VERSION ""

NS_ :

BS_:

BU_: EHR_Spare FEHR_3 PTO_SpeedSelector Dummy_Node_Ch2 FEHR_2 TrailerBrake OffBoardDiagnosticTool1_Ch2 PowerTakeOff_Ch2 Transmission1_Ch2 FEHR_1 REHR_5 REHR_4 REHR_3 REHR_2 REHR_1 InstrumentCluster_Ch2 ManagementComputer_Ch2 GWAY_OnBoardDiagnosticUnit_Ch2 GWAY_OffBoardDiagTool1_VB1_Ch2 GWAY_Engine1_Ch2 GWAY_CabDisplay1_Ch2 AuxiliaryValveControl_Ch2

BO_ 2566866052 PB_EHR_ParameterStatus_84: 8 REHR_5
 SG_ EHR_ChksumStor m80 : 32|8@1+ (1,0) [0|255] ""  AuxiliaryValveControl_Ch2
 SG_ EHR_ChksumSW m80 : 40|8@1+ (1,0) [0|255] ""  AuxiliaryValveControl_Ch2
 SG_ EHR_EvNumParamMux_12 : 24|8@1+ (1,0) [0|255] ""  AuxiliaryValveControl_Ch2
 SG_ EHR_ParamByte_1 : 0|8@1+ (1,0) [0|255] ""  AuxiliaryValveControl_Ch2
 SG_ EHR_ParamStsByte_2 : 8|8@1+ (1,0) [0|255] ""  AuxiliaryValveControl_Ch2
 SG_ EHR_ParamStsByte_3 M : 16|8@1+ (1,0) [0|255] ""  AuxiliaryValveControl_Ch2
 SG_ EHR_RmpRndng m103 : 32|8@1+ (1,0) [0|255] ""  AuxiliaryValveControl_Ch2

BO_ 2566866057 PB_EHR_ParameterStatus_89: 8 FEHR_1
 SG_ EHR_ChksumStor m80 : 32|8@1+ (1,0) [0|255] ""  AuxiliaryValveControl_Ch2
 SG_ EHR_ChksumSW m80 : 40|8@1+ (1,0) [0|255] ""  AuxiliaryValveControl_Ch2
 SG_ EHR_EvNumParamMux_12 : 24|8@1+ (1,0) [0|255] ""  AuxiliaryValveControl_Ch2
 SG_ EHR_ParamByte_1 : 0|8@1+ (1,0) [0|255] ""  AuxiliaryValveControl_Ch2
 SG_ EHR_ParamStsByte_2 : 8|8@1+ (1,0) [0|255] ""  AuxiliaryValveControl_Ch2
 SG_ EHR_ParamStsByte_3 M : 16|8@1+ (1,0) [0|255] ""  AuxiliaryValveControl_Ch2
 SG_ EHR_RmpRndng m103 : 32|8@1+ (1,0) [0|255] ""  AuxiliaryValveControl_Ch2

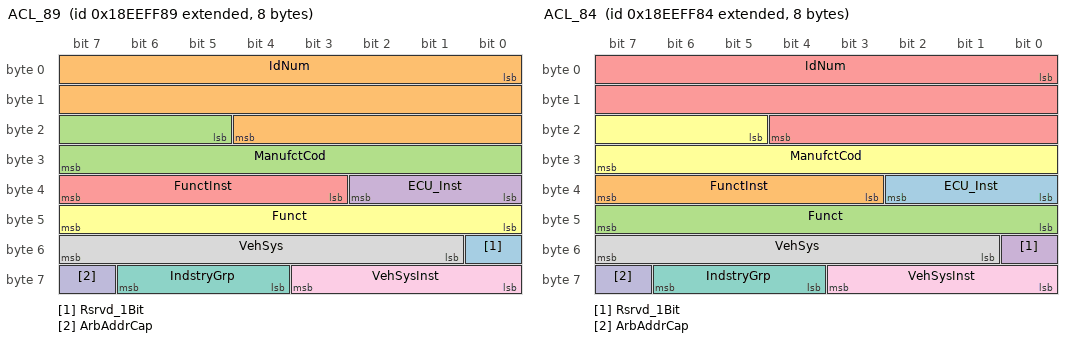
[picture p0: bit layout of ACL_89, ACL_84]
BO_ 2565799817 ACL_89: 8 FEHR_1
 SG_ Rsrvd_1Bit : 48|1@1+ (1,0) [0|1] ""  OffBoardDiagnosticTool1_Ch2,AuxiliaryValveControl_Ch2
 SG_ IdNum : 0|21@1+ (1,0) [0|2097151] ""  OffBoardDiagnosticTool1_Ch2,AuxiliaryValveControl_Ch2
 SG_ ManufctCod : 21|11@1+ (1,0) [0|2047] ""  OffBoardDiagnosticTool1_Ch2,AuxiliaryValveControl_Ch2
 SG_ ECU_Inst : 32|3@1+ (1,0) [0|7] ""  OffBoardDiagnosticTool1_Ch2,AuxiliaryValveControl_Ch2
 SG_ FunctInst : 35|5@1+ (1,0) [0|31] ""  OffBoardDiagnosticTool1_Ch2,AuxiliaryValveControl_Ch2
 SG_ Funct : 40|8@1+ (1,0) [0|255] ""  OffBoardDiagnosticTool1_Ch2,AuxiliaryValveControl_Ch2
 SG_ IndstryGrp : 60|3@1+ (1,0) [0|7] ""  OffBoardDiagnosticTool1_Ch2,AuxiliaryValveControl_Ch2
 SG_ VehSys : 49|7@1+ (1,0) [0|127] ""  OffBoardDiagnosticTool1_Ch2,AuxiliaryValveControl_Ch2
 SG_ VehSysInst : 56|4@1+ (1,0) [0|15] ""  OffBoardDiagnosticTool1_Ch2,AuxiliaryValveControl_Ch2
 SG_ ArbAddrCap : 63|1@1+ (1,0) [0|1] ""  OffBoardDiagnosticTool1_Ch2,AuxiliaryValveControl_Ch2

BO_ 2565799812 ACL_84: 8 REHR_5
 SG_ ECU_Inst : 32|3@1+ (1,0) [0|7] ""  OffBoardDiagnosticTool1_Ch2,AuxiliaryValveControl_Ch2
 SG_ FunctInst : 35|5@1+ (1,0) [0|31] ""  OffBoardDiagnosticTool1_Ch2,AuxiliaryValveControl_Ch2
 SG_ Funct : 40|8@1+ (1,0) [0|255] ""  OffBoardDiagnosticTool1_Ch2,AuxiliaryValveControl_Ch2
 SG_ Rsrvd_1Bit : 48|1@1+ (1,0) [0|1] ""  OffBoardDiagnosticTool1_Ch2,AuxiliaryValveControl_Ch2
 SG_ IdNum : 0|21@1+ (1,0) [0|2097151] ""  OffBoardDiagnosticTool1_Ch2,AuxiliaryValveControl_Ch2
 SG_ ManufctCod : 21|11@1+ (1,0) [0|2047] ""  OffBoardDiagnosticTool1_Ch2,AuxiliaryValveControl_Ch2
 SG_ IndstryGrp : 60|3@1+ (1,0) [0|7] ""  OffBoardDiagnosticTool1_Ch2,AuxiliaryValveControl_Ch2
 SG_ VehSys : 49|7@1+ (1,0) [0|127] ""  OffBoardDiagnosticTool1_Ch2,AuxiliaryValveControl_Ch2
 SG_ VehSysInst : 56|4@1+ (1,0) [0|15] ""  OffBoardDiagnosticTool1_Ch2,AuxiliaryValveControl_Ch2
 SG_ ArbAddrCap : 63|1@1+ (1,0) [0|1] ""  OffBoardDiagnosticTool1_Ch2,AuxiliaryValveControl_Ch2

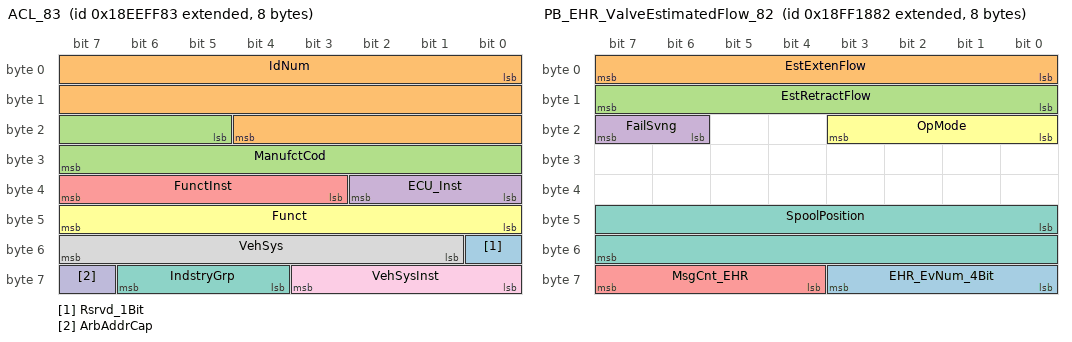
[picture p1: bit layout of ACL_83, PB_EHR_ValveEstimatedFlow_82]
BO_ 2565799811 ACL_83: 8 REHR_4
 SG_ Rsrvd_1Bit : 48|1@1+ (1,0) [0|1] ""  OffBoardDiagnosticTool1_Ch2,AuxiliaryValveControl_Ch2
 SG_ IdNum : 0|21@1+ (1,0) [0|2097151] ""  OffBoardDiagnosticTool1_Ch2,AuxiliaryValveControl_Ch2
 SG_ ManufctCod : 21|11@1+ (1,0) [0|2047] ""  OffBoardDiagnosticTool1_Ch2,AuxiliaryValveControl_Ch2
 SG_ ECU_Inst : 32|3@1+ (1,0) [0|7] ""  OffBoardDiagnosticTool1_Ch2,AuxiliaryValveControl_Ch2
 SG_ FunctInst : 35|5@1+ (1,0) [0|31] ""  OffBoardDiagnosticTool1_Ch2,AuxiliaryValveControl_Ch2
 SG_ Funct : 40|8@1+ (1,0) [0|255] ""  OffBoardDiagnosticTool1_Ch2,AuxiliaryValveControl_Ch2
 SG_ IndstryGrp : 60|3@1+ (1,0) [0|7] ""  OffBoardDiagnosticTool1_Ch2,AuxiliaryValveControl_Ch2
 SG_ VehSys : 49|7@1+ (1,0) [0|127] ""  OffBoardDiagnosticTool1_Ch2,AuxiliaryValveControl_Ch2
 SG_ VehSysInst : 56|4@1+ (1,0) [0|15] ""  OffBoardDiagnosticTool1_Ch2,AuxiliaryValveControl_Ch2
 SG_ ArbAddrCap : 63|1@1+ (1,0) [0|1] ""  OffBoardDiagnosticTool1_Ch2,AuxiliaryValveControl_Ch2

BO_ 2566854786 PB_EHR_ValveEstimatedFlow_82: 8 REHR_3
 SG_ EHR_EvNum_4Bit : 56|4@1+ (1,0) [0|15] ""  AuxiliaryValveControl_Ch2
 SG_ EstExtenFlow : 0|8@1+ (0.8,-102.4) [0|100] "%"  AuxiliaryValveControl_Ch2
 SG_ EstRetractFlow : 8|8@1+ (0.8,-102.4) [0|100] "%"  AuxiliaryValveControl_Ch2
 SG_ FailSvng : 22|2@1+ (1,0) [0|3] ""  AuxiliaryValveControl_Ch2
 SG_ MsgCnt_EHR : 60|4@1+ (1,0) [0|12] "count"  AuxiliaryValveControl_Ch2
 SG_ OpMode : 16|4@1+ (1,0) [0|15] ""  AuxiliaryValveControl_Ch2
 SG_ SpoolPosition : 40|16@1+ (1,0) [0|1023] ""  AuxiliaryValveControl_Ch2

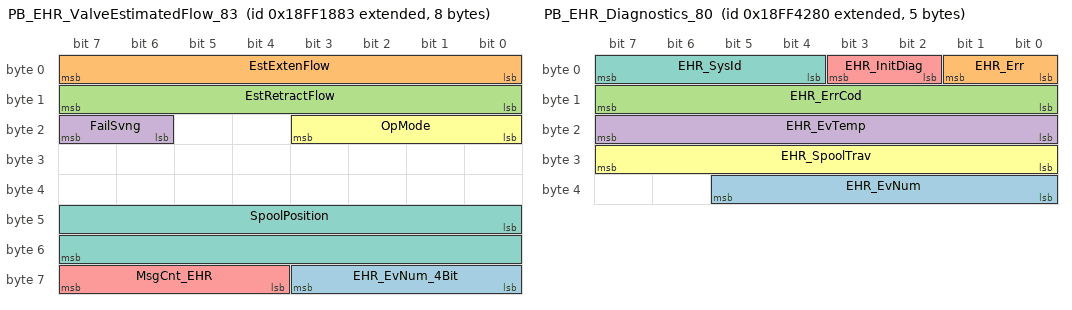
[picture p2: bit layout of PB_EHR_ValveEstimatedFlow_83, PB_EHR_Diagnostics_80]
BO_ 2566854787 PB_EHR_ValveEstimatedFlow_83: 8 REHR_4
 SG_ EHR_EvNum_4Bit : 56|4@1+ (1,0) [0|15] ""  AuxiliaryValveControl_Ch2
 SG_ EstExtenFlow : 0|8@1+ (0.8,-102.4) [0|100] "%"  AuxiliaryValveControl_Ch2
 SG_ EstRetractFlow : 8|8@1+ (0.8,-102.4) [0|100] "%"  AuxiliaryValveControl_Ch2
 SG_ FailSvng : 22|2@1+ (1,0) [0|3] ""  AuxiliaryValveControl_Ch2
 SG_ MsgCnt_EHR : 60|4@1+ (1,0) [0|12] "count"  AuxiliaryValveControl_Ch2
 SG_ OpMode : 16|4@1+ (1,0) [0|15] ""  AuxiliaryValveControl_Ch2
 SG_ SpoolPosition : 40|16@1+ (1,0) [0|1023] ""  AuxiliaryValveControl_Ch2

BO_ 2566865536 PB_EHR_Diagnostics_80: 5 REHR_1
 SG_ EHR_EvNum : 32|6@1+ (1,0) [0|63] ""  AuxiliaryValveControl_Ch2
 SG_ EHR_Err : 0|2@1+ (1,0) [0|3] ""  AuxiliaryValveControl_Ch2
 SG_ EHR_ErrCod : 8|8@1+ (1,0) [0|254] ""  AuxiliaryValveControl_Ch2
 SG_ EHR_EvTemp : 16|8@1+ (1,-80) [-40|120] "Deg C"  AuxiliaryValveControl_Ch2
 SG_ EHR_InitDiag : 2|2@1+ (1,0) [0|3] ""  AuxiliaryValveControl_Ch2
 SG_ EHR_SpoolTrav : 24|8@1+ (1,0) [0|254] ""  AuxiliaryValveControl_Ch2
 SG_ EHR_SysId : 4|4@1+ (1,0) [0|15] ""  AuxiliaryValveControl_Ch2

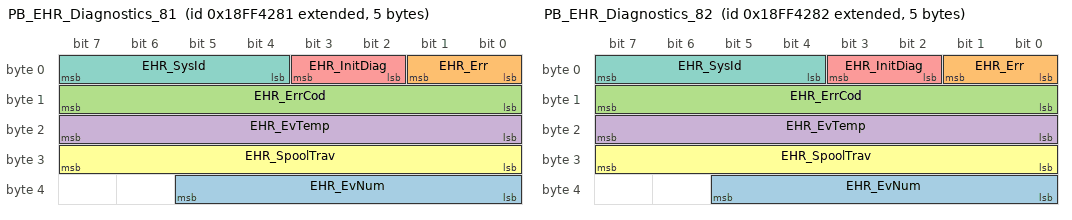
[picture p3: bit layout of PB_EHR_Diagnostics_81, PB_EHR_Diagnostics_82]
BO_ 2566865537 PB_EHR_Diagnostics_81: 5 REHR_2
 SG_ EHR_EvNum : 32|6@1+ (1,0) [0|63] ""  AuxiliaryValveControl_Ch2
 SG_ EHR_Err : 0|2@1+ (1,0) [0|3] ""  AuxiliaryValveControl_Ch2
 SG_ EHR_ErrCod : 8|8@1+ (1,0) [0|254] ""  AuxiliaryValveControl_Ch2
 SG_ EHR_EvTemp : 16|8@1+ (1,-80) [-40|120] "Deg C"  AuxiliaryValveControl_Ch2
 SG_ EHR_InitDiag : 2|2@1+ (1,0) [0|3] ""  AuxiliaryValveControl_Ch2
 SG_ EHR_SpoolTrav : 24|8@1+ (1,0) [0|254] ""  AuxiliaryValveControl_Ch2
 SG_ EHR_SysId : 4|4@1+ (1,0) [0|15] ""  AuxiliaryValveControl_Ch2

BO_ 2566865538 PB_EHR_Diagnostics_82: 5 REHR_3
 SG_ EHR_EvNum : 32|6@1+ (1,0) [0|63] ""  AuxiliaryValveControl_Ch2
 SG_ EHR_Err : 0|2@1+ (1,0) [0|3] ""  AuxiliaryValveControl_Ch2
 SG_ EHR_ErrCod : 8|8@1+ (1,0) [0|254] ""  AuxiliaryValveControl_Ch2
 SG_ EHR_EvTemp : 16|8@1+ (1,-80) [-40|120] "Deg C"  AuxiliaryValveControl_Ch2
 SG_ EHR_InitDiag : 2|2@1+ (1,0) [0|3] ""  AuxiliaryValveControl_Ch2
 SG_ EHR_SpoolTrav : 24|8@1+ (1,0) [0|254] ""  AuxiliaryValveControl_Ch2
 SG_ EHR_SysId : 4|4@1+ (1,0) [0|15] ""  AuxiliaryValveControl_Ch2

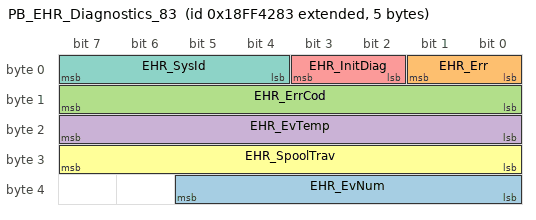
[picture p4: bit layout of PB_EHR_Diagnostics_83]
BO_ 2566865539 PB_EHR_Diagnostics_83: 5 REHR_4
 SG_ EHR_EvNum : 32|6@1+ (1,0) [0|63] ""  AuxiliaryValveControl_Ch2
 SG_ EHR_Err : 0|2@1+ (1,0) [0|3] ""  AuxiliaryValveControl_Ch2
 SG_ EHR_ErrCod : 8|8@1+ (1,0) [0|254] ""  AuxiliaryValveControl_Ch2
 SG_ EHR_EvTemp : 16|8@1+ (1,-80) [-40|120] "Deg C"  AuxiliaryValveControl_Ch2
 SG_ EHR_InitDiag : 2|2@1+ (1,0) [0|3] ""  AuxiliaryValveControl_Ch2
 SG_ EHR_SpoolTrav : 24|8@1+ (1,0) [0|254] ""  AuxiliaryValveControl_Ch2
 SG_ EHR_SysId : 4|4@1+ (1,0) [0|15] ""  AuxiliaryValveControl_Ch2

BO_ 2566834816 DM1_80: 18 REHR_1
 SG_ DTC_02 : 48|32@1+ (1,0) [0|4294970000] ""  InstrumentCluster_Ch2
 SG_ DTC_03 : 80|32@1+ (1,0) [0|4294970000] ""  InstrumentCluster_Ch2
 SG_ DTC_04 : 112|32@1+ (1,0) [0|4294970000] ""  InstrumentCluster_Ch2
 SG_ AmbrWarnLmp : 2|2@1+ (1,0) [0|3] ""  InstrumentCluster_Ch2,AuxiliaryValveControl_Ch2
 SG_ DTC_01 : 16|32@1+ (1,0) [0|4294970000] ""  InstrumentCluster_Ch2,AuxiliaryValveControl_Ch2
 SG_ FlashAmbrWarnLmpAWL : 10|2@1+ (1,0) [0|3] ""  InstrumentCluster_Ch2,AuxiliaryValveControl_Ch2
 SG_ FlashMIL : 14|2@1+ (1,0) [0|3] ""  InstrumentCluster_Ch2,AuxiliaryValveControl_Ch2
 SG_ FlashProtLmp : 8|2@1+ (1,0) [0|3] ""  InstrumentCluster_Ch2,AuxiliaryValveControl_Ch2
 SG_ FlashRedStopLmpRSL : 12|2@1+ (1,0) [0|3] ""  InstrumentCluster_Ch2,AuxiliaryValveControl_Ch2
 SG_ MIL : 6|2@1+ (1,0) [0|3] ""  InstrumentCluster_Ch2,AuxiliaryValveControl_Ch2
 SG_ ProtLmp : 0|2@1+ (1,0) [0|3] ""  InstrumentCluster_Ch2,AuxiliaryValveControl_Ch2
 SG_ RedStopLmp : 4|2@1+ (1,0) [0|3] ""  InstrumentCluster_Ch2,AuxiliaryValveControl_Ch2

BO_ 2566834817 DM1_81: 18 REHR_2
 SG_ DTC_02 : 48|32@1+ (1,0) [0|4294970000] ""  InstrumentCluster_Ch2
 SG_ DTC_03 : 80|32@1+ (1,0) [0|4294970000] ""  InstrumentCluster_Ch2
 SG_ DTC_04 : 112|32@1+ (1,0) [0|4294970000] ""  InstrumentCluster_Ch2
 SG_ AmbrWarnLmp : 2|2@1+ (1,0) [0|3] ""  InstrumentCluster_Ch2,AuxiliaryValveControl_Ch2
 SG_ DTC_01 : 16|32@1+ (1,0) [0|4294970000] ""  InstrumentCluster_Ch2,AuxiliaryValveControl_Ch2
 SG_ FlashAmbrWarnLmpAWL : 10|2@1+ (1,0) [0|3] ""  InstrumentCluster_Ch2,AuxiliaryValveControl_Ch2
 SG_ FlashMIL : 14|2@1+ (1,0) [0|3] ""  InstrumentCluster_Ch2,AuxiliaryValveControl_Ch2
 SG_ FlashProtLmp : 8|2@1+ (1,0) [0|3] ""  InstrumentCluster_Ch2,AuxiliaryValveControl_Ch2
 SG_ FlashRedStopLmpRSL : 12|2@1+ (1,0) [0|3] ""  InstrumentCluster_Ch2,AuxiliaryValveControl_Ch2
 SG_ MIL : 6|2@1+ (1,0) [0|3] ""  InstrumentCluster_Ch2,AuxiliaryValveControl_Ch2
 SG_ ProtLmp : 0|2@1+ (1,0) [0|3] ""  InstrumentCluster_Ch2,AuxiliaryValveControl_Ch2
 SG_ RedStopLmp : 4|2@1+ (1,0) [0|3] ""  InstrumentCluster_Ch2,AuxiliaryValveControl_Ch2

BO_ 2566834818 DM1_82: 18 REHR_3
 SG_ DTC_02 : 48|32@1+ (1,0) [0|4294970000] ""  InstrumentCluster_Ch2
 SG_ DTC_03 : 80|32@1+ (1,0) [0|4294970000] ""  InstrumentCluster_Ch2
 SG_ DTC_04 : 112|32@1+ (1,0) [0|4294970000] ""  InstrumentCluster_Ch2
 SG_ RedStopLmp : 4|2@1+ (1,0) [0|3] ""  InstrumentCluster_Ch2,AuxiliaryValveControl_Ch2
 SG_ AmbrWarnLmp : 2|2@1+ (1,0) [0|3] ""  InstrumentCluster_Ch2,AuxiliaryValveControl_Ch2
 SG_ DTC_01 : 16|32@1+ (1,0) [0|4294970000] ""  InstrumentCluster_Ch2,AuxiliaryValveControl_Ch2
 SG_ FlashAmbrWarnLmpAWL : 10|2@1+ (1,0) [0|3] ""  InstrumentCluster_Ch2,AuxiliaryValveControl_Ch2
 SG_ FlashMIL : 14|2@1+ (1,0) [0|3] ""  InstrumentCluster_Ch2,AuxiliaryValveControl_Ch2
 SG_ FlashProtLmp : 8|2@1+ (1,0) [0|3] ""  InstrumentCluster_Ch2,AuxiliaryValveControl_Ch2
 SG_ FlashRedStopLmpRSL : 12|2@1+ (1,0) [0|3] ""  InstrumentCluster_Ch2,AuxiliaryValveControl_Ch2
 SG_ MIL : 6|2@1+ (1,0) [0|3] ""  InstrumentCluster_Ch2,AuxiliaryValveControl_Ch2
 SG_ ProtLmp : 0|2@1+ (1,0) [0|3] ""  InstrumentCluster_Ch2,AuxiliaryValveControl_Ch2

BO_ 2566834819 DM1_83: 18 REHR_4
 SG_ DTC_02 : 48|32@1+ (1,0) [0|4294970000] ""  InstrumentCluster_Ch2
 SG_ DTC_03 : 80|32@1+ (1,0) [0|4294970000] ""  InstrumentCluster_Ch2
 SG_ DTC_04 : 112|32@1+ (1,0) [0|4294970000] ""  InstrumentCluster_Ch2
 SG_ AmbrWarnLmp : 2|2@1+ (1,0) [0|3] ""  InstrumentCluster_Ch2,AuxiliaryValveControl_Ch2
 SG_ DTC_01 : 16|32@1+ (1,0) [0|4294970000] ""  InstrumentCluster_Ch2,AuxiliaryValveControl_Ch2
 SG_ FlashAmbrWarnLmpAWL : 10|2@1+ (1,0) [0|3] ""  InstrumentCluster_Ch2,AuxiliaryValveControl_Ch2
 SG_ FlashMIL : 14|2@1+ (1,0) [0|3] ""  InstrumentCluster_Ch2,AuxiliaryValveControl_Ch2
 SG_ FlashProtLmp : 8|2@1+ (1,0) [0|3] ""  InstrumentCluster_Ch2,AuxiliaryValveControl_Ch2
 SG_ FlashRedStopLmpRSL : 12|2@1+ (1,0) [0|3] ""  InstrumentCluster_Ch2,AuxiliaryValveControl_Ch2
 SG_ MIL : 6|2@1+ (1,0) [0|3] ""  InstrumentCluster_Ch2,AuxiliaryValveControl_Ch2
 SG_ ProtLmp : 0|2@1+ (1,0) [0|3] ""  InstrumentCluster_Ch2,AuxiliaryValveControl_Ch2
 SG_ RedStopLmp : 4|2@1+ (1,0) [0|3] ""  InstrumentCluster_Ch2,AuxiliaryValveControl_Ch2

BO_ 2632712064 TPDT_80: 8 REHR_1
 SG_ PktDataTPDT : 8|56@1+ (1,0) [0|7.20575940379279E+16] ""  InstrumentCluster_Ch2,AuxiliaryValveControl_Ch2
 SG_ SN_TPDT : 0|8@1+ (1,0) [0|255] ""  InstrumentCluster_Ch2,AuxiliaryValveControl_Ch2

BO_ 2632712065 TPDT_81: 8 REHR_2
 SG_ PktDataTPDT : 8|56@1+ (1,0) [0|7.20575940379279E+16] ""  InstrumentCluster_Ch2,AuxiliaryValveControl_Ch2
 SG_ SN_TPDT : 0|8@1+ (1,0) [0|255] ""  InstrumentCluster_Ch2,AuxiliaryValveControl_Ch2

BO_ 2632712067 TPDT_83: 8 REHR_4
 SG_ PktDataTPDT : 8|56@1+ (1,0) [0|7.20575940379279E+16] ""  InstrumentCluster_Ch2,AuxiliaryValveControl_Ch2
 SG_ SN_TPDT : 0|8@1+ (1,0) [0|255] ""  InstrumentCluster_Ch2,AuxiliaryValveControl_Ch2

BO_ 2632712066 TPDT_82: 8 REHR_3
 SG_ PktDataTPDT : 8|56@1+ (1,0) [0|7.20575940379279E+16] ""  InstrumentCluster_Ch2,AuxiliaryValveControl_Ch2
 SG_ SN_TPDT : 0|8@1+ (1,0) [0|255] ""  InstrumentCluster_Ch2,AuxiliaryValveControl_Ch2

BO_ 2632777600 TPCM_80: 8 REHR_1
 SG_ ConnAbrtReason m255 : 8|8@1+ (1,0) [0|255] ""  InstrumentCluster_Ch2,AuxiliaryValveControl_Ch2
 SG_ MaxNumPktTPCM_RTS m16 : 32|8@1+ (1,0) [0|255] ""  InstrumentCluster_Ch2,AuxiliaryValveControl_Ch2
 SG_ NumPktSentTPCM_CTS m17 : 8|8@1+ (1,0) [0|255] ""  InstrumentCluster_Ch2,AuxiliaryValveControl_Ch2
 SG_ NxtPktNumSentTPCM_CTS m17 : 16|8@1+ (1,0) [0|255] ""  InstrumentCluster_Ch2,AuxiliaryValveControl_Ch2
 SG_ PGN_PktMsgTPCM_BAM m32 : 40|24@1+ (1,0) [0|16777200] ""  InstrumentCluster_Ch2,AuxiliaryValveControl_Ch2
 SG_ PGN_PktMsgTPCM_ConnAbort m255 : 40|24@1+ (1,0) [0|16777200] ""  InstrumentCluster_Ch2,AuxiliaryValveControl_Ch2
 SG_ PGN_PktMsgTPCM_CTS m17 : 40|24@1+ (1,0) [0|16777200] ""  InstrumentCluster_Ch2,AuxiliaryValveControl_Ch2
 SG_ PGN_PktMsgTPCM_RTS m16 : 40|24@1+ (1,0) [0|16777200] ""  InstrumentCluster_Ch2,AuxiliaryValveControl_Ch2
 SG_ PGN_PktMsgTPCM_RTS2 m19 : 40|24@1+ (1,0) [0|16777200] ""  InstrumentCluster_Ch2,AuxiliaryValveControl_Ch2
 SG_ TotMsgSizeBAM m32 : 8|16@1+ (1,0) [0|64255] "counts"  InstrumentCluster_Ch2,AuxiliaryValveControl_Ch2
 SG_ TotMsgSizeEoMA m19 : 8|16@1+ (1,0) [0|64255] "counts"  InstrumentCluster_Ch2,AuxiliaryValveControl_Ch2
 SG_ TotMsgSizeTPCM_RTS m16 : 8|16@1+ (1,0) [0|64255] "counts"  InstrumentCluster_Ch2,AuxiliaryValveControl_Ch2
 SG_ TotNumPktBAM m32 : 24|8@1+ (1,0) [0|255] ""  InstrumentCluster_Ch2,AuxiliaryValveControl_Ch2
 SG_ TotNumPktEoMA m19 : 24|8@1+ (1,0) [0|255] ""  InstrumentCluster_Ch2,AuxiliaryValveControl_Ch2
 SG_ TotNumPktTPCM_RTS m16 : 24|8@1+ (1,0) [0|255] ""  InstrumentCluster_Ch2,AuxiliaryValveControl_Ch2
 SG_ CByteTPCM M : 0|8@1+ (1,0) [0|255] ""  InstrumentCluster_Ch2,AuxiliaryValveControl_Ch2

BO_ 2632777601 TPCM_81: 8 REHR_2
 SG_ ConnAbrtReason m255 : 8|8@1+ (1,0) [0|255] ""  InstrumentCluster_Ch2,AuxiliaryValveControl_Ch2
 SG_ MaxNumPktTPCM_RTS m16 : 32|8@1+ (1,0) [0|255] ""  InstrumentCluster_Ch2,AuxiliaryValveControl_Ch2
 SG_ NumPktSentTPCM_CTS m17 : 8|8@1+ (1,0) [0|255] ""  InstrumentCluster_Ch2,AuxiliaryValveControl_Ch2
 SG_ NxtPktNumSentTPCM_CTS m17 : 16|8@1+ (1,0) [0|255] ""  InstrumentCluster_Ch2,AuxiliaryValveControl_Ch2
 SG_ PGN_PktMsgTPCM_BAM m32 : 40|24@1+ (1,0) [0|16777200] ""  InstrumentCluster_Ch2,AuxiliaryValveControl_Ch2
 SG_ PGN_PktMsgTPCM_ConnAbort m255 : 40|24@1+ (1,0) [0|16777200] ""  InstrumentCluster_Ch2,AuxiliaryValveControl_Ch2
 SG_ PGN_PktMsgTPCM_CTS m17 : 40|24@1+ (1,0) [0|16777200] ""  InstrumentCluster_Ch2,AuxiliaryValveControl_Ch2
 SG_ PGN_PktMsgTPCM_RTS m16 : 40|24@1+ (1,0) [0|16777200] ""  InstrumentCluster_Ch2,AuxiliaryValveControl_Ch2
 SG_ PGN_PktMsgTPCM_RTS2 m19 : 40|24@1+ (1,0) [0|16777200] ""  InstrumentCluster_Ch2,AuxiliaryValveControl_Ch2
 SG_ TotMsgSizeBAM m32 : 8|16@1+ (1,0) [0|64255] "counts"  InstrumentCluster_Ch2,AuxiliaryValveControl_Ch2
 SG_ TotMsgSizeEoMA m19 : 8|16@1+ (1,0) [0|64255] "counts"  InstrumentCluster_Ch2,AuxiliaryValveControl_Ch2
 SG_ TotMsgSizeTPCM_RTS m16 : 8|16@1+ (1,0) [0|64255] "counts"  InstrumentCluster_Ch2,AuxiliaryValveControl_Ch2
 SG_ TotNumPktBAM m32 : 24|8@1+ (1,0) [0|255] ""  InstrumentCluster_Ch2,AuxiliaryValveControl_Ch2
 SG_ TotNumPktEoMA m19 : 24|8@1+ (1,0) [0|255] ""  InstrumentCluster_Ch2,AuxiliaryValveControl_Ch2
 SG_ TotNumPktTPCM_RTS m16 : 24|8@1+ (1,0) [0|255] ""  InstrumentCluster_Ch2,AuxiliaryValveControl_Ch2
 SG_ CByteTPCM M : 0|8@1+ (1,0) [0|255] ""  InstrumentCluster_Ch2,AuxiliaryValveControl_Ch2

BO_ 2632777602 TPCM_82: 8 REHR_3
 SG_ ConnAbrtReason m255 : 8|8@1+ (1,0) [0|255] ""  InstrumentCluster_Ch2,AuxiliaryValveControl_Ch2
 SG_ MaxNumPktTPCM_RTS m16 : 32|8@1+ (1,0) [0|255] ""  InstrumentCluster_Ch2,AuxiliaryValveControl_Ch2
 SG_ NumPktSentTPCM_CTS m17 : 8|8@1+ (1,0) [0|255] ""  InstrumentCluster_Ch2,AuxiliaryValveControl_Ch2
 SG_ NxtPktNumSentTPCM_CTS m17 : 16|8@1+ (1,0) [0|255] ""  InstrumentCluster_Ch2,AuxiliaryValveControl_Ch2
 SG_ PGN_PktMsgTPCM_BAM m32 : 40|24@1+ (1,0) [0|16777200] ""  InstrumentCluster_Ch2,AuxiliaryValveControl_Ch2
 SG_ PGN_PktMsgTPCM_ConnAbort m255 : 40|24@1+ (1,0) [0|16777200] ""  InstrumentCluster_Ch2,AuxiliaryValveControl_Ch2
 SG_ PGN_PktMsgTPCM_CTS m17 : 40|24@1+ (1,0) [0|16777200] ""  InstrumentCluster_Ch2,AuxiliaryValveControl_Ch2
 SG_ PGN_PktMsgTPCM_RTS m16 : 40|24@1+ (1,0) [0|16777200] ""  InstrumentCluster_Ch2,AuxiliaryValveControl_Ch2
 SG_ PGN_PktMsgTPCM_RTS2 m19 : 40|24@1+ (1,0) [0|16777200] ""  InstrumentCluster_Ch2,AuxiliaryValveControl_Ch2
 SG_ TotMsgSizeBAM m32 : 8|16@1+ (1,0) [0|64255] "counts"  InstrumentCluster_Ch2,AuxiliaryValveControl_Ch2
 SG_ TotMsgSizeEoMA m19 : 8|16@1+ (1,0) [0|64255] "counts"  InstrumentCluster_Ch2,AuxiliaryValveControl_Ch2
 SG_ TotMsgSizeTPCM_RTS m16 : 8|16@1+ (1,0) [0|64255] "counts"  InstrumentCluster_Ch2,AuxiliaryValveControl_Ch2
 SG_ TotNumPktBAM m32 : 24|8@1+ (1,0) [0|255] ""  InstrumentCluster_Ch2,AuxiliaryValveControl_Ch2
 SG_ TotNumPktEoMA m19 : 24|8@1+ (1,0) [0|255] ""  InstrumentCluster_Ch2,AuxiliaryValveControl_Ch2
 SG_ TotNumPktTPCM_RTS m16 : 24|8@1+ (1,0) [0|255] ""  InstrumentCluster_Ch2,AuxiliaryValveControl_Ch2
 SG_ CByteTPCM M : 0|8@1+ (1,0) [0|255] ""  InstrumentCluster_Ch2,AuxiliaryValveControl_Ch2

BO_ 2632777603 TPCM_83: 8 REHR_4
 SG_ ConnAbrtReason m255 : 8|8@1+ (1,0) [0|255] ""  InstrumentCluster_Ch2,AuxiliaryValveControl_Ch2
 SG_ MaxNumPktTPCM_RTS m16 : 32|8@1+ (1,0) [0|255] ""  InstrumentCluster_Ch2,AuxiliaryValveControl_Ch2
 SG_ NumPktSentTPCM_CTS m17 : 8|8@1+ (1,0) [0|255] ""  InstrumentCluster_Ch2,AuxiliaryValveControl_Ch2
 SG_ NxtPktNumSentTPCM_CTS m17 : 16|8@1+ (1,0) [0|255] ""  InstrumentCluster_Ch2,AuxiliaryValveControl_Ch2
 SG_ PGN_PktMsgTPCM_BAM m32 : 40|24@1+ (1,0) [0|16777200] ""  InstrumentCluster_Ch2,AuxiliaryValveControl_Ch2
 SG_ PGN_PktMsgTPCM_ConnAbort m255 : 40|24@1+ (1,0) [0|16777200] ""  InstrumentCluster_Ch2,AuxiliaryValveControl_Ch2
 SG_ PGN_PktMsgTPCM_CTS m17 : 40|24@1+ (1,0) [0|16777200] ""  InstrumentCluster_Ch2,AuxiliaryValveControl_Ch2
 SG_ PGN_PktMsgTPCM_RTS m16 : 40|24@1+ (1,0) [0|16777200] ""  InstrumentCluster_Ch2,AuxiliaryValveControl_Ch2
 SG_ PGN_PktMsgTPCM_RTS2 m19 : 40|24@1+ (1,0) [0|16777200] ""  InstrumentCluster_Ch2,AuxiliaryValveControl_Ch2
 SG_ TotMsgSizeBAM m32 : 8|16@1+ (1,0) [0|64255] "counts"  InstrumentCluster_Ch2,AuxiliaryValveControl_Ch2
 SG_ TotMsgSizeEoMA m19 : 8|16@1+ (1,0) [0|64255] "counts"  InstrumentCluster_Ch2,AuxiliaryValveControl_Ch2
 SG_ TotMsgSizeTPCM_RTS m16 : 8|16@1+ (1,0) [0|64255] "counts"  InstrumentCluster_Ch2,AuxiliaryValveControl_Ch2
 SG_ TotNumPktBAM m32 : 24|8@1+ (1,0) [0|255] ""  InstrumentCluster_Ch2,AuxiliaryValveControl_Ch2
 SG_ TotNumPktEoMA m19 : 24|8@1+ (1,0) [0|255] ""  InstrumentCluster_Ch2,AuxiliaryValveControl_Ch2
 SG_ TotNumPktTPCM_RTS m16 : 24|8@1+ (1,0) [0|255] ""  InstrumentCluster_Ch2,AuxiliaryValveControl_Ch2
 SG_ CByteTPCM M : 0|8@1+ (1,0) [0|255] ""  InstrumentCluster_Ch2,AuxiliaryValveControl_Ch2

BO_ 2565350016 ACKM_80_22: 8 REHR_1
 SG_ AddrAccssDeny m2 : 32|8@1+ (1,0) [0|255] ""  AuxiliaryValveControl_Ch2
 SG_ AddrAck m0 : 32|8@1+ (1,0) [0|255] ""  AuxiliaryValveControl_Ch2
 SG_ AddrBusy m3 : 32|8@1+ (1,0) [0|255] ""  AuxiliaryValveControl_Ch2
 SG_ AddrNegAck m1 : 32|8@1+ (1,0) [0|255] ""  AuxiliaryValveControl_Ch2
 SG_ GrpFunctValAck m0 : 8|8@1+ (1,0) [0|255] ""  AuxiliaryValveControl_Ch2
 SG_ GrpFunctValNAck m1 : 8|8@1+ (1,0) [0|255] ""  AuxiliaryValveControl_Ch2
 SG_ GrpFunctValNAckAd m2 : 8|8@1+ (1,0) [0|255] ""  AuxiliaryValveControl_Ch2
 SG_ GrpFunctValNAckBusy m3 : 8|8@1+ (1,0) [0|255] ""  AuxiliaryValveControl_Ch2
 SG_ PGN_Ack m0 : 40|24@1+ (1,0) [0|16777200] ""  AuxiliaryValveControl_Ch2
 SG_ PGN_NAck m1 : 40|24@1+ (1,0) [0|16777200] ""  AuxiliaryValveControl_Ch2
 SG_ PGN_NAckAd m2 : 40|24@1+ (1,0) [0|16777200] ""  AuxiliaryValveControl_Ch2
 SG_ PGN_NAckBusy m3 : 40|24@1+ (1,0) [0|16777200] ""  AuxiliaryValveControl_Ch2
 SG_ CByteAckm M : 0|8@1+ (1,0) [0|255] ""  AuxiliaryValveControl_Ch2

BO_ 2565350017 ACKM_81_22: 8 REHR_2
 SG_ AddrAccssDeny m2 : 32|8@1+ (1,0) [0|255] ""  AuxiliaryValveControl_Ch2
 SG_ AddrAck m0 : 32|8@1+ (1,0) [0|255] ""  AuxiliaryValveControl_Ch2
 SG_ AddrBusy m3 : 32|8@1+ (1,0) [0|255] ""  AuxiliaryValveControl_Ch2
 SG_ AddrNegAck m1 : 32|8@1+ (1,0) [0|255] ""  AuxiliaryValveControl_Ch2
 SG_ GrpFunctValAck m0 : 8|8@1+ (1,0) [0|255] ""  AuxiliaryValveControl_Ch2
 SG_ GrpFunctValNAck m1 : 8|8@1+ (1,0) [0|255] ""  AuxiliaryValveControl_Ch2
 SG_ GrpFunctValNAckAd m2 : 8|8@1+ (1,0) [0|255] ""  AuxiliaryValveControl_Ch2
 SG_ GrpFunctValNAckBusy m3 : 8|8@1+ (1,0) [0|255] ""  AuxiliaryValveControl_Ch2
 SG_ PGN_Ack m0 : 40|24@1+ (1,0) [0|16777200] ""  AuxiliaryValveControl_Ch2
 SG_ PGN_NAck m1 : 40|24@1+ (1,0) [0|16777200] ""  AuxiliaryValveControl_Ch2
 SG_ PGN_NAckAd m2 : 40|24@1+ (1,0) [0|16777200] ""  AuxiliaryValveControl_Ch2
 SG_ PGN_NAckBusy m3 : 40|24@1+ (1,0) [0|16777200] ""  AuxiliaryValveControl_Ch2
 SG_ CByteAckm M : 0|8@1+ (1,0) [0|255] ""  AuxiliaryValveControl_Ch2

BO_ 2565350018 ACKM_82_22: 8 REHR_3
 SG_ AddrAccssDeny m2 : 32|8@1+ (1,0) [0|255] ""  AuxiliaryValveControl_Ch2
 SG_ AddrAck m0 : 32|8@1+ (1,0) [0|255] ""  AuxiliaryValveControl_Ch2
 SG_ AddrBusy m3 : 32|8@1+ (1,0) [0|255] ""  AuxiliaryValveControl_Ch2
 SG_ AddrNegAck m1 : 32|8@1+ (1,0) [0|255] ""  AuxiliaryValveControl_Ch2
 SG_ GrpFunctValAck m0 : 8|8@1+ (1,0) [0|255] ""  AuxiliaryValveControl_Ch2
 SG_ GrpFunctValNAck m1 : 8|8@1+ (1,0) [0|255] ""  AuxiliaryValveControl_Ch2
 SG_ GrpFunctValNAckAd m2 : 8|8@1+ (1,0) [0|255] ""  AuxiliaryValveControl_Ch2
 SG_ GrpFunctValNAckBusy m3 : 8|8@1+ (1,0) [0|255] ""  AuxiliaryValveControl_Ch2
 SG_ PGN_Ack m0 : 40|24@1+ (1,0) [0|16777200] ""  AuxiliaryValveControl_Ch2
 SG_ PGN_NAck m1 : 40|24@1+ (1,0) [0|16777200] ""  AuxiliaryValveControl_Ch2
 SG_ PGN_NAckAd m2 : 40|24@1+ (1,0) [0|16777200] ""  AuxiliaryValveControl_Ch2
 SG_ PGN_NAckBusy m3 : 40|24@1+ (1,0) [0|16777200] ""  AuxiliaryValveControl_Ch2
 SG_ CByteAckm M : 0|8@1+ (1,0) [0|255] ""  AuxiliaryValveControl_Ch2

BO_ 2565350019 ACKM_83_22: 8 REHR_4
 SG_ AddrAccssDeny m2 : 32|8@1+ (1,0) [0|255] ""  AuxiliaryValveControl_Ch2
 SG_ AddrAck m0 : 32|8@1+ (1,0) [0|255] ""  AuxiliaryValveControl_Ch2
 SG_ AddrBusy m3 : 32|8@1+ (1,0) [0|255] ""  AuxiliaryValveControl_Ch2
 SG_ AddrNegAck m1 : 32|8@1+ (1,0) [0|255] ""  AuxiliaryValveControl_Ch2
 SG_ GrpFunctValAck m0 : 8|8@1+ (1,0) [0|255] ""  AuxiliaryValveControl_Ch2
 SG_ GrpFunctValNAck m1 : 8|8@1+ (1,0) [0|255] ""  AuxiliaryValveControl_Ch2
 SG_ GrpFunctValNAckAd m2 : 8|8@1+ (1,0) [0|255] ""  AuxiliaryValveControl_Ch2
 SG_ GrpFunctValNAckBusy m3 : 8|8@1+ (1,0) [0|255] ""  AuxiliaryValveControl_Ch2
 SG_ PGN_Ack m0 : 40|24@1+ (1,0) [0|16777200] ""  AuxiliaryValveControl_Ch2
 SG_ PGN_NAck m1 : 40|24@1+ (1,0) [0|16777200] ""  AuxiliaryValveControl_Ch2
 SG_ PGN_NAckAd m2 : 40|24@1+ (1,0) [0|16777200] ""  AuxiliaryValveControl_Ch2
 SG_ PGN_NAckBusy m3 : 40|24@1+ (1,0) [0|16777200] ""  AuxiliaryValveControl_Ch2
 SG_ CByteAckm M : 0|8@1+ (1,0) [0|255] ""  AuxiliaryValveControl_Ch2

CM_ BO_ 2566866052 "The message is used 'On event' to configure the valves. Every byte not used, to be set 0xFF.";
CM_ SG_ 2566866052 EHR_ChksumSW "Calculated checksum of the application software.";
CM_ SG_ 2566866052 EHR_EvNumParamMux_12 "A status signal indicating the EHR valve number. Used for front & rear EHR's.";
CM_ SG_ 2566866052 EHR_ParamStsByte_2 "The signal has a fix value 0x3B";
CM_ SG_ 2566866052 EHR_RmpRndng "A status signal indicating the EHR valve number. Used for front & rear EHR's.";
CM_ BO_ 2566866057 "The message is used 'On event' to configure the valves. Every byte not used, to be set 0xFF.";
CM_ SG_ 2566866057 EHR_ChksumSW "Calculated checksum of the application software.";
CM_ SG_ 2566866057 EHR_EvNumParamMux_12 "A status signal indicating the EHR valve number. Used for front & rear EHR's.";
CM_ SG_ 2566866057 EHR_ParamStsByte_2 "The signal has a fix value 0x3B";
CM_ SG_ 2566866057 EHR_RmpRndng "A status signal indicating the EHR valve number. Used for front & rear EHR's.";
CM_ BO_ 2565799817 "Address Claimed";
CM_ SG_ 2565799817 Rsrvd_1Bit "Set to 0 for J1939-81";
CM_ BO_ 2565799812 "Address Claimed";
CM_ SG_ 2565799812 Rsrvd_1Bit "Set to 0 for J1939-81";
CM_ BO_ 2565799811 "Address Claimed";
CM_ SG_ 2565799811 Rsrvd_1Bit "Set to 0 for J1939-81";
CM_ SG_ 2566854786 MsgCnt_EHR "Initial Value 12. Counts from 0 to 11 and then back to 0. 12, 13 are reserved, 14 error, 15 NA. Tecnord EHR Only";
CM_ SG_ 2566854786 SpoolPosition "Spool position of the valve (only for Technord EHR).";
CM_ SG_ 2566854787 MsgCnt_EHR "Initial Value 12. Counts from 0 to 11 and then back to 0. 12, 13 are reserved, 14 error, 15 NA. Tecnord EHR Only";
CM_ SG_ 2566854787 SpoolPosition "Spool position of the valve (only for Technord EHR).";
CM_ BO_ 2566865536 "During engine cranking, all diagnostics checks shall be disabled to avoid reporting of spurious error. Engine cranking is indicated by ‘init’ parameter in Ehr Control message.";
CM_ SG_ 2566865536 EHR_Err "A status signal indicating the EHR fault condition. Sent by both front & rear EHR's.";
CM_ SG_ 2566865536 EHR_ErrCod "A status value to indicate the EHR fault code. Used for front & rear EHR's.";
CM_ SG_ 2566865536 EHR_EvTemp "A measured value to indicate the EHR valve temperature. Used for front & rear EHR's.";
CM_ SG_ 2566865536 EHR_InitDiag "A status signal indicating the EHR fault condition. Sent by both front & rear EHR's.";
CM_ SG_ 2566865536 EHR_SysId "NOT USED";
CM_ BO_ 2566865537 "During engine cranking, all diagnostics checks shall be disabled to avoid reporting of spurious error. Engine cranking is indicated by ‘init’ parameter in Ehr Control message.";
CM_ SG_ 2566865537 EHR_Err "A status signal indicating the EHR fault condition. Sent by both front & rear EHR's.";
CM_ SG_ 2566865537 EHR_ErrCod "A status value to indicate the EHR fault code. Used for front & rear EHR's.";
CM_ SG_ 2566865537 EHR_EvTemp "A measured value to indicate the EHR valve temperature. Used for front & rear EHR's.";
CM_ SG_ 2566865537 EHR_InitDiag "A status signal indicating the EHR fault condition. Sent by both front & rear EHR's.";
CM_ SG_ 2566865537 EHR_SysId "NOT USED";
CM_ BO_ 2566865538 "During engine cranking, all diagnostics checks shall be disabled to avoid reporting of spurious error. Engine cranking is indicated by ‘init’ parameter in Ehr Control message.";
CM_ SG_ 2566865538 EHR_Err "A status signal indicating the EHR fault condition. Sent by both front & rear EHR's.";
CM_ SG_ 2566865538 EHR_ErrCod "A status value to indicate the EHR fault code. Used for front & rear EHR's.";
CM_ SG_ 2566865538 EHR_EvTemp "A measured value to indicate the EHR valve temperature. Used for front & rear EHR's.";
CM_ SG_ 2566865538 EHR_InitDiag "A status signal indicating the EHR fault condition. Sent by both front & rear EHR's.";
CM_ SG_ 2566865538 EHR_SysId "NOT USED";
CM_ BO_ 2566865539 "During engine cranking, all diagnostics checks shall be disabled to avoid reporting of spurious error. Engine cranking is indicated by ‘init’ parameter in Ehr Control message.";
CM_ SG_ 2566865539 EHR_Err "A status signal indicating the EHR fault condition. Sent by both front & rear EHR's.";
CM_ SG_ 2566865539 EHR_ErrCod "A status value to indicate the EHR fault code. Used for front & rear EHR's.";
CM_ SG_ 2566865539 EHR_EvTemp "A measured value to indicate the EHR valve temperature. Used for front & rear EHR's.";
CM_ SG_ 2566865539 EHR_InitDiag "A status signal indicating the EHR fault condition. Sent by both front & rear EHR's.";
CM_ SG_ 2566865539 EHR_SysId "NOT USED";
CM_ BO_ 2566834816 "Active diagnostic trouble codes";
CM_ SG_ 2566834816 DTC_02 "Diagnostic Trouble Code";
CM_ SG_ 2566834816 DTC_03 "Diagnostic Trouble Code";
CM_ SG_ 2566834816 DTC_04 "Diagnostic Trouble Code";
CM_ SG_ 2566834816 AmbrWarnLmp "This lamp is used to relay trouble code information that is reporting a problem with the vehicle system but the vehicle need...";
CM_ SG_ 2566834816 DTC_01 "Diagnostic Trouble Code";
CM_ SG_ 2566834816 FlashAmbrWarnLmpAWL "This parameter provides the capability to flash the AWL (SPN 3040).";
CM_ SG_ 2566834816 FlashMIL "This parameter provides the capability to flash the MIL (SPN 3038).";
CM_ SG_ 2566834816 FlashProtLmp "This parameter provides the capability to flash the engine protect lamp (SPN 3041).";
CM_ SG_ 2566834816 FlashRedStopLmpRSL "This parameter provides the capability to flash the RSL (SPN 3039).";
CM_ SG_ 2566834816 MIL "A lamp used to relay only emissions-related trouble code information.";
CM_ SG_ 2566834816 ProtLmp "This lamp is used to relay trouble code informatio that is reporting a problem with a vehicle system that is most...";
CM_ SG_ 2566834816 RedStopLmp "This lamp is used to relay trouble code information that is of a severe enought condition that it warrants stopping the vehicle.";
CM_ BO_ 2566834817 "Active diagnostic trouble codes";
CM_ SG_ 2566834817 DTC_02 "Diagnostic Trouble Code";
CM_ SG_ 2566834817 DTC_03 "Diagnostic Trouble Code";
CM_ SG_ 2566834817 DTC_04 "Diagnostic Trouble Code";
CM_ SG_ 2566834817 AmbrWarnLmp "This lamp is used to relay trouble code information that is reporting a problem with the vehicle system but the vehicle need...";
CM_ SG_ 2566834817 DTC_01 "Diagnostic Trouble Code";
CM_ SG_ 2566834817 FlashAmbrWarnLmpAWL "This parameter provides the capability to flash the AWL (SPN 3040).";
CM_ SG_ 2566834817 FlashMIL "This parameter provides the capability to flash the MIL (SPN 3038).";
CM_ SG_ 2566834817 FlashProtLmp "This parameter provides the capability to flash the engine protect lamp (SPN 3041).";
CM_ SG_ 2566834817 FlashRedStopLmpRSL "This parameter provides the capability to flash the RSL (SPN 3039).";
CM_ SG_ 2566834817 MIL "A lamp used to relay only emissions-related trouble code information.";
CM_ SG_ 2566834817 ProtLmp "This lamp is used to relay trouble code informatio that is reporting a problem with a vehicle system that is most...";
CM_ SG_ 2566834817 RedStopLmp "This lamp is used to relay trouble code information that is of a severe enought condition that it warrants stopping the vehicle.";
CM_ BO_ 2566834818 "Active diagnostic trouble codes";
CM_ SG_ 2566834818 DTC_02 "Diagnostic Trouble Code";
CM_ SG_ 2566834818 DTC_03 "Diagnostic Trouble Code";
CM_ SG_ 2566834818 DTC_04 "Diagnostic Trouble Code";
CM_ SG_ 2566834818 RedStopLmp "This lamp is used to relay trouble code information that is of a severe enought condition that it warrants stopping the vehicle.";
CM_ SG_ 2566834818 AmbrWarnLmp "This lamp is used to relay trouble code information that is reporting a problem with the vehicle system but the vehicle need...";
CM_ SG_ 2566834818 DTC_01 "Diagnostic Trouble Code";
CM_ SG_ 2566834818 FlashAmbrWarnLmpAWL "This parameter provides the capability to flash the AWL (SPN 3040).";
CM_ SG_ 2566834818 FlashMIL "This parameter provides the capability to flash the MIL (SPN 3038).";
CM_ SG_ 2566834818 FlashProtLmp "This parameter provides the capability to flash the engine protect lamp (SPN 3041).";
CM_ SG_ 2566834818 FlashRedStopLmpRSL "This parameter provides the capability to flash the RSL (SPN 3039).";
CM_ SG_ 2566834818 MIL "A lamp used to relay only emissions-related trouble code information.";
CM_ SG_ 2566834818 ProtLmp "This lamp is used to relay trouble code informatio that is reporting a problem with a vehicle system that is most...";
CM_ BO_ 2566834819 "Active diagnostic trouble codes";
CM_ SG_ 2566834819 DTC_02 "Diagnostic Trouble Code";
CM_ SG_ 2566834819 DTC_03 "Diagnostic Trouble Code";
CM_ SG_ 2566834819 DTC_04 "Diagnostic Trouble Code";
CM_ SG_ 2566834819 AmbrWarnLmp "This lamp is used to relay trouble code information that is reporting a problem with the vehicle system but the vehicle need...";
CM_ SG_ 2566834819 DTC_01 "Diagnostic Trouble Code";
CM_ SG_ 2566834819 FlashAmbrWarnLmpAWL "This parameter provides the capability to flash the AWL (SPN 3040).";
CM_ SG_ 2566834819 FlashMIL "This parameter provides the capability to flash the MIL (SPN 3038).";
CM_ SG_ 2566834819 FlashProtLmp "This parameter provides the capability to flash the engine protect lamp (SPN 3041).";
CM_ SG_ 2566834819 FlashRedStopLmpRSL "This parameter provides the capability to flash the RSL (SPN 3039).";
CM_ SG_ 2566834819 MIL "A lamp used to relay only emissions-related trouble code information.";
CM_ SG_ 2566834819 ProtLmp "This lamp is used to relay trouble code informatio that is reporting a problem with a vehicle system that is most...";
CM_ SG_ 2566834819 RedStopLmp "This lamp is used to relay trouble code information that is of a severe enought condition that it warrants stopping the vehicle.";
CM_ BO_ 2632712064 "Transport Protocol - Data Transfer";
CM_ SG_ 2632712064 PktDataTPDT "Relevant data for this PGNs unique use.";
CM_ BO_ 2632712065 "Transport Protocol - Data Transfer";
CM_ SG_ 2632712065 PktDataTPDT "Relevant data for this PGNs unique use.";
CM_ BO_ 2632712067 "Transport Protocol - Data Transfer";
CM_ SG_ 2632712067 PktDataTPDT "Relevant data for this PGNs unique use.";
CM_ BO_ 2632712066 "Transport Protocol - Data Transfer";
CM_ SG_ 2632712066 PktDataTPDT "Relevant data for this PGNs unique use.";
CM_ BO_ 2632777600 "Transport Protocol - Connection Management";
CM_ SG_ 2632777600 ConnAbrtReason "Reason for connection abort message.";
CM_ SG_ 2632777600 MaxNumPktTPCM_RTS "Maximum number of packets for RTS/CTS message.";
CM_ SG_ 2632777600 NumPktSentTPCM_CTS "Number of Packets that can be sent (TP.CM_CTS)";
CM_ SG_ 2632777600 NxtPktNumSentTPCM_CTS "Next Packet Number to be sent (TP.CM_CTS)";
CM_ SG_ 2632777600 TotMsgSizeBAM "Total message size (in bytes) for BAM message.Total message size (in bytes) for RTS/CTS message.Total message size (in bytes) for RTS/CTS message.";
CM_ SG_ 2632777600 TotMsgSizeEoMA "Total message size (in bytes) for BAM message.Total message size (in bytes) for RTS/CTS message.Total message size (in bytes) for RTS/CTS message.";
CM_ SG_ 2632777600 TotMsgSizeTPCM_RTS "Total message size (in bytes) for BAM message.Total message size (in bytes) for RTS/CTS message.Total message size (in bytes) for RTS/CTS message.";
CM_ SG_ 2632777600 TotNumPktBAM "Total number of packets for BAM message.Total number of packets received for RTS/CTS message.Total number of packets for RTS/CTS message.";
CM_ SG_ 2632777600 TotNumPktEoMA "Total number of packets for BAM message.Total number of packets received for RTS/CTS message.Total number of packets for RTS/CTS message.";
CM_ SG_ 2632777600 TotNumPktTPCM_RTS "Total number of packets for BAM message.Total number of packets received for RTS/CTS message.Total number of packets for RTS/CTS message.";
CM_ BO_ 2632777601 "Transport Protocol - Connection Management";
CM_ SG_ 2632777601 ConnAbrtReason "Reason for connection abort message.";
CM_ SG_ 2632777601 MaxNumPktTPCM_RTS "Maximum number of packets for RTS/CTS message.";
CM_ SG_ 2632777601 NumPktSentTPCM_CTS "Number of Packets that can be sent (TP.CM_CTS)";
CM_ SG_ 2632777601 NxtPktNumSentTPCM_CTS "Next Packet Number to be sent (TP.CM_CTS)";
CM_ SG_ 2632777601 TotMsgSizeBAM "Total message size (in bytes) for BAM message.Total message size (in bytes) for RTS/CTS message.Total message size (in bytes) for RTS/CTS message.";
CM_ SG_ 2632777601 TotMsgSizeEoMA "Total message size (in bytes) for BAM message.Total message size (in bytes) for RTS/CTS message.Total message size (in bytes) for RTS/CTS message.";
CM_ SG_ 2632777601 TotMsgSizeTPCM_RTS "Total message size (in bytes) for BAM message.Total message size (in bytes) for RTS/CTS message.Total message size (in bytes) for RTS/CTS message.";
CM_ SG_ 2632777601 TotNumPktBAM "Total number of packets for BAM message.Total number of packets received for RTS/CTS message.Total number of packets for RTS/CTS message.";
CM_ SG_ 2632777601 TotNumPktEoMA "Total number of packets for BAM message.Total number of packets received for RTS/CTS message.Total number of packets for RTS/CTS message.";
CM_ SG_ 2632777601 TotNumPktTPCM_RTS "Total number of packets for BAM message.Total number of packets received for RTS/CTS message.Total number of packets for RTS/CTS message.";
CM_ BO_ 2632777602 "Transport Protocol - Connection Management";
CM_ SG_ 2632777602 ConnAbrtReason "Reason for connection abort message.";
CM_ SG_ 2632777602 MaxNumPktTPCM_RTS "Maximum number of packets for RTS/CTS message.";
CM_ SG_ 2632777602 NumPktSentTPCM_CTS "Number of Packets that can be sent (TP.CM_CTS)";
CM_ SG_ 2632777602 NxtPktNumSentTPCM_CTS "Next Packet Number to be sent (TP.CM_CTS)";
CM_ SG_ 2632777602 TotMsgSizeBAM "Total message size (in bytes) for BAM message.Total message size (in bytes) for RTS/CTS message.Total message size (in bytes) for RTS/CTS message.";
CM_ SG_ 2632777602 TotMsgSizeEoMA "Total message size (in bytes) for BAM message.Total message size (in bytes) for RTS/CTS message.Total message size (in bytes) for RTS/CTS message.";
CM_ SG_ 2632777602 TotMsgSizeTPCM_RTS "Total message size (in bytes) for BAM message.Total message size (in bytes) for RTS/CTS message.Total message size (in bytes) for RTS/CTS message.";
CM_ SG_ 2632777602 TotNumPktBAM "Total number of packets for BAM message.Total number of packets received for RTS/CTS message.Total number of packets for RTS/CTS message.";
CM_ SG_ 2632777602 TotNumPktEoMA "Total number of packets for BAM message.Total number of packets received for RTS/CTS message.Total number of packets for RTS/CTS message.";
CM_ SG_ 2632777602 TotNumPktTPCM_RTS "Total number of packets for BAM message.Total number of packets received for RTS/CTS message.Total number of packets for RTS/CTS message.";
CM_ BO_ 2632777603 "Transport Protocol - Connection Management";
CM_ SG_ 2632777603 ConnAbrtReason "Reason for connection abort message.";
CM_ SG_ 2632777603 MaxNumPktTPCM_RTS "Maximum number of packets for RTS/CTS message.";
CM_ SG_ 2632777603 NumPktSentTPCM_CTS "Number of Packets that can be sent (TP.CM_CTS)";
CM_ SG_ 2632777603 NxtPktNumSentTPCM_CTS "Next Packet Number to be sent (TP.CM_CTS)";
CM_ SG_ 2632777603 TotMsgSizeBAM "Total message size (in bytes) for BAM message.Total message size (in bytes) for RTS/CTS message.Total message size (in bytes) for RTS/CTS message.";
CM_ SG_ 2632777603 TotMsgSizeEoMA "Total message size (in bytes) for BAM message.Total message size (in bytes) for RTS/CTS message.Total message size (in bytes) for RTS/CTS message.";
CM_ SG_ 2632777603 TotMsgSizeTPCM_RTS "Total message size (in bytes) for BAM message.Total message size (in bytes) for RTS/CTS message.Total message size (in bytes) for RTS/CTS message.";
CM_ SG_ 2632777603 TotNumPktBAM "Total number of packets for BAM message.Total number of packets received for RTS/CTS message.Total number of packets for RTS/CTS message.";
CM_ SG_ 2632777603 TotNumPktEoMA "Total number of packets for BAM message.Total number of packets received for RTS/CTS message.Total number of packets for RTS/CTS message.";
CM_ SG_ 2632777603 TotNumPktTPCM_RTS "Total number of packets for BAM message.Total number of packets received for RTS/CTS message.Total number of packets for RTS/CTS message.";
CM_ BO_ 2565350016 "Acknowledgment Message";
CM_ SG_ 2565350016 GrpFunctValAck "Group Function of PGN being acknowledged. This field identifies for a device the specific group function of a PGN being acknowledged or declined.  This field is not used if the PGN being acknowledged or declined is not a group function PGN.";
CM_ SG_ 2565350016 GrpFunctValNAck "Group Function of PGN being acknowledged. This field identifies for a device the specific group function of a PGN being acknowledged or declined.  This field is not used if the PGN being acknowledged or declined is not a group function PGN.";
CM_ SG_ 2565350016 GrpFunctValNAckAd "Group Function of PGN being acknowledged. This field identifies for a device the specific group function of a PGN being acknowledged or declined.  This field is not used if the PGN being acknowledged or declined is not a group function PGN.";
CM_ SG_ 2565350016 GrpFunctValNAckBusy "Group Function of PGN being acknowledged. This field identifies for a device the specific group function of a PGN being acknowledged or declined.  This field is not used if the PGN being acknowledged or declined is not a group function PGN.";
CM_ SG_ 2565350016 PGN_Ack "PGN which is requested by Request2 message";
CM_ SG_ 2565350016 PGN_NAck "PGN which is requested by Request2 message";
CM_ SG_ 2565350016 PGN_NAckAd "PGN which is requested by Request2 message";
CM_ SG_ 2565350016 PGN_NAckBusy "PGN which is requested by Request2 message";
CM_ BO_ 2565350017 "Acknowledgment Message";
CM_ SG_ 2565350017 GrpFunctValAck "Group Function of PGN being acknowledged. This field identifies for a device the specific group function of a PGN being acknowledged or declined.  This field is not used if the PGN being acknowledged or declined is not a group function PGN.";
CM_ SG_ 2565350017 GrpFunctValNAck "Group Function of PGN being acknowledged. This field identifies for a device the specific group function of a PGN being acknowledged or declined.  This field is not used if the PGN being acknowledged or declined is not a group function PGN.";
CM_ SG_ 2565350017 GrpFunctValNAckAd "Group Function of PGN being acknowledged. This field identifies for a device the specific group function of a PGN being acknowledged or declined.  This field is not used if the PGN being acknowledged or declined is not a group function PGN.";
CM_ SG_ 2565350017 GrpFunctValNAckBusy "Group Function of PGN being acknowledged. This field identifies for a device the specific group function of a PGN being acknowledged or declined.  This field is not used if the PGN being acknowledged or declined is not a group function PGN.";
CM_ SG_ 2565350017 PGN_Ack "PGN which is requested by Request2 message";
CM_ SG_ 2565350017 PGN_NAck "PGN which is requested by Request2 message";
CM_ SG_ 2565350017 PGN_NAckAd "PGN which is requested by Request2 message";
CM_ SG_ 2565350017 PGN_NAckBusy "PGN which is requested by Request2 message";
CM_ BO_ 2565350018 "Acknowledgment Message";
CM_ SG_ 2565350018 GrpFunctValAck "Group Function of PGN being acknowledged. This field identifies for a device the specific group function of a PGN being acknowledged or declined.  This field is not used if the PGN being acknowledged or declined is not a group function PGN.";
CM_ SG_ 2565350018 GrpFunctValNAck "Group Function of PGN being acknowledged. This field identifies for a device the specific group function of a PGN being acknowledged or declined.  This field is not used if the PGN being acknowledged or declined is not a group function PGN.";
CM_ SG_ 2565350018 GrpFunctValNAckAd "Group Function of PGN being acknowledged. This field identifies for a device the specific group function of a PGN being acknowledged or declined.  This field is not used if the PGN being acknowledged or declined is not a group function PGN.";
CM_ SG_ 2565350018 GrpFunctValNAckBusy "Group Function of PGN being acknowledged. This field identifies for a device the specific group function of a PGN being acknowledged or declined.  This field is not used if the PGN being acknowledged or declined is not a group function PGN.";
CM_ SG_ 2565350018 PGN_Ack "PGN which is requested by Request2 message";
CM_ SG_ 2565350018 PGN_NAck "PGN which is requested by Request2 message";
CM_ SG_ 2565350018 PGN_NAckAd "PGN which is requested by Request2 message";
CM_ SG_ 2565350018 PGN_NAckBusy "PGN which is requested by Request2 message";
CM_ BO_ 2565350019 "Acknowledgment Message";
CM_ SG_ 2565350019 GrpFunctValAck "Group Function of PGN being acknowledged. This field identifies for a device the specific group function of a PGN being acknowledged or declined.  This field is not used if the PGN being acknowledged or declined is not a group function PGN.";
CM_ SG_ 2565350019 GrpFunctValNAck "Group Function of PGN being acknowledged. This field identifies for a device the specific group function of a PGN being acknowledged or declined.  This field is not used if the PGN being acknowledged or declined is not a group function PGN.";
CM_ SG_ 2565350019 GrpFunctValNAckAd "Group Function of PGN being acknowledged. This field identifies for a device the specific group function of a PGN being acknowledged or declined.  This field is not used if the PGN being acknowledged or declined is not a group function PGN.";
CM_ SG_ 2565350019 GrpFunctValNAckBusy "Group Function of PGN being acknowledged. This field identifies for a device the specific group function of a PGN being acknowledged or declined.  This field is not used if the PGN being acknowledged or declined is not a group function PGN.";
CM_ SG_ 2565350019 PGN_Ack "PGN which is requested by Request2 message";
CM_ SG_ 2565350019 PGN_NAck "PGN which is requested by Request2 message";
CM_ SG_ 2565350019 PGN_NAckAd "PGN which is requested by Request2 message";
CM_ SG_ 2565350019 PGN_NAckBusy "PGN which is requested by Request2 message";
BA_DEF_ SG_  "GenSigReceiveSetting" STRING ;
BA_DEF_ SG_  "GenSigPreSetting" STRING ;
BA_DEF_ SG_  "GenSigPreIfSetting" STRING ;
BA_DEF_ SG_  "GenSigPostSetting" STRING ;
BA_DEF_ SG_  "GenSigPostIfSetting" STRING ;
BA_DEF_ SG_  "GenSigEnvVarType" ENUM  "int","float","undef";
BA_DEF_ SG_  "GenSigConditionalSend" STRING ;
BA_DEF_ SG_  "GenSigAutoGenSnd" ENUM  "No","Yes";
BA_DEF_ SG_  "GenSigAutoGenDsp" ENUM  "No","Yes";
BA_DEF_ SG_  "GenSigAssignSetting" STRING ;
BA_DEF_ SG_  "GenSigAltSetting" STRING ;
BA_DEF_ SG_  "SPN_Definition" STRING ;
BA_DEF_ SG_  "External_Reference_decod" STRING ;
BA_DEF_ SG_  "UtilizationOnNetwork" ENUM  "Used","NOT USED";
BA_DEF_ SG_  "CI_RepetitionNum" ENUM  "1","2";
BA_DEF_ SG_  "CI_RepetitionType" ENUM  "NA","1","2","3","4";
BA_DEF_ SG_  "CI_RepetitionComplemented" ENUM  "0","1","vector_leerstring";
BA_DEF_ SG_  "DDI" INT 0 65535;
BA_DEF_ SG_  "CI_FullName" STRING ;
BA_DEF_ SG_  "GenSigTimeoutTime" INT 0 3600000;
BA_DEF_ SG_  "CI_ParId" STRING ;
BA_DEF_ SG_  "CI_SLOT_Name" STRING ;
BA_DEF_ SG_  "CI_ParVersion" STRING ;
BA_DEF_ SG_  "GenSigSendType" ENUM  "Cyclic","OnWrite","OnWriteWithRepetition","OnChange","OnChangeWithRepetition","IfActive","IfActiveWithRepetition","NoSigSendType";
BA_DEF_ SG_  "GenSigInactiveValue" INT 0 2147483647;
BA_DEF_ SG_  "GenSigStartValue" INT 0 2147483647;
BA_DEF_ SG_  "GenSigEVName" STRING ;
BA_DEF_ SG_  "SPN" INT 0 524287;
BA_DEF_ SG_  "SigType" ENUM  "Default","Range","RangeSigned","ASCII","Discrete","Control","ReferencePGN","DTC","StringDelimiter","StringLength","StringLengthControl";
BA_DEF_ SG_  "GenSigILSupport" ENUM  "Yes","No";
BA_DEF_ BO_  "ShowSignals" INT -1 0;
BA_DEF_ BO_  "GroupSignals" INT 1 100;
BA_DEF_ BO_  "PGN_Definition" STRING ;
BA_DEF_ BO_  "External_Reference" STRING ;
BA_DEF_ BO_  "SingleFrame" INT 0 1;
BA_DEF_ BO_  "CI_AllowedLostMessages" ENUM  "NA","0","1","2","3","4";
BA_DEF_ BO_  "CI_AliveTimeout" INT 0 3600000;
BA_DEF_ BO_  "TpJ1939VarDlc" ENUM  "No","Yes";
BA_DEF_ BO_  "CI_ShowSignals" INT -1 0;
BA_DEF_ BO_  "CI_PgVersion" STRING ;
BA_DEF_ BO_  "CI_GroupSignals" INT 1 100;
BA_DEF_ BO_  "DiagUUDTResponse" ENUM  "No","Yes";
BA_DEF_ BO_  "DiagState" ENUM  "No","Yes";
BA_DEF_ BO_  "DiagResponse" ENUM  "No","Yes";
BA_DEF_ BO_  "DiagRequest" ENUM  "No","Yes";
BA_DEF_ BO_  "DiagConnection" INT 0 65535;
BA_DEF_ BO_  "GenMsgNrOfRepetition" INT 0 1000000;
BA_DEF_ BO_  "GenMsgILSupport" ENUM  "No","Yes";
BA_DEF_ BO_  "GenMsgFastOnStart" INT 0 100000;
BA_DEF_ BO_  "GenMsgCycleTimeFast" INT 0 3600000;
BA_DEF_ BO_  "GenMsgStartDelayTime" INT 0 100000;
BA_DEF_ BO_  "GenMsgDelayTime" INT 0 3600000;
BA_DEF_ BO_  "VFrameFormat" ENUM  "StandardCAN","ExtendedCAN","reserved","J1939PG";
BA_DEF_ BO_  "GenMsgCycleTime" INT 0 3600000;
BA_DEF_ BO_  "GenMsgRequestable" INT 0 1;
BA_DEF_ BO_  "GenMsgSendType" ENUM  "cyclic","reserved","cyclicIfActive","reserved","reserved","reserved","reserved","reserved","noMsgSendType";
BA_DEF_DEF_  "GenSigReceiveSetting" "";
BA_DEF_DEF_  "GenSigPreSetting" "";
BA_DEF_DEF_  "GenSigPreIfSetting" "";
BA_DEF_DEF_  "GenSigPostSetting" "";
BA_DEF_DEF_  "GenSigPostIfSetting" "";
BA_DEF_DEF_  "GenSigEnvVarType" "undef";
BA_DEF_DEF_  "GenSigConditionalSend" "";
BA_DEF_DEF_  "GenSigAutoGenSnd" "";
BA_DEF_DEF_  "GenSigAutoGenDsp" "";
BA_DEF_DEF_  "GenSigAssignSetting" "";
BA_DEF_DEF_  "GenSigAltSetting" "";
BA_DEF_DEF_  "SPN_Definition" "";
BA_DEF_DEF_  "External_Reference_decod" "";
BA_DEF_DEF_  "UtilizationOnNetwork" "Used";
BA_DEF_DEF_  "CI_RepetitionNum" "1";
BA_DEF_DEF_  "CI_RepetitionType" "NA";
BA_DEF_DEF_  "CI_RepetitionComplemented" "0";
BA_DEF_DEF_  "DDI" 0;
BA_DEF_DEF_  "CI_FullName" "";
BA_DEF_DEF_  "GenSigTimeoutTime" 0;
BA_DEF_DEF_  "CI_ParId" "";
BA_DEF_DEF_  "CI_SLOT_Name" "0";
BA_DEF_DEF_  "CI_ParVersion" "0";
BA_DEF_DEF_  "GenSigSendType" "NoSigSendType";
BA_DEF_DEF_  "GenSigInactiveValue" 0;
BA_DEF_DEF_  "GenSigStartValue" 0;
BA_DEF_DEF_  "GenSigEVName" "Env@Nodename_@Signame";
BA_DEF_DEF_  "SPN" 0;
BA_DEF_DEF_  "SigType" "Default";
BA_DEF_DEF_  "GenSigILSupport" "Yes";
BA_DEF_DEF_  "ShowSignals" -1;
BA_DEF_DEF_  "GroupSignals" 1;
BA_DEF_DEF_  "PGN_Definition" "N/A";
BA_DEF_DEF_  "External_Reference" "";
BA_DEF_DEF_  "SingleFrame" 1;
BA_DEF_DEF_  "CI_AllowedLostMessages" "NA";
BA_DEF_DEF_  "CI_AliveTimeout" 0;
BA_DEF_DEF_  "TpJ1939VarDlc" "No";
BA_DEF_DEF_  "CI_ShowSignals" -1;
BA_DEF_DEF_  "CI_PgVersion" "0";
BA_DEF_DEF_  "CI_GroupSignals" 1;
BA_DEF_DEF_  "DiagUUDTResponse" "No";
BA_DEF_DEF_  "DiagState" "No";
BA_DEF_DEF_  "DiagResponse" "No";
BA_DEF_DEF_  "DiagRequest" "No";
BA_DEF_DEF_  "DiagConnection" 0;
BA_DEF_DEF_  "GenMsgNrOfRepetition" 0;
BA_DEF_DEF_  "GenMsgILSupport" "Yes";
BA_DEF_DEF_  "GenMsgFastOnStart" 0;
BA_DEF_DEF_  "GenMsgCycleTimeFast" 0;
BA_DEF_DEF_  "GenMsgStartDelayTime" 0;
BA_DEF_DEF_  "GenMsgDelayTime" 1;
BA_DEF_DEF_  "VFrameFormat" "J1939PG";
BA_DEF_DEF_  "GenMsgCycleTime" 0;
BA_DEF_DEF_  "GenMsgRequestable" 0;
BA_DEF_DEF_  "GenMsgSendType" "noMsgSendType";
BA_ "CI_ShowSignals" BO_ 2566866052 0;
BA_ "CI_ShowSignals" BO_ 2566866057 0;
BA_ "PGN_Definition" BO_ 2565799817 "J1939 Standard";
BA_ "CI_ShowSignals" BO_ 2565799817 0;
BA_ "GenMsgDelayTime" BO_ 2565799817 0;
BA_ "GenMsgRequestable" BO_ 2565799817 1;
BA_ "PGN_Definition" BO_ 2565799812 "J1939 Standard";
BA_ "CI_ShowSignals" BO_ 2565799812 0;
BA_ "GenMsgDelayTime" BO_ 2565799812 0;
BA_ "GenMsgRequestable" BO_ 2565799812 1;
BA_ "PGN_Definition" BO_ 2565799811 "J1939 Standard";
BA_ "CI_ShowSignals" BO_ 2565799811 0;
BA_ "GenMsgDelayTime" BO_ 2565799811 0;
BA_ "GenMsgRequestable" BO_ 2565799811 1;
BA_ "CI_AllowedLostMessages" BO_ 2566854786 2;
BA_ "CI_AliveTimeout" BO_ 2566854786 400;
BA_ "CI_ShowSignals" BO_ 2566854786 0;
BA_ "GenMsgCycleTime" BO_ 2566854786 100;
BA_ "GenMsgSendType" BO_ 2566854786 0;
BA_ "CI_AllowedLostMessages" BO_ 2566854787 2;
BA_ "CI_AliveTimeout" BO_ 2566854787 400;
BA_ "CI_ShowSignals" BO_ 2566854787 0;
BA_ "GenMsgCycleTime" BO_ 2566854787 100;
BA_ "GenMsgSendType" BO_ 2566854787 0;
BA_ "CI_AllowedLostMessages" BO_ 2566865536 2;
BA_ "CI_AliveTimeout" BO_ 2566865536 400;
BA_ "GenMsgCycleTime" BO_ 2566865536 100;
BA_ "GenMsgSendType" BO_ 2566865536 0;
BA_ "CI_AllowedLostMessages" BO_ 2566865537 2;
BA_ "CI_AliveTimeout" BO_ 2566865537 400;
BA_ "CI_ShowSignals" BO_ 2566865537 0;
BA_ "GenMsgCycleTime" BO_ 2566865537 100;
BA_ "GenMsgSendType" BO_ 2566865537 0;
BA_ "CI_AllowedLostMessages" BO_ 2566865538 2;
BA_ "CI_AliveTimeout" BO_ 2566865538 400;
BA_ "CI_ShowSignals" BO_ 2566865538 0;
BA_ "GenMsgCycleTime" BO_ 2566865538 100;
BA_ "GenMsgSendType" BO_ 2566865538 0;
BA_ "CI_AllowedLostMessages" BO_ 2566865539 2;
BA_ "CI_AliveTimeout" BO_ 2566865539 400;
BA_ "CI_ShowSignals" BO_ 2566865539 0;
BA_ "GenMsgCycleTime" BO_ 2566865539 100;
BA_ "GenMsgSendType" BO_ 2566865539 0;
BA_ "TpJ1939VarDlc" BO_ 2566834816 1;
BA_ "GenMsgCycleTime" BO_ 2566834816 1000;
BA_ "GenMsgSendType" BO_ 2566834816 0;
BA_ "TpJ1939VarDlc" BO_ 2566834817 1;
BA_ "CI_ShowSignals" BO_ 2566834817 0;
BA_ "GenMsgCycleTime" BO_ 2566834817 1000;
BA_ "GenMsgSendType" BO_ 2566834817 0;
BA_ "TpJ1939VarDlc" BO_ 2566834818 1;
BA_ "CI_ShowSignals" BO_ 2566834818 0;
BA_ "GenMsgCycleTime" BO_ 2566834818 1000;
BA_ "GenMsgSendType" BO_ 2566834818 0;
BA_ "TpJ1939VarDlc" BO_ 2566834819 1;
BA_ "CI_ShowSignals" BO_ 2566834819 0;
BA_ "GenMsgCycleTime" BO_ 2566834819 1000;
BA_ "GenMsgSendType" BO_ 2566834819 0;
BA_ "PGN_Definition" BO_ 2632712064 "J1939 Standard";
BA_ "TpJ1939VarDlc" BO_ 2632712064 1;
BA_ "GenMsgDelayTime" BO_ 2632712064 0;
BA_ "PGN_Definition" BO_ 2632712065 "J1939 Standard";
BA_ "TpJ1939VarDlc" BO_ 2632712065 1;
BA_ "CI_ShowSignals" BO_ 2632712065 0;
BA_ "GenMsgDelayTime" BO_ 2632712065 0;
BA_ "PGN_Definition" BO_ 2632712067 "J1939 Standard";
BA_ "TpJ1939VarDlc" BO_ 2632712067 1;
BA_ "CI_ShowSignals" BO_ 2632712067 0;
BA_ "GenMsgDelayTime" BO_ 2632712067 0;
BA_ "PGN_Definition" BO_ 2632712066 "J1939 Standard";
BA_ "TpJ1939VarDlc" BO_ 2632712066 1;
BA_ "CI_ShowSignals" BO_ 2632712066 0;
BA_ "GenMsgDelayTime" BO_ 2632712066 0;
BA_ "PGN_Definition" BO_ 2632777600 "J1939 Standard";
BA_ "External_Reference" BO_ 2632777600 "J1939 Standard";
BA_ "TpJ1939VarDlc" BO_ 2632777600 1;
BA_ "GenMsgDelayTime" BO_ 2632777600 0;
BA_ "PGN_Definition" BO_ 2632777601 "J1939 Standard";
BA_ "External_Reference" BO_ 2632777601 "J1939 Standard";
BA_ "TpJ1939VarDlc" BO_ 2632777601 1;
BA_ "CI_ShowSignals" BO_ 2632777601 0;
BA_ "GenMsgDelayTime" BO_ 2632777601 0;
BA_ "PGN_Definition" BO_ 2632777602 "J1939 Standard";
BA_ "External_Reference" BO_ 2632777602 "J1939 Standard";
BA_ "TpJ1939VarDlc" BO_ 2632777602 1;
BA_ "CI_ShowSignals" BO_ 2632777602 0;
BA_ "GenMsgDelayTime" BO_ 2632777602 0;
BA_ "PGN_Definition" BO_ 2632777603 "J1939 Standard";
BA_ "External_Reference" BO_ 2632777603 "J1939 Standard";
BA_ "TpJ1939VarDlc" BO_ 2632777603 1;
BA_ "CI_ShowSignals" BO_ 2632777603 0;
BA_ "GenMsgDelayTime" BO_ 2632777603 0;
BA_ "TpJ1939VarDlc" BO_ 2565350016 1;
BA_ "CI_ShowSignals" BO_ 2565350016 0;
BA_ "CI_GroupSignals" BO_ 2565350016 3;
BA_ "GenMsgDelayTime" BO_ 2565350016 0;
BA_ "TpJ1939VarDlc" BO_ 2565350017 1;
BA_ "CI_ShowSignals" BO_ 2565350017 0;
BA_ "CI_GroupSignals" BO_ 2565350017 10;
BA_ "GenMsgDelayTime" BO_ 2565350017 0;
BA_ "TpJ1939VarDlc" BO_ 2565350018 1;
BA_ "CI_ShowSignals" BO_ 2565350018 0;
BA_ "CI_GroupSignals" BO_ 2565350018 9;
BA_ "GenMsgDelayTime" BO_ 2565350018 0;
BA_ "TpJ1939VarDlc" BO_ 2565350019 1;
BA_ "CI_ShowSignals" BO_ 2565350019 0;
BA_ "CI_GroupSignals" BO_ 2565350019 8;
BA_ "GenMsgDelayTime" BO_ 2565350019 0;
BA_ "CI_FullName" SG_ 2566866052 EHR_ChksumStor "EHR Checksum Storage";
BA_ "CI_ParId" SG_ 2566866052 EHR_ChksumStor "ESMD_20887";
BA_ "CI_FullName" SG_ 2566866052 EHR_ChksumSW "EHR Checksum Software";
BA_ "CI_ParId" SG_ 2566866052 EHR_ChksumSW "ESMD_20886";
BA_ "CI_FullName" SG_ 2566866052 EHR_EvNumParamMux_12 "EHR Valve Number Parameter Multiplex 12";
BA_ "CI_ParId" SG_ 2566866052 EHR_EvNumParamMux_12 "ESMD_20916";
BA_ "CI_FullName" SG_ 2566866052 EHR_ParamByte_1 "EHR Parameter Byte 1";
BA_ "CI_ParId" SG_ 2566866052 EHR_ParamByte_1 "ESMD_20901";
BA_ "CI_FullName" SG_ 2566866052 EHR_ParamStsByte_2 "EHR Parameter Status Byte 2";
BA_ "CI_ParId" SG_ 2566866052 EHR_ParamStsByte_2 "ESMD_20903";
BA_ "CI_FullName" SG_ 2566866052 EHR_ParamStsByte_3 "EHR Parameter Status Byte 3";
BA_ "CI_ParId" SG_ 2566866052 EHR_ParamStsByte_3 "ESMD_20904";
BA_ "CI_FullName" SG_ 2566866052 EHR_RmpRndng "EHR Ramp Rounding";
BA_ "CI_ParId" SG_ 2566866052 EHR_RmpRndng "ESMD_20908";
BA_ "CI_FullName" SG_ 2566866057 EHR_ChksumStor "EHR Checksum Storage";
BA_ "CI_ParId" SG_ 2566866057 EHR_ChksumStor "ESMD_20887";
BA_ "CI_FullName" SG_ 2566866057 EHR_ChksumSW "EHR Checksum Software";
BA_ "CI_ParId" SG_ 2566866057 EHR_ChksumSW "ESMD_20886";
BA_ "CI_FullName" SG_ 2566866057 EHR_EvNumParamMux_12 "EHR Valve Number Parameter Multiplex 12";
BA_ "CI_ParId" SG_ 2566866057 EHR_EvNumParamMux_12 "ESMD_20916";
BA_ "CI_FullName" SG_ 2566866057 EHR_ParamByte_1 "EHR Parameter Byte 1";
BA_ "CI_ParId" SG_ 2566866057 EHR_ParamByte_1 "ESMD_20901";
BA_ "CI_FullName" SG_ 2566866057 EHR_ParamStsByte_2 "EHR Parameter Status Byte 2";
BA_ "CI_ParId" SG_ 2566866057 EHR_ParamStsByte_2 "ESMD_20903";
BA_ "CI_FullName" SG_ 2566866057 EHR_ParamStsByte_3 "EHR Parameter Status Byte 3";
BA_ "CI_ParId" SG_ 2566866057 EHR_ParamStsByte_3 "ESMD_20904";
BA_ "CI_FullName" SG_ 2566866057 EHR_RmpRndng "EHR Ramp Rounding";
BA_ "CI_ParId" SG_ 2566866057 EHR_RmpRndng "ESMD_20908";
BA_ "CI_FullName" SG_ 2565799817 Rsrvd_1Bit "Reserved 1 Bit";
BA_ "CI_ParId" SG_ 2565799817 Rsrvd_1Bit "ESMD_23062";
BA_ "GenSigAutoGenSnd" SG_ 2565799817 IdNum 0;
BA_ "GenSigAutoGenDsp" SG_ 2565799817 IdNum 0;
BA_ "CI_RepetitionComplemented" SG_ 2565799817 IdNum 2;
BA_ "CI_FullName" SG_ 2565799817 IdNum "Identity Number";
BA_ "CI_ParId" SG_ 2565799817 IdNum "ESMD_08726";
BA_ "SPN" SG_ 2565799817 IdNum 2837;
BA_ "GenSigAutoGenSnd" SG_ 2565799817 ManufctCod 0;
BA_ "GenSigAutoGenDsp" SG_ 2565799817 ManufctCod 0;
BA_ "CI_RepetitionComplemented" SG_ 2565799817 ManufctCod 2;
BA_ "CI_FullName" SG_ 2565799817 ManufctCod "Manufacturer Code";
BA_ "CI_ParId" SG_ 2565799817 ManufctCod "ESMD_08852";
BA_ "SPN" SG_ 2565799817 ManufctCod 2838;
BA_ "SigType" SG_ 2565799817 ManufctCod 1;
BA_ "GenSigAutoGenSnd" SG_ 2565799817 ECU_Inst 0;
BA_ "GenSigAutoGenDsp" SG_ 2565799817 ECU_Inst 0;
BA_ "CI_RepetitionComplemented" SG_ 2565799817 ECU_Inst 2;
BA_ "CI_FullName" SG_ 2565799817 ECU_Inst "ECU Instance";
BA_ "CI_ParId" SG_ 2565799817 ECU_Inst "ESMD_08387";
BA_ "SPN" SG_ 2565799817 ECU_Inst 2840;
BA_ "GenSigAutoGenSnd" SG_ 2565799817 FunctInst 0;
BA_ "GenSigAutoGenDsp" SG_ 2565799817 FunctInst 0;
BA_ "CI_RepetitionComplemented" SG_ 2565799817 FunctInst 2;
BA_ "CI_FullName" SG_ 2565799817 FunctInst "Function Instance";
BA_ "CI_ParId" SG_ 2565799817 FunctInst "ESMD_08670";
BA_ "SPN" SG_ 2565799817 FunctInst 2839;
BA_ "GenSigAutoGenSnd" SG_ 2565799817 Funct 0;
BA_ "GenSigAutoGenDsp" SG_ 2565799817 Funct 0;
BA_ "CI_RepetitionComplemented" SG_ 2565799817 Funct 2;
BA_ "CI_FullName" SG_ 2565799817 Funct "Function";
BA_ "CI_ParId" SG_ 2565799817 Funct "ESMD_08663";
BA_ "SPN" SG_ 2565799817 Funct 2841;
BA_ "GenSigAutoGenSnd" SG_ 2565799817 IndstryGrp 0;
BA_ "GenSigAutoGenDsp" SG_ 2565799817 IndstryGrp 0;
BA_ "CI_RepetitionComplemented" SG_ 2565799817 IndstryGrp 2;
BA_ "CI_FullName" SG_ 2565799817 IndstryGrp "Industry Group";
BA_ "CI_ParId" SG_ 2565799817 IndstryGrp "ESMD_02136";
BA_ "SPN" SG_ 2565799817 IndstryGrp 2846;
BA_ "GenSigAutoGenSnd" SG_ 2565799817 VehSys 0;
BA_ "GenSigAutoGenDsp" SG_ 2565799817 VehSys 0;
BA_ "CI_RepetitionComplemented" SG_ 2565799817 VehSys 2;
BA_ "CI_FullName" SG_ 2565799817 VehSys "Vehicle system";
BA_ "CI_ParId" SG_ 2565799817 VehSys "ESMD_16375";
BA_ "SPN" SG_ 2565799817 VehSys 2842;
BA_ "GenSigAutoGenSnd" SG_ 2565799817 VehSysInst 0;
BA_ "GenSigAutoGenDsp" SG_ 2565799817 VehSysInst 0;
BA_ "CI_RepetitionComplemented" SG_ 2565799817 VehSysInst 2;
BA_ "CI_FullName" SG_ 2565799817 VehSysInst "Vehicle System Instance";
BA_ "CI_ParId" SG_ 2565799817 VehSysInst "ESMD_09571";
BA_ "SPN" SG_ 2565799817 VehSysInst 2843;
BA_ "GenSigAutoGenSnd" SG_ 2565799817 ArbAddrCap 0;
BA_ "GenSigAutoGenDsp" SG_ 2565799817 ArbAddrCap 0;
BA_ "CI_RepetitionComplemented" SG_ 2565799817 ArbAddrCap 2;
BA_ "CI_FullName" SG_ 2565799817 ArbAddrCap "Arbitrary Address Capable";
BA_ "CI_ParId" SG_ 2565799817 ArbAddrCap "ESMD_08115";
BA_ "SPN" SG_ 2565799817 ArbAddrCap 2844;
BA_ "GenSigAutoGenSnd" SG_ 2565799812 ECU_Inst 0;
BA_ "GenSigAutoGenDsp" SG_ 2565799812 ECU_Inst 0;
BA_ "CI_RepetitionComplemented" SG_ 2565799812 ECU_Inst 2;
BA_ "CI_FullName" SG_ 2565799812 ECU_Inst "ECU Instance";
BA_ "CI_ParId" SG_ 2565799812 ECU_Inst "ESMD_08387";
BA_ "SPN" SG_ 2565799812 ECU_Inst 2840;
BA_ "GenSigAutoGenSnd" SG_ 2565799812 FunctInst 0;
BA_ "GenSigAutoGenDsp" SG_ 2565799812 FunctInst 0;
BA_ "CI_RepetitionComplemented" SG_ 2565799812 FunctInst 2;
BA_ "CI_FullName" SG_ 2565799812 FunctInst "Function Instance";
BA_ "CI_ParId" SG_ 2565799812 FunctInst "ESMD_08670";
BA_ "SPN" SG_ 2565799812 FunctInst 2839;
BA_ "GenSigAutoGenSnd" SG_ 2565799812 Funct 0;
BA_ "GenSigAutoGenDsp" SG_ 2565799812 Funct 0;
BA_ "CI_RepetitionComplemented" SG_ 2565799812 Funct 2;
BA_ "CI_FullName" SG_ 2565799812 Funct "Function";
BA_ "CI_ParId" SG_ 2565799812 Funct "ESMD_08663";
BA_ "SPN" SG_ 2565799812 Funct 2841;
BA_ "CI_FullName" SG_ 2565799812 Rsrvd_1Bit "Reserved 1 Bit";
BA_ "CI_ParId" SG_ 2565799812 Rsrvd_1Bit "ESMD_23062";
BA_ "GenSigAutoGenSnd" SG_ 2565799812 IdNum 0;
BA_ "GenSigAutoGenDsp" SG_ 2565799812 IdNum 0;
BA_ "CI_RepetitionComplemented" SG_ 2565799812 IdNum 2;
BA_ "CI_FullName" SG_ 2565799812 IdNum "Identity Number";
BA_ "CI_ParId" SG_ 2565799812 IdNum "ESMD_08726";
BA_ "SPN" SG_ 2565799812 IdNum 2837;
BA_ "GenSigAutoGenSnd" SG_ 2565799812 ManufctCod 0;
BA_ "GenSigAutoGenDsp" SG_ 2565799812 ManufctCod 0;
BA_ "CI_RepetitionComplemented" SG_ 2565799812 ManufctCod 2;
BA_ "CI_FullName" SG_ 2565799812 ManufctCod "Manufacturer Code";
BA_ "CI_ParId" SG_ 2565799812 ManufctCod "ESMD_08852";
BA_ "SPN" SG_ 2565799812 ManufctCod 2838;
BA_ "SigType" SG_ 2565799812 ManufctCod 1;
BA_ "GenSigAutoGenSnd" SG_ 2565799812 IndstryGrp 0;
BA_ "GenSigAutoGenDsp" SG_ 2565799812 IndstryGrp 0;
BA_ "CI_RepetitionComplemented" SG_ 2565799812 IndstryGrp 2;
BA_ "CI_FullName" SG_ 2565799812 IndstryGrp "Industry Group";
BA_ "CI_ParId" SG_ 2565799812 IndstryGrp "ESMD_02136";
BA_ "SPN" SG_ 2565799812 IndstryGrp 2846;
BA_ "GenSigAutoGenSnd" SG_ 2565799812 VehSys 0;
BA_ "GenSigAutoGenDsp" SG_ 2565799812 VehSys 0;
BA_ "CI_RepetitionComplemented" SG_ 2565799812 VehSys 2;
BA_ "CI_FullName" SG_ 2565799812 VehSys "Vehicle system";
BA_ "CI_ParId" SG_ 2565799812 VehSys "ESMD_16375";
BA_ "SPN" SG_ 2565799812 VehSys 2842;
BA_ "GenSigAutoGenSnd" SG_ 2565799812 VehSysInst 0;
BA_ "GenSigAutoGenDsp" SG_ 2565799812 VehSysInst 0;
BA_ "CI_RepetitionComplemented" SG_ 2565799812 VehSysInst 2;
BA_ "CI_FullName" SG_ 2565799812 VehSysInst "Vehicle System Instance";
BA_ "CI_ParId" SG_ 2565799812 VehSysInst "ESMD_09571";
BA_ "SPN" SG_ 2565799812 VehSysInst 2843;
BA_ "GenSigAutoGenSnd" SG_ 2565799812 ArbAddrCap 0;
BA_ "GenSigAutoGenDsp" SG_ 2565799812 ArbAddrCap 0;
BA_ "CI_RepetitionComplemented" SG_ 2565799812 ArbAddrCap 2;
BA_ "CI_FullName" SG_ 2565799812 ArbAddrCap "Arbitrary Address Capable";
BA_ "CI_ParId" SG_ 2565799812 ArbAddrCap "ESMD_08115";
BA_ "SPN" SG_ 2565799812 ArbAddrCap 2844;
BA_ "CI_FullName" SG_ 2565799811 Rsrvd_1Bit "Reserved 1 Bit";
BA_ "CI_ParId" SG_ 2565799811 Rsrvd_1Bit "ESMD_23062";
BA_ "GenSigAutoGenSnd" SG_ 2565799811 IdNum 0;
BA_ "GenSigAutoGenDsp" SG_ 2565799811 IdNum 0;
BA_ "CI_RepetitionComplemented" SG_ 2565799811 IdNum 2;
BA_ "CI_FullName" SG_ 2565799811 IdNum "Identity Number";
BA_ "CI_ParId" SG_ 2565799811 IdNum "ESMD_08726";
BA_ "SPN" SG_ 2565799811 IdNum 2837;
BA_ "GenSigAutoGenSnd" SG_ 2565799811 ManufctCod 0;
BA_ "GenSigAutoGenDsp" SG_ 2565799811 ManufctCod 0;
BA_ "CI_RepetitionComplemented" SG_ 2565799811 ManufctCod 2;
BA_ "CI_FullName" SG_ 2565799811 ManufctCod "Manufacturer Code";
BA_ "CI_ParId" SG_ 2565799811 ManufctCod "ESMD_08852";
BA_ "SPN" SG_ 2565799811 ManufctCod 2838;
BA_ "SigType" SG_ 2565799811 ManufctCod 1;
BA_ "GenSigAutoGenSnd" SG_ 2565799811 ECU_Inst 0;
BA_ "GenSigAutoGenDsp" SG_ 2565799811 ECU_Inst 0;
BA_ "CI_RepetitionComplemented" SG_ 2565799811 ECU_Inst 2;
BA_ "CI_FullName" SG_ 2565799811 ECU_Inst "ECU Instance";
BA_ "CI_ParId" SG_ 2565799811 ECU_Inst "ESMD_08387";
BA_ "SPN" SG_ 2565799811 ECU_Inst 2840;
BA_ "GenSigAutoGenSnd" SG_ 2565799811 FunctInst 0;
BA_ "GenSigAutoGenDsp" SG_ 2565799811 FunctInst 0;
BA_ "CI_RepetitionComplemented" SG_ 2565799811 FunctInst 2;
BA_ "CI_FullName" SG_ 2565799811 FunctInst "Function Instance";
BA_ "CI_ParId" SG_ 2565799811 FunctInst "ESMD_08670";
BA_ "SPN" SG_ 2565799811 FunctInst 2839;
BA_ "GenSigAutoGenSnd" SG_ 2565799811 Funct 0;
BA_ "GenSigAutoGenDsp" SG_ 2565799811 Funct 0;
BA_ "CI_RepetitionComplemented" SG_ 2565799811 Funct 2;
BA_ "CI_FullName" SG_ 2565799811 Funct "Function";
BA_ "CI_ParId" SG_ 2565799811 Funct "ESMD_08663";
BA_ "SPN" SG_ 2565799811 Funct 2841;
BA_ "GenSigAutoGenSnd" SG_ 2565799811 IndstryGrp 0;
BA_ "GenSigAutoGenDsp" SG_ 2565799811 IndstryGrp 0;
BA_ "CI_RepetitionComplemented" SG_ 2565799811 IndstryGrp 2;
BA_ "CI_FullName" SG_ 2565799811 IndstryGrp "Industry Group";
BA_ "CI_ParId" SG_ 2565799811 IndstryGrp "ESMD_02136";
BA_ "SPN" SG_ 2565799811 IndstryGrp 2846;
BA_ "GenSigAutoGenSnd" SG_ 2565799811 VehSys 0;
BA_ "GenSigAutoGenDsp" SG_ 2565799811 VehSys 0;
BA_ "CI_RepetitionComplemented" SG_ 2565799811 VehSys 2;
BA_ "CI_FullName" SG_ 2565799811 VehSys "Vehicle system";
BA_ "CI_ParId" SG_ 2565799811 VehSys "ESMD_16375";
BA_ "SPN" SG_ 2565799811 VehSys 2842;
BA_ "GenSigAutoGenSnd" SG_ 2565799811 VehSysInst 0;
BA_ "GenSigAutoGenDsp" SG_ 2565799811 VehSysInst 0;
BA_ "CI_RepetitionComplemented" SG_ 2565799811 VehSysInst 2;
BA_ "CI_FullName" SG_ 2565799811 VehSysInst "Vehicle System Instance";
BA_ "CI_ParId" SG_ 2565799811 VehSysInst "ESMD_09571";
BA_ "SPN" SG_ 2565799811 VehSysInst 2843;
BA_ "GenSigAutoGenSnd" SG_ 2565799811 ArbAddrCap 0;
BA_ "GenSigAutoGenDsp" SG_ 2565799811 ArbAddrCap 0;
BA_ "CI_RepetitionComplemented" SG_ 2565799811 ArbAddrCap 2;
BA_ "CI_FullName" SG_ 2565799811 ArbAddrCap "Arbitrary Address Capable";
BA_ "CI_ParId" SG_ 2565799811 ArbAddrCap "ESMD_08115";
BA_ "SPN" SG_ 2565799811 ArbAddrCap 2844;
BA_ "CI_FullName" SG_ 2566854786 EHR_EvNum_4Bit "EHR Valve Number 4 Bit";
BA_ "CI_ParId" SG_ 2566854786 EHR_EvNum_4Bit "ESMD_20935";
BA_ "CI_FullName" SG_ 2566854786 EstExtenFlow "Estimated Extend Flow";
BA_ "CI_ParId" SG_ 2566854786 EstExtenFlow "ESMD_20924";
BA_ "GenSigStartValue" SG_ 2566854786 EstExtenFlow 128;
BA_ "CI_FullName" SG_ 2566854786 EstRetractFlow "Estimated Retract Flow";
BA_ "CI_ParId" SG_ 2566854786 EstRetractFlow "ESMD_20925";
BA_ "GenSigStartValue" SG_ 2566854786 EstRetractFlow 128;
BA_ "CI_FullName" SG_ 2566854786 FailSvng "Fail Saving";
BA_ "CI_ParId" SG_ 2566854786 FailSvng "ESMD_20926";
BA_ "CI_RepetitionNum" SG_ 2566854786 MsgCnt_EHR 1;
BA_ "CI_RepetitionType" SG_ 2566854786 MsgCnt_EHR 3;
BA_ "CI_FullName" SG_ 2566854786 MsgCnt_EHR "Message Counter 2";
BA_ "CI_ParId" SG_ 2566854786 MsgCnt_EHR "ESMD_27907";
BA_ "CI_SLOT_Name" SG_ 2566854786 MsgCnt_EHR "SAEct08";
BA_ "GenSigStartValue" SG_ 2566854786 MsgCnt_EHR 12;
BA_ "SPN" SG_ 2566854786 MsgCnt_EHR 7041;
BA_ "CI_FullName" SG_ 2566854786 OpMode "Operation Mode";
BA_ "CI_ParId" SG_ 2566854786 OpMode "ESMD_20931";
BA_ "SPN_Definition" SG_ 2566854786 SpoolPosition "91";
BA_ "CI_ParId" SG_ 2566854786 SpoolPosition "ESMD_27444";
BA_ "SPN" SG_ 2566854786 SpoolPosition 91;
BA_ "SigType" SG_ 2566854786 SpoolPosition 1;
BA_ "CI_FullName" SG_ 2566854787 EHR_EvNum_4Bit "EHR Valve Number 4 Bit";
BA_ "CI_ParId" SG_ 2566854787 EHR_EvNum_4Bit "ESMD_20935";
BA_ "CI_FullName" SG_ 2566854787 EstExtenFlow "Estimated Extend Flow";
BA_ "CI_ParId" SG_ 2566854787 EstExtenFlow "ESMD_20924";
BA_ "GenSigStartValue" SG_ 2566854787 EstExtenFlow 128;
BA_ "CI_FullName" SG_ 2566854787 EstRetractFlow "Estimated Retract Flow";
BA_ "CI_ParId" SG_ 2566854787 EstRetractFlow "ESMD_20925";
BA_ "GenSigStartValue" SG_ 2566854787 EstRetractFlow 128;
BA_ "CI_FullName" SG_ 2566854787 FailSvng "Fail Saving";
BA_ "CI_ParId" SG_ 2566854787 FailSvng "ESMD_20926";
BA_ "CI_RepetitionNum" SG_ 2566854787 MsgCnt_EHR 1;
BA_ "CI_RepetitionType" SG_ 2566854787 MsgCnt_EHR 3;
BA_ "CI_FullName" SG_ 2566854787 MsgCnt_EHR "Message Counter 2";
BA_ "CI_ParId" SG_ 2566854787 MsgCnt_EHR "ESMD_27907";
BA_ "CI_SLOT_Name" SG_ 2566854787 MsgCnt_EHR "SAEct08";
BA_ "GenSigStartValue" SG_ 2566854787 MsgCnt_EHR 12;
BA_ "SPN" SG_ 2566854787 MsgCnt_EHR 7041;
BA_ "CI_FullName" SG_ 2566854787 OpMode "Operation Mode";
BA_ "CI_ParId" SG_ 2566854787 OpMode "ESMD_20931";
BA_ "SPN_Definition" SG_ 2566854787 SpoolPosition "91";
BA_ "CI_ParId" SG_ 2566854787 SpoolPosition "ESMD_27444";
BA_ "SPN" SG_ 2566854787 SpoolPosition 91;
BA_ "SigType" SG_ 2566854787 SpoolPosition 1;
BA_ "CI_FullName" SG_ 2566865536 EHR_EvNum "EHR Valve Number";
BA_ "CI_ParId" SG_ 2566865536 EHR_EvNum "ESMD_20914";
BA_ "CI_FullName" SG_ 2566865536 EHR_Err "EHR Fault";
BA_ "CI_ParId" SG_ 2566865536 EHR_Err "ESMD_20893";
BA_ "CI_FullName" SG_ 2566865536 EHR_ErrCod "EHR Fault Code";
BA_ "CI_ParId" SG_ 2566865536 EHR_ErrCod "ESMD_20896";
BA_ "CI_FullName" SG_ 2566865536 EHR_EvTemp "EHR Valve Temperature";
BA_ "CI_ParId" SG_ 2566865536 EHR_EvTemp "ESMD_20923";
BA_ "GenSigStartValue" SG_ 2566865536 EHR_EvTemp 40;
BA_ "CI_FullName" SG_ 2566865536 EHR_InitDiag "EHR Initial Diagnostic";
BA_ "CI_ParId" SG_ 2566865536 EHR_InitDiag "ESMD_20898";
BA_ "CI_FullName" SG_ 2566865536 EHR_SpoolTrav "EHR Spool Travel";
BA_ "CI_ParId" SG_ 2566865536 EHR_SpoolTrav "ESMD_20909";
BA_ "CI_FullName" SG_ 2566865536 EHR_SysId "EHR System Id";
BA_ "CI_ParId" SG_ 2566865536 EHR_SysId "ESMD_20910";
BA_ "CI_FullName" SG_ 2566865537 EHR_EvNum "EHR Valve Number";
BA_ "CI_ParId" SG_ 2566865537 EHR_EvNum "ESMD_20914";
BA_ "CI_FullName" SG_ 2566865537 EHR_Err "EHR Fault";
BA_ "CI_ParId" SG_ 2566865537 EHR_Err "ESMD_20893";
BA_ "CI_FullName" SG_ 2566865537 EHR_ErrCod "EHR Fault Code";
BA_ "CI_ParId" SG_ 2566865537 EHR_ErrCod "ESMD_20896";
BA_ "CI_FullName" SG_ 2566865537 EHR_EvTemp "EHR Valve Temperature";
BA_ "CI_ParId" SG_ 2566865537 EHR_EvTemp "ESMD_20923";
BA_ "GenSigStartValue" SG_ 2566865537 EHR_EvTemp 40;
BA_ "CI_FullName" SG_ 2566865537 EHR_InitDiag "EHR Initial Diagnostic";
BA_ "CI_ParId" SG_ 2566865537 EHR_InitDiag "ESMD_20898";
BA_ "CI_FullName" SG_ 2566865537 EHR_SpoolTrav "EHR Spool Travel";
BA_ "CI_ParId" SG_ 2566865537 EHR_SpoolTrav "ESMD_20909";
BA_ "CI_FullName" SG_ 2566865537 EHR_SysId "EHR System Id";
BA_ "CI_ParId" SG_ 2566865537 EHR_SysId "ESMD_20910";
BA_ "CI_FullName" SG_ 2566865538 EHR_EvNum "EHR Valve Number";
BA_ "CI_ParId" SG_ 2566865538 EHR_EvNum "ESMD_20914";
BA_ "CI_FullName" SG_ 2566865538 EHR_Err "EHR Fault";
BA_ "CI_ParId" SG_ 2566865538 EHR_Err "ESMD_20893";
BA_ "CI_FullName" SG_ 2566865538 EHR_ErrCod "EHR Fault Code";
BA_ "CI_ParId" SG_ 2566865538 EHR_ErrCod "ESMD_20896";
BA_ "CI_FullName" SG_ 2566865538 EHR_EvTemp "EHR Valve Temperature";
BA_ "CI_ParId" SG_ 2566865538 EHR_EvTemp "ESMD_20923";
BA_ "GenSigStartValue" SG_ 2566865538 EHR_EvTemp 40;
BA_ "CI_FullName" SG_ 2566865538 EHR_InitDiag "EHR Initial Diagnostic";
BA_ "CI_ParId" SG_ 2566865538 EHR_InitDiag "ESMD_20898";
BA_ "CI_FullName" SG_ 2566865538 EHR_SpoolTrav "EHR Spool Travel";
BA_ "CI_ParId" SG_ 2566865538 EHR_SpoolTrav "ESMD_20909";
BA_ "CI_FullName" SG_ 2566865538 EHR_SysId "EHR System Id";
BA_ "CI_ParId" SG_ 2566865538 EHR_SysId "ESMD_20910";
BA_ "CI_FullName" SG_ 2566865539 EHR_EvNum "EHR Valve Number";
BA_ "CI_ParId" SG_ 2566865539 EHR_EvNum "ESMD_20914";
BA_ "CI_FullName" SG_ 2566865539 EHR_Err "EHR Fault";
BA_ "CI_ParId" SG_ 2566865539 EHR_Err "ESMD_20893";
BA_ "CI_FullName" SG_ 2566865539 EHR_ErrCod "EHR Fault Code";
BA_ "CI_ParId" SG_ 2566865539 EHR_ErrCod "ESMD_20896";
BA_ "CI_FullName" SG_ 2566865539 EHR_EvTemp "EHR Valve Temperature";
BA_ "CI_ParId" SG_ 2566865539 EHR_EvTemp "ESMD_20923";
BA_ "GenSigStartValue" SG_ 2566865539 EHR_EvTemp 40;
BA_ "CI_FullName" SG_ 2566865539 EHR_InitDiag "EHR Initial Diagnostic";
BA_ "CI_ParId" SG_ 2566865539 EHR_InitDiag "ESMD_20898";
BA_ "CI_FullName" SG_ 2566865539 EHR_SpoolTrav "EHR Spool Travel";
BA_ "CI_ParId" SG_ 2566865539 EHR_SpoolTrav "ESMD_20909";
BA_ "CI_FullName" SG_ 2566865539 EHR_SysId "EHR System Id";
BA_ "CI_ParId" SG_ 2566865539 EHR_SysId "ESMD_20910";
BA_ "CI_FullName" SG_ 2566834816 DTC_02 "Diagnostic Trouble Code 02";
BA_ "CI_ParId" SG_ 2566834816 DTC_02 "ESMD_01143";
BA_ "CI_FullName" SG_ 2566834816 DTC_03 "Diagnostic Trouble Code 03";
BA_ "CI_ParId" SG_ 2566834816 DTC_03 "ESMD_01144";
BA_ "CI_FullName" SG_ 2566834816 DTC_04 "Diagnostic Trouble Code 04";
BA_ "CI_ParId" SG_ 2566834816 DTC_04 "ESMD_01145";
BA_ "CI_FullName" SG_ 2566834816 AmbrWarnLmp "Amber Warning Lamp";
BA_ "CI_ParId" SG_ 2566834816 AmbrWarnLmp "ESMD_00554";
BA_ "CI_SLOT_Name" SG_ 2566834816 AmbrWarnLmp "SAEbs02";
BA_ "SPN" SG_ 2566834816 AmbrWarnLmp 624;
BA_ "CI_FullName" SG_ 2566834816 DTC_01 "Diagnostic Trouble Code 01";
BA_ "CI_ParId" SG_ 2566834816 DTC_01 "ESMD_01142";
BA_ "CI_FullName" SG_ 2566834816 FlashAmbrWarnLmpAWL "Flash Amber Warning Lamp (AWL)";
BA_ "CI_ParId" SG_ 2566834816 FlashAmbrWarnLmpAWL "ESMD_01963";
BA_ "CI_SLOT_Name" SG_ 2566834816 FlashAmbrWarnLmpAWL "SAEbs02";
BA_ "SPN" SG_ 2566834816 FlashAmbrWarnLmpAWL 3040;
BA_ "CI_FullName" SG_ 2566834816 FlashMIL "Flash Malfunction Indicator Lamp";
BA_ "CI_ParId" SG_ 2566834816 FlashMIL "ESMD_01964";
BA_ "CI_SLOT_Name" SG_ 2566834816 FlashMIL "SAEbs02";
BA_ "SPN" SG_ 2566834816 FlashMIL 3038;
BA_ "CI_FullName" SG_ 2566834816 FlashProtLmp "Flash Protect Lamp";
BA_ "CI_ParId" SG_ 2566834816 FlashProtLmp "ESMD_01965";
BA_ "CI_SLOT_Name" SG_ 2566834816 FlashProtLmp "SAEbs02";
BA_ "SPN" SG_ 2566834816 FlashProtLmp 3041;
BA_ "CI_FullName" SG_ 2566834816 FlashRedStopLmpRSL "Flash Red Stop Lamp (RSL)";
BA_ "CI_ParId" SG_ 2566834816 FlashRedStopLmpRSL "ESMD_01966";
BA_ "CI_SLOT_Name" SG_ 2566834816 FlashRedStopLmpRSL "SAEbs02";
BA_ "SPN" SG_ 2566834816 FlashRedStopLmpRSL 3039;
BA_ "CI_FullName" SG_ 2566834816 MIL "Malfunction Indicator Lamp";
BA_ "CI_ParId" SG_ 2566834816 MIL "ESMD_02672";
BA_ "CI_SLOT_Name" SG_ 2566834816 MIL "SAEbs02";
BA_ "SPN" SG_ 2566834816 MIL 1213;
BA_ "CI_FullName" SG_ 2566834816 ProtLmp "Protect Lamp";
BA_ "CI_ParId" SG_ 2566834816 ProtLmp "ESMD_02904";
BA_ "CI_SLOT_Name" SG_ 2566834816 ProtLmp "SAEbs02";
BA_ "SPN" SG_ 2566834816 ProtLmp 987;
BA_ "CI_FullName" SG_ 2566834816 RedStopLmp "Red Stop Lamp";
BA_ "CI_ParId" SG_ 2566834816 RedStopLmp "ESMD_02945";
BA_ "CI_SLOT_Name" SG_ 2566834816 RedStopLmp "SAEbs02";
BA_ "SPN" SG_ 2566834816 RedStopLmp 623;
BA_ "CI_FullName" SG_ 2566834817 DTC_02 "Diagnostic Trouble Code 02";
BA_ "CI_ParId" SG_ 2566834817 DTC_02 "ESMD_01143";
BA_ "CI_FullName" SG_ 2566834817 DTC_03 "Diagnostic Trouble Code 03";
BA_ "CI_ParId" SG_ 2566834817 DTC_03 "ESMD_01144";
BA_ "CI_FullName" SG_ 2566834817 DTC_04 "Diagnostic Trouble Code 04";
BA_ "CI_ParId" SG_ 2566834817 DTC_04 "ESMD_01145";
BA_ "CI_FullName" SG_ 2566834817 AmbrWarnLmp "Amber Warning Lamp";
BA_ "CI_ParId" SG_ 2566834817 AmbrWarnLmp "ESMD_00554";
BA_ "CI_SLOT_Name" SG_ 2566834817 AmbrWarnLmp "SAEbs02";
BA_ "SPN" SG_ 2566834817 AmbrWarnLmp 624;
BA_ "CI_FullName" SG_ 2566834817 DTC_01 "Diagnostic Trouble Code 01";
BA_ "CI_ParId" SG_ 2566834817 DTC_01 "ESMD_01142";
BA_ "CI_FullName" SG_ 2566834817 FlashAmbrWarnLmpAWL "Flash Amber Warning Lamp (AWL)";
BA_ "CI_ParId" SG_ 2566834817 FlashAmbrWarnLmpAWL "ESMD_01963";
BA_ "CI_SLOT_Name" SG_ 2566834817 FlashAmbrWarnLmpAWL "SAEbs02";
BA_ "SPN" SG_ 2566834817 FlashAmbrWarnLmpAWL 3040;
BA_ "CI_FullName" SG_ 2566834817 FlashMIL "Flash Malfunction Indicator Lamp";
BA_ "CI_ParId" SG_ 2566834817 FlashMIL "ESMD_01964";
BA_ "CI_SLOT_Name" SG_ 2566834817 FlashMIL "SAEbs02";
BA_ "SPN" SG_ 2566834817 FlashMIL 3038;
BA_ "CI_FullName" SG_ 2566834817 FlashProtLmp "Flash Protect Lamp";
BA_ "CI_ParId" SG_ 2566834817 FlashProtLmp "ESMD_01965";
BA_ "CI_SLOT_Name" SG_ 2566834817 FlashProtLmp "SAEbs02";
BA_ "SPN" SG_ 2566834817 FlashProtLmp 3041;
BA_ "CI_FullName" SG_ 2566834817 FlashRedStopLmpRSL "Flash Red Stop Lamp (RSL)";
BA_ "CI_ParId" SG_ 2566834817 FlashRedStopLmpRSL "ESMD_01966";
BA_ "CI_SLOT_Name" SG_ 2566834817 FlashRedStopLmpRSL "SAEbs02";
BA_ "SPN" SG_ 2566834817 FlashRedStopLmpRSL 3039;
BA_ "CI_FullName" SG_ 2566834817 MIL "Malfunction Indicator Lamp";
BA_ "CI_ParId" SG_ 2566834817 MIL "ESMD_02672";
BA_ "CI_SLOT_Name" SG_ 2566834817 MIL "SAEbs02";
BA_ "SPN" SG_ 2566834817 MIL 1213;
BA_ "CI_FullName" SG_ 2566834817 ProtLmp "Protect Lamp";
BA_ "CI_ParId" SG_ 2566834817 ProtLmp "ESMD_02904";
BA_ "CI_SLOT_Name" SG_ 2566834817 ProtLmp "SAEbs02";
BA_ "SPN" SG_ 2566834817 ProtLmp 987;
BA_ "CI_FullName" SG_ 2566834817 RedStopLmp "Red Stop Lamp";
BA_ "CI_ParId" SG_ 2566834817 RedStopLmp "ESMD_02945";
BA_ "CI_SLOT_Name" SG_ 2566834817 RedStopLmp "SAEbs02";
BA_ "SPN" SG_ 2566834817 RedStopLmp 623;
BA_ "CI_FullName" SG_ 2566834818 DTC_02 "Diagnostic Trouble Code 02";
BA_ "CI_ParId" SG_ 2566834818 DTC_02 "ESMD_01143";
BA_ "CI_FullName" SG_ 2566834818 DTC_03 "Diagnostic Trouble Code 03";
BA_ "CI_ParId" SG_ 2566834818 DTC_03 "ESMD_01144";
BA_ "CI_FullName" SG_ 2566834818 DTC_04 "Diagnostic Trouble Code 04";
BA_ "CI_ParId" SG_ 2566834818 DTC_04 "ESMD_01145";
BA_ "CI_FullName" SG_ 2566834818 RedStopLmp "Red Stop Lamp";
BA_ "CI_ParId" SG_ 2566834818 RedStopLmp "ESMD_02945";
BA_ "CI_SLOT_Name" SG_ 2566834818 RedStopLmp "SAEbs02";
BA_ "SPN" SG_ 2566834818 RedStopLmp 623;
BA_ "CI_FullName" SG_ 2566834818 AmbrWarnLmp "Amber Warning Lamp";
BA_ "CI_ParId" SG_ 2566834818 AmbrWarnLmp "ESMD_00554";
BA_ "CI_SLOT_Name" SG_ 2566834818 AmbrWarnLmp "SAEbs02";
BA_ "SPN" SG_ 2566834818 AmbrWarnLmp 624;
BA_ "CI_FullName" SG_ 2566834818 DTC_01 "Diagnostic Trouble Code 01";
BA_ "CI_ParId" SG_ 2566834818 DTC_01 "ESMD_01142";
BA_ "CI_FullName" SG_ 2566834818 FlashAmbrWarnLmpAWL "Flash Amber Warning Lamp (AWL)";
BA_ "CI_ParId" SG_ 2566834818 FlashAmbrWarnLmpAWL "ESMD_01963";
BA_ "CI_SLOT_Name" SG_ 2566834818 FlashAmbrWarnLmpAWL "SAEbs02";
BA_ "SPN" SG_ 2566834818 FlashAmbrWarnLmpAWL 3040;
BA_ "CI_FullName" SG_ 2566834818 FlashMIL "Flash Malfunction Indicator Lamp";
BA_ "CI_ParId" SG_ 2566834818 FlashMIL "ESMD_01964";
BA_ "CI_SLOT_Name" SG_ 2566834818 FlashMIL "SAEbs02";
BA_ "SPN" SG_ 2566834818 FlashMIL 3038;
BA_ "CI_FullName" SG_ 2566834818 FlashProtLmp "Flash Protect Lamp";
BA_ "CI_ParId" SG_ 2566834818 FlashProtLmp "ESMD_01965";
BA_ "CI_SLOT_Name" SG_ 2566834818 FlashProtLmp "SAEbs02";
BA_ "SPN" SG_ 2566834818 FlashProtLmp 3041;
BA_ "CI_FullName" SG_ 2566834818 FlashRedStopLmpRSL "Flash Red Stop Lamp (RSL)";
BA_ "CI_ParId" SG_ 2566834818 FlashRedStopLmpRSL "ESMD_01966";
BA_ "CI_SLOT_Name" SG_ 2566834818 FlashRedStopLmpRSL "SAEbs02";
BA_ "SPN" SG_ 2566834818 FlashRedStopLmpRSL 3039;
BA_ "CI_FullName" SG_ 2566834818 MIL "Malfunction Indicator Lamp";
BA_ "CI_ParId" SG_ 2566834818 MIL "ESMD_02672";
BA_ "CI_SLOT_Name" SG_ 2566834818 MIL "SAEbs02";
BA_ "SPN" SG_ 2566834818 MIL 1213;
BA_ "CI_FullName" SG_ 2566834818 ProtLmp "Protect Lamp";
BA_ "CI_ParId" SG_ 2566834818 ProtLmp "ESMD_02904";
BA_ "CI_SLOT_Name" SG_ 2566834818 ProtLmp "SAEbs02";
BA_ "SPN" SG_ 2566834818 ProtLmp 987;
BA_ "CI_FullName" SG_ 2566834819 DTC_02 "Diagnostic Trouble Code 02";
BA_ "CI_ParId" SG_ 2566834819 DTC_02 "ESMD_01143";
BA_ "CI_FullName" SG_ 2566834819 DTC_03 "Diagnostic Trouble Code 03";
BA_ "CI_ParId" SG_ 2566834819 DTC_03 "ESMD_01144";
BA_ "CI_FullName" SG_ 2566834819 DTC_04 "Diagnostic Trouble Code 04";
BA_ "CI_ParId" SG_ 2566834819 DTC_04 "ESMD_01145";
BA_ "CI_FullName" SG_ 2566834819 AmbrWarnLmp "Amber Warning Lamp";
BA_ "CI_ParId" SG_ 2566834819 AmbrWarnLmp "ESMD_00554";
BA_ "CI_SLOT_Name" SG_ 2566834819 AmbrWarnLmp "SAEbs02";
BA_ "SPN" SG_ 2566834819 AmbrWarnLmp 624;
BA_ "CI_FullName" SG_ 2566834819 DTC_01 "Diagnostic Trouble Code 01";
BA_ "CI_ParId" SG_ 2566834819 DTC_01 "ESMD_01142";
BA_ "CI_FullName" SG_ 2566834819 FlashAmbrWarnLmpAWL "Flash Amber Warning Lamp (AWL)";
BA_ "CI_ParId" SG_ 2566834819 FlashAmbrWarnLmpAWL "ESMD_01963";
BA_ "CI_SLOT_Name" SG_ 2566834819 FlashAmbrWarnLmpAWL "SAEbs02";
BA_ "SPN" SG_ 2566834819 FlashAmbrWarnLmpAWL 3040;
BA_ "CI_FullName" SG_ 2566834819 FlashMIL "Flash Malfunction Indicator Lamp";
BA_ "CI_ParId" SG_ 2566834819 FlashMIL "ESMD_01964";
BA_ "CI_SLOT_Name" SG_ 2566834819 FlashMIL "SAEbs02";
BA_ "SPN" SG_ 2566834819 FlashMIL 3038;
BA_ "CI_FullName" SG_ 2566834819 FlashProtLmp "Flash Protect Lamp";
BA_ "CI_ParId" SG_ 2566834819 FlashProtLmp "ESMD_01965";
BA_ "CI_SLOT_Name" SG_ 2566834819 FlashProtLmp "SAEbs02";
BA_ "SPN" SG_ 2566834819 FlashProtLmp 3041;
BA_ "CI_FullName" SG_ 2566834819 FlashRedStopLmpRSL "Flash Red Stop Lamp (RSL)";
BA_ "CI_ParId" SG_ 2566834819 FlashRedStopLmpRSL "ESMD_01966";
BA_ "CI_SLOT_Name" SG_ 2566834819 FlashRedStopLmpRSL "SAEbs02";
BA_ "SPN" SG_ 2566834819 FlashRedStopLmpRSL 3039;
BA_ "CI_FullName" SG_ 2566834819 MIL "Malfunction Indicator Lamp";
BA_ "CI_ParId" SG_ 2566834819 MIL "ESMD_02672";
BA_ "CI_SLOT_Name" SG_ 2566834819 MIL "SAEbs02";
BA_ "SPN" SG_ 2566834819 MIL 1213;
BA_ "CI_FullName" SG_ 2566834819 ProtLmp "Protect Lamp";
BA_ "CI_ParId" SG_ 2566834819 ProtLmp "ESMD_02904";
BA_ "CI_SLOT_Name" SG_ 2566834819 ProtLmp "SAEbs02";
BA_ "SPN" SG_ 2566834819 ProtLmp 987;
BA_ "CI_FullName" SG_ 2566834819 RedStopLmp "Red Stop Lamp";
BA_ "CI_ParId" SG_ 2566834819 RedStopLmp "ESMD_02945";
BA_ "CI_SLOT_Name" SG_ 2566834819 RedStopLmp "SAEbs02";
BA_ "SPN" SG_ 2566834819 RedStopLmp 623;
BA_ "CI_FullName" SG_ 2632712064 PktDataTPDT "Packetized Data (TP.DT)";
BA_ "CI_ParId" SG_ 2632712064 PktDataTPDT "ESMD_16027";
BA_ "SPN" SG_ 2632712064 PktDataTPDT 2573;
BA_ "CI_FullName" SG_ 2632712064 SN_TPDT "Sequence Number (TP.DT)";
BA_ "CI_ParId" SG_ 2632712064 SN_TPDT "ESMD_03114";
BA_ "SPN" SG_ 2632712064 SN_TPDT 2572;
BA_ "CI_FullName" SG_ 2632712065 PktDataTPDT "Packetized Data (TP.DT)";
BA_ "CI_ParId" SG_ 2632712065 PktDataTPDT "ESMD_16027";
BA_ "SPN" SG_ 2632712065 PktDataTPDT 2573;
BA_ "CI_FullName" SG_ 2632712065 SN_TPDT "Sequence Number (TP.DT)";
BA_ "CI_ParId" SG_ 2632712065 SN_TPDT "ESMD_03114";
BA_ "SPN" SG_ 2632712065 SN_TPDT 2572;
BA_ "CI_FullName" SG_ 2632712067 PktDataTPDT "Packetized Data (TP.DT)";
BA_ "CI_ParId" SG_ 2632712067 PktDataTPDT "ESMD_16027";
BA_ "SPN" SG_ 2632712067 PktDataTPDT 2573;
BA_ "CI_FullName" SG_ 2632712067 SN_TPDT "Sequence Number (TP.DT)";
BA_ "CI_ParId" SG_ 2632712067 SN_TPDT "ESMD_03114";
BA_ "SPN" SG_ 2632712067 SN_TPDT 2572;
BA_ "CI_FullName" SG_ 2632712066 PktDataTPDT "Packetized Data (TP.DT)";
BA_ "CI_ParId" SG_ 2632712066 PktDataTPDT "ESMD_16027";
BA_ "SPN" SG_ 2632712066 PktDataTPDT 2573;
BA_ "CI_FullName" SG_ 2632712066 SN_TPDT "Sequence Number (TP.DT)";
BA_ "CI_ParId" SG_ 2632712066 SN_TPDT "ESMD_03114";
BA_ "SPN" SG_ 2632712066 SN_TPDT 2572;
BA_ "GenSigAutoGenSnd" SG_ 2632777600 ConnAbrtReason 0;
BA_ "GenSigAutoGenDsp" SG_ 2632777600 ConnAbrtReason 0;
BA_ "CI_RepetitionComplemented" SG_ 2632777600 ConnAbrtReason 2;
BA_ "CI_FullName" SG_ 2632777600 ConnAbrtReason "Connection Abort Reason";
BA_ "CI_ParId" SG_ 2632777600 ConnAbrtReason "ESMD_00939";
BA_ "SPN" SG_ 2632777600 ConnAbrtReason 2570;
BA_ "GenSigAutoGenSnd" SG_ 2632777600 MaxNumPktTPCM_RTS 0;
BA_ "GenSigAutoGenDsp" SG_ 2632777600 MaxNumPktTPCM_RTS 0;
BA_ "CI_RepetitionComplemented" SG_ 2632777600 MaxNumPktTPCM_RTS 2;
BA_ "CI_FullName" SG_ 2632777600 MaxNumPktTPCM_RTS "Maximum Number of Packets (TP.CM_RTS)";
BA_ "CI_ParId" SG_ 2632777600 MaxNumPktTPCM_RTS "ESMD_02684";
BA_ "SPN" SG_ 2632777600 MaxNumPktTPCM_RTS 2559;
BA_ "GenSigAutoGenSnd" SG_ 2632777600 NumPktSentTPCM_CTS 0;
BA_ "GenSigAutoGenDsp" SG_ 2632777600 NumPktSentTPCM_CTS 0;
BA_ "CI_RepetitionComplemented" SG_ 2632777600 NumPktSentTPCM_CTS 2;
BA_ "CI_FullName" SG_ 2632777600 NumPktSentTPCM_CTS "Number of Packets that can be sent (TP.CM_CTS)";
BA_ "CI_ParId" SG_ 2632777600 NumPktSentTPCM_CTS "ESMD_02790";
BA_ "SPN" SG_ 2632777600 NumPktSentTPCM_CTS 2561;
BA_ "GenSigAutoGenSnd" SG_ 2632777600 NxtPktNumSentTPCM_CTS 0;
BA_ "GenSigAutoGenDsp" SG_ 2632777600 NxtPktNumSentTPCM_CTS 0;
BA_ "CI_RepetitionComplemented" SG_ 2632777600 NxtPktNumSentTPCM_CTS 2;
BA_ "CI_FullName" SG_ 2632777600 NxtPktNumSentTPCM_CTS "Next Packet Number to be sent (TP.CM_CTS)";
BA_ "CI_ParId" SG_ 2632777600 NxtPktNumSentTPCM_CTS "ESMD_02740";
BA_ "SPN" SG_ 2632777600 NxtPktNumSentTPCM_CTS 2562;
BA_ "GenSigAutoGenSnd" SG_ 2632777600 PGN_PktMsgTPCM_BAM 0;
BA_ "GenSigAutoGenDsp" SG_ 2632777600 PGN_PktMsgTPCM_BAM 0;
BA_ "CI_RepetitionComplemented" SG_ 2632777600 PGN_PktMsgTPCM_BAM 2;
BA_ "CI_FullName" SG_ 2632777600 PGN_PktMsgTPCM_BAM "Parameter Group Number of the packeted message (TP.CM_BAM)";
BA_ "CI_ParId" SG_ 2632777600 PGN_PktMsgTPCM_BAM "ESMD_03861";
BA_ "SPN" SG_ 2632777600 PGN_PktMsgTPCM_BAM 2569;
BA_ "GenSigAutoGenSnd" SG_ 2632777600 PGN_PktMsgTPCM_ConnAbort 0;
BA_ "GenSigAutoGenDsp" SG_ 2632777600 PGN_PktMsgTPCM_ConnAbort 0;
BA_ "CI_RepetitionComplemented" SG_ 2632777600 PGN_PktMsgTPCM_ConnAbort 2;
BA_ "CI_FullName" SG_ 2632777600 PGN_PktMsgTPCM_ConnAbort "Parameter Group Number of the packeted message (TP.CM_Conn_Abort)";
BA_ "CI_ParId" SG_ 2632777600 PGN_PktMsgTPCM_ConnAbort "ESMD_03862";
BA_ "SPN" SG_ 2632777600 PGN_PktMsgTPCM_ConnAbort 2571;
BA_ "GenSigAutoGenSnd" SG_ 2632777600 PGN_PktMsgTPCM_CTS 0;
BA_ "GenSigAutoGenDsp" SG_ 2632777600 PGN_PktMsgTPCM_CTS 0;
BA_ "CI_RepetitionComplemented" SG_ 2632777600 PGN_PktMsgTPCM_CTS 2;
BA_ "CI_FullName" SG_ 2632777600 PGN_PktMsgTPCM_CTS "Parameter Group Number of the packeted message (TP.CM_CTS)";
BA_ "CI_ParId" SG_ 2632777600 PGN_PktMsgTPCM_CTS "ESMD_03859";
BA_ "SPN" SG_ 2632777600 PGN_PktMsgTPCM_CTS 2563;
BA_ "GenSigAutoGenSnd" SG_ 2632777600 PGN_PktMsgTPCM_RTS 0;
BA_ "GenSigAutoGenDsp" SG_ 2632777600 PGN_PktMsgTPCM_RTS 0;
BA_ "CI_RepetitionComplemented" SG_ 2632777600 PGN_PktMsgTPCM_RTS 2;
BA_ "CI_FullName" SG_ 2632777600 PGN_PktMsgTPCM_RTS "Parameter Group Number of the packeted message (TP.CM_RTS)";
BA_ "CI_ParId" SG_ 2632777600 PGN_PktMsgTPCM_RTS "ESMD_02869";
BA_ "SPN" SG_ 2632777600 PGN_PktMsgTPCM_RTS 2560;
BA_ "CI_FullName" SG_ 2632777600 PGN_PktMsgTPCM_RTS2 "Parameter Group Number of the packeted message (TP.CM_RTS) 2";
BA_ "CI_ParId" SG_ 2632777600 PGN_PktMsgTPCM_RTS2 "ESMD_03860";
BA_ "SPN" SG_ 2632777600 PGN_PktMsgTPCM_RTS2 2566;
BA_ "GenSigAutoGenSnd" SG_ 2632777600 TotMsgSizeBAM 0;
BA_ "GenSigAutoGenDsp" SG_ 2632777600 TotMsgSizeBAM 0;
BA_ "CI_RepetitionComplemented" SG_ 2632777600 TotMsgSizeBAM 2;
BA_ "CI_FullName" SG_ 2632777600 TotMsgSizeBAM "_";
BA_ "CI_ParId" SG_ 2632777600 TotMsgSizeBAM "ESMD_03432";
BA_ "SPN" SG_ 2632777600 TotMsgSizeBAM 2567;
BA_ "GenSigAutoGenSnd" SG_ 2632777600 TotMsgSizeEoMA 0;
BA_ "GenSigAutoGenDsp" SG_ 2632777600 TotMsgSizeEoMA 0;
BA_ "CI_RepetitionComplemented" SG_ 2632777600 TotMsgSizeEoMA 2;
BA_ "CI_FullName" SG_ 2632777600 TotMsgSizeEoMA "_";
BA_ "CI_ParId" SG_ 2632777600 TotMsgSizeEoMA "ESMD_03433";
BA_ "SPN" SG_ 2632777600 TotMsgSizeEoMA 2564;
BA_ "GenSigAutoGenSnd" SG_ 2632777600 TotMsgSizeTPCM_RTS 0;
BA_ "GenSigAutoGenDsp" SG_ 2632777600 TotMsgSizeTPCM_RTS 0;
BA_ "CI_RepetitionComplemented" SG_ 2632777600 TotMsgSizeTPCM_RTS 2;
BA_ "CI_FullName" SG_ 2632777600 TotMsgSizeTPCM_RTS "Total Message Size (TP.CM_RTS)";
BA_ "CI_ParId" SG_ 2632777600 TotMsgSizeTPCM_RTS "ESMD_03431";
BA_ "SPN" SG_ 2632777600 TotMsgSizeTPCM_RTS 2557;
BA_ "GenSigAutoGenSnd" SG_ 2632777600 TotNumPktBAM 0;
BA_ "GenSigAutoGenDsp" SG_ 2632777600 TotNumPktBAM 0;
BA_ "CI_RepetitionComplemented" SG_ 2632777600 TotNumPktBAM 2;
BA_ "CI_FullName" SG_ 2632777600 TotNumPktBAM "_";
BA_ "CI_ParId" SG_ 2632777600 TotNumPktBAM "ESMD_03435";
BA_ "SPN" SG_ 2632777600 TotNumPktBAM 2568;
BA_ "GenSigAutoGenSnd" SG_ 2632777600 TotNumPktEoMA 0;
BA_ "GenSigAutoGenDsp" SG_ 2632777600 TotNumPktEoMA 0;
BA_ "CI_RepetitionComplemented" SG_ 2632777600 TotNumPktEoMA 2;
BA_ "CI_FullName" SG_ 2632777600 TotNumPktEoMA "_";
BA_ "CI_ParId" SG_ 2632777600 TotNumPktEoMA "ESMD_03436";
BA_ "SPN" SG_ 2632777600 TotNumPktEoMA 2565;
BA_ "GenSigAutoGenSnd" SG_ 2632777600 TotNumPktTPCM_RTS 0;
BA_ "GenSigAutoGenDsp" SG_ 2632777600 TotNumPktTPCM_RTS 0;
BA_ "CI_RepetitionComplemented" SG_ 2632777600 TotNumPktTPCM_RTS 2;
BA_ "CI_FullName" SG_ 2632777600 TotNumPktTPCM_RTS "Total Number of Packets (TP.CM_RTS)";
BA_ "CI_ParId" SG_ 2632777600 TotNumPktTPCM_RTS "ESMD_03434";
BA_ "SPN" SG_ 2632777600 TotNumPktTPCM_RTS 2558;
BA_ "GenSigAutoGenSnd" SG_ 2632777600 CByteTPCM 0;
BA_ "GenSigAutoGenDsp" SG_ 2632777600 CByteTPCM 0;
BA_ "CI_RepetitionComplemented" SG_ 2632777600 CByteTPCM 2;
BA_ "CI_FullName" SG_ 2632777600 CByteTPCM "Control Byte (TP.CM)";
BA_ "CI_ParId" SG_ 2632777600 CByteTPCM "ESMD_00941";
BA_ "SPN" SG_ 2632777600 CByteTPCM 2556;
BA_ "GenSigAutoGenSnd" SG_ 2632777601 ConnAbrtReason 0;
BA_ "GenSigAutoGenDsp" SG_ 2632777601 ConnAbrtReason 0;
BA_ "CI_RepetitionComplemented" SG_ 2632777601 ConnAbrtReason 2;
BA_ "CI_FullName" SG_ 2632777601 ConnAbrtReason "Connection Abort Reason";
BA_ "CI_ParId" SG_ 2632777601 ConnAbrtReason "ESMD_00939";
BA_ "SPN" SG_ 2632777601 ConnAbrtReason 2570;
BA_ "GenSigAutoGenSnd" SG_ 2632777601 MaxNumPktTPCM_RTS 0;
BA_ "GenSigAutoGenDsp" SG_ 2632777601 MaxNumPktTPCM_RTS 0;
BA_ "CI_RepetitionComplemented" SG_ 2632777601 MaxNumPktTPCM_RTS 2;
BA_ "CI_FullName" SG_ 2632777601 MaxNumPktTPCM_RTS "Maximum Number of Packets (TP.CM_RTS)";
BA_ "CI_ParId" SG_ 2632777601 MaxNumPktTPCM_RTS "ESMD_02684";
BA_ "SPN" SG_ 2632777601 MaxNumPktTPCM_RTS 2559;
BA_ "GenSigAutoGenSnd" SG_ 2632777601 NumPktSentTPCM_CTS 0;
BA_ "GenSigAutoGenDsp" SG_ 2632777601 NumPktSentTPCM_CTS 0;
BA_ "CI_RepetitionComplemented" SG_ 2632777601 NumPktSentTPCM_CTS 2;
BA_ "CI_FullName" SG_ 2632777601 NumPktSentTPCM_CTS "Number of Packets that can be sent (TP.CM_CTS)";
BA_ "CI_ParId" SG_ 2632777601 NumPktSentTPCM_CTS "ESMD_02790";
BA_ "SPN" SG_ 2632777601 NumPktSentTPCM_CTS 2561;
BA_ "GenSigAutoGenSnd" SG_ 2632777601 NxtPktNumSentTPCM_CTS 0;
BA_ "GenSigAutoGenDsp" SG_ 2632777601 NxtPktNumSentTPCM_CTS 0;
BA_ "CI_RepetitionComplemented" SG_ 2632777601 NxtPktNumSentTPCM_CTS 2;
BA_ "CI_FullName" SG_ 2632777601 NxtPktNumSentTPCM_CTS "Next Packet Number to be sent (TP.CM_CTS)";
BA_ "CI_ParId" SG_ 2632777601 NxtPktNumSentTPCM_CTS "ESMD_02740";
BA_ "SPN" SG_ 2632777601 NxtPktNumSentTPCM_CTS 2562;
BA_ "GenSigAutoGenSnd" SG_ 2632777601 PGN_PktMsgTPCM_BAM 0;
BA_ "GenSigAutoGenDsp" SG_ 2632777601 PGN_PktMsgTPCM_BAM 0;
BA_ "CI_RepetitionComplemented" SG_ 2632777601 PGN_PktMsgTPCM_BAM 2;
BA_ "CI_FullName" SG_ 2632777601 PGN_PktMsgTPCM_BAM "Parameter Group Number of the packeted message (TP.CM_BAM)";
BA_ "CI_ParId" SG_ 2632777601 PGN_PktMsgTPCM_BAM "ESMD_03861";
BA_ "SPN" SG_ 2632777601 PGN_PktMsgTPCM_BAM 2569;
BA_ "GenSigAutoGenSnd" SG_ 2632777601 PGN_PktMsgTPCM_ConnAbort 0;
BA_ "GenSigAutoGenDsp" SG_ 2632777601 PGN_PktMsgTPCM_ConnAbort 0;
BA_ "CI_RepetitionComplemented" SG_ 2632777601 PGN_PktMsgTPCM_ConnAbort 2;
BA_ "CI_FullName" SG_ 2632777601 PGN_PktMsgTPCM_ConnAbort "Parameter Group Number of the packeted message (TP.CM_Conn_Abort)";
BA_ "CI_ParId" SG_ 2632777601 PGN_PktMsgTPCM_ConnAbort "ESMD_03862";
BA_ "SPN" SG_ 2632777601 PGN_PktMsgTPCM_ConnAbort 2571;
BA_ "GenSigAutoGenSnd" SG_ 2632777601 PGN_PktMsgTPCM_CTS 0;
BA_ "GenSigAutoGenDsp" SG_ 2632777601 PGN_PktMsgTPCM_CTS 0;
BA_ "CI_RepetitionComplemented" SG_ 2632777601 PGN_PktMsgTPCM_CTS 2;
BA_ "CI_FullName" SG_ 2632777601 PGN_PktMsgTPCM_CTS "Parameter Group Number of the packeted message (TP.CM_CTS)";
BA_ "CI_ParId" SG_ 2632777601 PGN_PktMsgTPCM_CTS "ESMD_03859";
BA_ "SPN" SG_ 2632777601 PGN_PktMsgTPCM_CTS 2563;
BA_ "GenSigAutoGenSnd" SG_ 2632777601 PGN_PktMsgTPCM_RTS 0;
BA_ "GenSigAutoGenDsp" SG_ 2632777601 PGN_PktMsgTPCM_RTS 0;
BA_ "CI_RepetitionComplemented" SG_ 2632777601 PGN_PktMsgTPCM_RTS 2;
BA_ "CI_FullName" SG_ 2632777601 PGN_PktMsgTPCM_RTS "Parameter Group Number of the packeted message (TP.CM_RTS)";
BA_ "CI_ParId" SG_ 2632777601 PGN_PktMsgTPCM_RTS "ESMD_02869";
BA_ "SPN" SG_ 2632777601 PGN_PktMsgTPCM_RTS 2560;
BA_ "CI_FullName" SG_ 2632777601 PGN_PktMsgTPCM_RTS2 "Parameter Group Number of the packeted message (TP.CM_RTS) 2";
BA_ "CI_ParId" SG_ 2632777601 PGN_PktMsgTPCM_RTS2 "ESMD_03860";
BA_ "SPN" SG_ 2632777601 PGN_PktMsgTPCM_RTS2 2566;
BA_ "GenSigAutoGenSnd" SG_ 2632777601 TotMsgSizeBAM 0;
BA_ "GenSigAutoGenDsp" SG_ 2632777601 TotMsgSizeBAM 0;
BA_ "CI_RepetitionComplemented" SG_ 2632777601 TotMsgSizeBAM 2;
BA_ "CI_FullName" SG_ 2632777601 TotMsgSizeBAM "_";
BA_ "CI_ParId" SG_ 2632777601 TotMsgSizeBAM "ESMD_03432";
BA_ "SPN" SG_ 2632777601 TotMsgSizeBAM 2567;
BA_ "GenSigAutoGenSnd" SG_ 2632777601 TotMsgSizeEoMA 0;
BA_ "GenSigAutoGenDsp" SG_ 2632777601 TotMsgSizeEoMA 0;
BA_ "CI_RepetitionComplemented" SG_ 2632777601 TotMsgSizeEoMA 2;
BA_ "CI_FullName" SG_ 2632777601 TotMsgSizeEoMA "_";
BA_ "CI_ParId" SG_ 2632777601 TotMsgSizeEoMA "ESMD_03433";
BA_ "SPN" SG_ 2632777601 TotMsgSizeEoMA 2564;
BA_ "GenSigAutoGenSnd" SG_ 2632777601 TotMsgSizeTPCM_RTS 0;
BA_ "GenSigAutoGenDsp" SG_ 2632777601 TotMsgSizeTPCM_RTS 0;
BA_ "CI_RepetitionComplemented" SG_ 2632777601 TotMsgSizeTPCM_RTS 2;
BA_ "CI_FullName" SG_ 2632777601 TotMsgSizeTPCM_RTS "Total Message Size (TP.CM_RTS)";
BA_ "CI_ParId" SG_ 2632777601 TotMsgSizeTPCM_RTS "ESMD_03431";
BA_ "SPN" SG_ 2632777601 TotMsgSizeTPCM_RTS 2557;
BA_ "GenSigAutoGenSnd" SG_ 2632777601 TotNumPktBAM 0;
BA_ "GenSigAutoGenDsp" SG_ 2632777601 TotNumPktBAM 0;
BA_ "CI_RepetitionComplemented" SG_ 2632777601 TotNumPktBAM 2;
BA_ "CI_FullName" SG_ 2632777601 TotNumPktBAM "_";
BA_ "CI_ParId" SG_ 2632777601 TotNumPktBAM "ESMD_03435";
BA_ "SPN" SG_ 2632777601 TotNumPktBAM 2568;
BA_ "GenSigAutoGenSnd" SG_ 2632777601 TotNumPktEoMA 0;
BA_ "GenSigAutoGenDsp" SG_ 2632777601 TotNumPktEoMA 0;
BA_ "CI_RepetitionComplemented" SG_ 2632777601 TotNumPktEoMA 2;
BA_ "CI_FullName" SG_ 2632777601 TotNumPktEoMA "_";
BA_ "CI_ParId" SG_ 2632777601 TotNumPktEoMA "ESMD_03436";
BA_ "SPN" SG_ 2632777601 TotNumPktEoMA 2565;
BA_ "GenSigAutoGenSnd" SG_ 2632777601 TotNumPktTPCM_RTS 0;
BA_ "GenSigAutoGenDsp" SG_ 2632777601 TotNumPktTPCM_RTS 0;
BA_ "CI_RepetitionComplemented" SG_ 2632777601 TotNumPktTPCM_RTS 2;
BA_ "CI_FullName" SG_ 2632777601 TotNumPktTPCM_RTS "Total Number of Packets (TP.CM_RTS)";
BA_ "CI_ParId" SG_ 2632777601 TotNumPktTPCM_RTS "ESMD_03434";
BA_ "SPN" SG_ 2632777601 TotNumPktTPCM_RTS 2558;
BA_ "GenSigAutoGenSnd" SG_ 2632777601 CByteTPCM 0;
BA_ "GenSigAutoGenDsp" SG_ 2632777601 CByteTPCM 0;
BA_ "CI_RepetitionComplemented" SG_ 2632777601 CByteTPCM 2;
BA_ "CI_FullName" SG_ 2632777601 CByteTPCM "Control Byte (TP.CM)";
BA_ "CI_ParId" SG_ 2632777601 CByteTPCM "ESMD_00941";
BA_ "SPN" SG_ 2632777601 CByteTPCM 2556;
BA_ "GenSigAutoGenSnd" SG_ 2632777602 ConnAbrtReason 0;
BA_ "GenSigAutoGenDsp" SG_ 2632777602 ConnAbrtReason 0;
BA_ "CI_RepetitionComplemented" SG_ 2632777602 ConnAbrtReason 2;
BA_ "CI_FullName" SG_ 2632777602 ConnAbrtReason "Connection Abort Reason";
BA_ "CI_ParId" SG_ 2632777602 ConnAbrtReason "ESMD_00939";
BA_ "SPN" SG_ 2632777602 ConnAbrtReason 2570;
BA_ "GenSigAutoGenSnd" SG_ 2632777602 MaxNumPktTPCM_RTS 0;
BA_ "GenSigAutoGenDsp" SG_ 2632777602 MaxNumPktTPCM_RTS 0;
BA_ "CI_RepetitionComplemented" SG_ 2632777602 MaxNumPktTPCM_RTS 2;
BA_ "CI_FullName" SG_ 2632777602 MaxNumPktTPCM_RTS "Maximum Number of Packets (TP.CM_RTS)";
BA_ "CI_ParId" SG_ 2632777602 MaxNumPktTPCM_RTS "ESMD_02684";
BA_ "SPN" SG_ 2632777602 MaxNumPktTPCM_RTS 2559;
BA_ "GenSigAutoGenSnd" SG_ 2632777602 NumPktSentTPCM_CTS 0;
BA_ "GenSigAutoGenDsp" SG_ 2632777602 NumPktSentTPCM_CTS 0;
BA_ "CI_RepetitionComplemented" SG_ 2632777602 NumPktSentTPCM_CTS 2;
BA_ "CI_FullName" SG_ 2632777602 NumPktSentTPCM_CTS "Number of Packets that can be sent (TP.CM_CTS)";
BA_ "CI_ParId" SG_ 2632777602 NumPktSentTPCM_CTS "ESMD_02790";
BA_ "SPN" SG_ 2632777602 NumPktSentTPCM_CTS 2561;
BA_ "GenSigAutoGenSnd" SG_ 2632777602 NxtPktNumSentTPCM_CTS 0;
BA_ "GenSigAutoGenDsp" SG_ 2632777602 NxtPktNumSentTPCM_CTS 0;
BA_ "CI_RepetitionComplemented" SG_ 2632777602 NxtPktNumSentTPCM_CTS 2;
BA_ "CI_FullName" SG_ 2632777602 NxtPktNumSentTPCM_CTS "Next Packet Number to be sent (TP.CM_CTS)";
BA_ "CI_ParId" SG_ 2632777602 NxtPktNumSentTPCM_CTS "ESMD_02740";
BA_ "SPN" SG_ 2632777602 NxtPktNumSentTPCM_CTS 2562;
BA_ "GenSigAutoGenSnd" SG_ 2632777602 PGN_PktMsgTPCM_BAM 0;
BA_ "GenSigAutoGenDsp" SG_ 2632777602 PGN_PktMsgTPCM_BAM 0;
BA_ "CI_RepetitionComplemented" SG_ 2632777602 PGN_PktMsgTPCM_BAM 2;
BA_ "CI_FullName" SG_ 2632777602 PGN_PktMsgTPCM_BAM "Parameter Group Number of the packeted message (TP.CM_BAM)";
BA_ "CI_ParId" SG_ 2632777602 PGN_PktMsgTPCM_BAM "ESMD_03861";
BA_ "SPN" SG_ 2632777602 PGN_PktMsgTPCM_BAM 2569;
BA_ "GenSigAutoGenSnd" SG_ 2632777602 PGN_PktMsgTPCM_ConnAbort 0;
BA_ "GenSigAutoGenDsp" SG_ 2632777602 PGN_PktMsgTPCM_ConnAbort 0;
BA_ "CI_RepetitionComplemented" SG_ 2632777602 PGN_PktMsgTPCM_ConnAbort 2;
BA_ "CI_FullName" SG_ 2632777602 PGN_PktMsgTPCM_ConnAbort "Parameter Group Number of the packeted message (TP.CM_Conn_Abort)";
BA_ "CI_ParId" SG_ 2632777602 PGN_PktMsgTPCM_ConnAbort "ESMD_03862";
BA_ "SPN" SG_ 2632777602 PGN_PktMsgTPCM_ConnAbort 2571;
BA_ "GenSigAutoGenSnd" SG_ 2632777602 PGN_PktMsgTPCM_CTS 0;
BA_ "GenSigAutoGenDsp" SG_ 2632777602 PGN_PktMsgTPCM_CTS 0;
BA_ "CI_RepetitionComplemented" SG_ 2632777602 PGN_PktMsgTPCM_CTS 2;
BA_ "CI_FullName" SG_ 2632777602 PGN_PktMsgTPCM_CTS "Parameter Group Number of the packeted message (TP.CM_CTS)";
BA_ "CI_ParId" SG_ 2632777602 PGN_PktMsgTPCM_CTS "ESMD_03859";
BA_ "SPN" SG_ 2632777602 PGN_PktMsgTPCM_CTS 2563;
BA_ "GenSigAutoGenSnd" SG_ 2632777602 PGN_PktMsgTPCM_RTS 0;
BA_ "GenSigAutoGenDsp" SG_ 2632777602 PGN_PktMsgTPCM_RTS 0;
BA_ "CI_RepetitionComplemented" SG_ 2632777602 PGN_PktMsgTPCM_RTS 2;
BA_ "CI_FullName" SG_ 2632777602 PGN_PktMsgTPCM_RTS "Parameter Group Number of the packeted message (TP.CM_RTS)";
BA_ "CI_ParId" SG_ 2632777602 PGN_PktMsgTPCM_RTS "ESMD_02869";
BA_ "SPN" SG_ 2632777602 PGN_PktMsgTPCM_RTS 2560;
BA_ "CI_FullName" SG_ 2632777602 PGN_PktMsgTPCM_RTS2 "Parameter Group Number of the packeted message (TP.CM_RTS) 2";
BA_ "CI_ParId" SG_ 2632777602 PGN_PktMsgTPCM_RTS2 "ESMD_03860";
BA_ "SPN" SG_ 2632777602 PGN_PktMsgTPCM_RTS2 2566;
BA_ "GenSigAutoGenSnd" SG_ 2632777602 TotMsgSizeBAM 0;
BA_ "GenSigAutoGenDsp" SG_ 2632777602 TotMsgSizeBAM 0;
BA_ "CI_RepetitionComplemented" SG_ 2632777602 TotMsgSizeBAM 2;
BA_ "CI_FullName" SG_ 2632777602 TotMsgSizeBAM "_";
BA_ "CI_ParId" SG_ 2632777602 TotMsgSizeBAM "ESMD_03432";
BA_ "SPN" SG_ 2632777602 TotMsgSizeBAM 2567;
BA_ "GenSigAutoGenSnd" SG_ 2632777602 TotMsgSizeEoMA 0;
BA_ "GenSigAutoGenDsp" SG_ 2632777602 TotMsgSizeEoMA 0;
BA_ "CI_RepetitionComplemented" SG_ 2632777602 TotMsgSizeEoMA 2;
BA_ "CI_FullName" SG_ 2632777602 TotMsgSizeEoMA "_";
BA_ "CI_ParId" SG_ 2632777602 TotMsgSizeEoMA "ESMD_03433";
BA_ "SPN" SG_ 2632777602 TotMsgSizeEoMA 2564;
BA_ "GenSigAutoGenSnd" SG_ 2632777602 TotMsgSizeTPCM_RTS 0;
BA_ "GenSigAutoGenDsp" SG_ 2632777602 TotMsgSizeTPCM_RTS 0;
BA_ "CI_RepetitionComplemented" SG_ 2632777602 TotMsgSizeTPCM_RTS 2;
BA_ "CI_FullName" SG_ 2632777602 TotMsgSizeTPCM_RTS "Total Message Size (TP.CM_RTS)";
BA_ "CI_ParId" SG_ 2632777602 TotMsgSizeTPCM_RTS "ESMD_03431";
BA_ "SPN" SG_ 2632777602 TotMsgSizeTPCM_RTS 2557;
BA_ "GenSigAutoGenSnd" SG_ 2632777602 TotNumPktBAM 0;
BA_ "GenSigAutoGenDsp" SG_ 2632777602 TotNumPktBAM 0;
BA_ "CI_RepetitionComplemented" SG_ 2632777602 TotNumPktBAM 2;
BA_ "CI_FullName" SG_ 2632777602 TotNumPktBAM "_";
BA_ "CI_ParId" SG_ 2632777602 TotNumPktBAM "ESMD_03435";
BA_ "SPN" SG_ 2632777602 TotNumPktBAM 2568;
BA_ "GenSigAutoGenSnd" SG_ 2632777602 TotNumPktEoMA 0;
BA_ "GenSigAutoGenDsp" SG_ 2632777602 TotNumPktEoMA 0;
BA_ "CI_RepetitionComplemented" SG_ 2632777602 TotNumPktEoMA 2;
BA_ "CI_FullName" SG_ 2632777602 TotNumPktEoMA "_";
BA_ "CI_ParId" SG_ 2632777602 TotNumPktEoMA "ESMD_03436";
BA_ "SPN" SG_ 2632777602 TotNumPktEoMA 2565;
BA_ "GenSigAutoGenSnd" SG_ 2632777602 TotNumPktTPCM_RTS 0;
BA_ "GenSigAutoGenDsp" SG_ 2632777602 TotNumPktTPCM_RTS 0;
BA_ "CI_RepetitionComplemented" SG_ 2632777602 TotNumPktTPCM_RTS 2;
BA_ "CI_FullName" SG_ 2632777602 TotNumPktTPCM_RTS "Total Number of Packets (TP.CM_RTS)";
BA_ "CI_ParId" SG_ 2632777602 TotNumPktTPCM_RTS "ESMD_03434";
BA_ "SPN" SG_ 2632777602 TotNumPktTPCM_RTS 2558;
BA_ "GenSigAutoGenSnd" SG_ 2632777602 CByteTPCM 0;
BA_ "GenSigAutoGenDsp" SG_ 2632777602 CByteTPCM 0;
BA_ "CI_RepetitionComplemented" SG_ 2632777602 CByteTPCM 2;
BA_ "CI_FullName" SG_ 2632777602 CByteTPCM "Control Byte (TP.CM)";
BA_ "CI_ParId" SG_ 2632777602 CByteTPCM "ESMD_00941";
BA_ "SPN" SG_ 2632777602 CByteTPCM 2556;
BA_ "GenSigAutoGenSnd" SG_ 2632777603 ConnAbrtReason 0;
BA_ "GenSigAutoGenDsp" SG_ 2632777603 ConnAbrtReason 0;
BA_ "CI_RepetitionComplemented" SG_ 2632777603 ConnAbrtReason 2;
BA_ "CI_FullName" SG_ 2632777603 ConnAbrtReason "Connection Abort Reason";
BA_ "CI_ParId" SG_ 2632777603 ConnAbrtReason "ESMD_00939";
BA_ "SPN" SG_ 2632777603 ConnAbrtReason 2570;
BA_ "GenSigAutoGenSnd" SG_ 2632777603 MaxNumPktTPCM_RTS 0;
BA_ "GenSigAutoGenDsp" SG_ 2632777603 MaxNumPktTPCM_RTS 0;
BA_ "CI_RepetitionComplemented" SG_ 2632777603 MaxNumPktTPCM_RTS 2;
BA_ "CI_FullName" SG_ 2632777603 MaxNumPktTPCM_RTS "Maximum Number of Packets (TP.CM_RTS)";
BA_ "CI_ParId" SG_ 2632777603 MaxNumPktTPCM_RTS "ESMD_02684";
BA_ "SPN" SG_ 2632777603 MaxNumPktTPCM_RTS 2559;
BA_ "GenSigAutoGenSnd" SG_ 2632777603 NumPktSentTPCM_CTS 0;
BA_ "GenSigAutoGenDsp" SG_ 2632777603 NumPktSentTPCM_CTS 0;
BA_ "CI_RepetitionComplemented" SG_ 2632777603 NumPktSentTPCM_CTS 2;
BA_ "CI_FullName" SG_ 2632777603 NumPktSentTPCM_CTS "Number of Packets that can be sent (TP.CM_CTS)";
BA_ "CI_ParId" SG_ 2632777603 NumPktSentTPCM_CTS "ESMD_02790";
BA_ "SPN" SG_ 2632777603 NumPktSentTPCM_CTS 2561;
BA_ "GenSigAutoGenSnd" SG_ 2632777603 NxtPktNumSentTPCM_CTS 0;
BA_ "GenSigAutoGenDsp" SG_ 2632777603 NxtPktNumSentTPCM_CTS 0;
BA_ "CI_RepetitionComplemented" SG_ 2632777603 NxtPktNumSentTPCM_CTS 2;
BA_ "CI_FullName" SG_ 2632777603 NxtPktNumSentTPCM_CTS "Next Packet Number to be sent (TP.CM_CTS)";
BA_ "CI_ParId" SG_ 2632777603 NxtPktNumSentTPCM_CTS "ESMD_02740";
BA_ "SPN" SG_ 2632777603 NxtPktNumSentTPCM_CTS 2562;
BA_ "GenSigAutoGenSnd" SG_ 2632777603 PGN_PktMsgTPCM_BAM 0;
BA_ "GenSigAutoGenDsp" SG_ 2632777603 PGN_PktMsgTPCM_BAM 0;
BA_ "CI_RepetitionComplemented" SG_ 2632777603 PGN_PktMsgTPCM_BAM 2;
BA_ "CI_FullName" SG_ 2632777603 PGN_PktMsgTPCM_BAM "Parameter Group Number of the packeted message (TP.CM_BAM)";
BA_ "CI_ParId" SG_ 2632777603 PGN_PktMsgTPCM_BAM "ESMD_03861";
BA_ "SPN" SG_ 2632777603 PGN_PktMsgTPCM_BAM 2569;
BA_ "GenSigAutoGenSnd" SG_ 2632777603 PGN_PktMsgTPCM_ConnAbort 0;
BA_ "GenSigAutoGenDsp" SG_ 2632777603 PGN_PktMsgTPCM_ConnAbort 0;
BA_ "CI_RepetitionComplemented" SG_ 2632777603 PGN_PktMsgTPCM_ConnAbort 2;
BA_ "CI_FullName" SG_ 2632777603 PGN_PktMsgTPCM_ConnAbort "Parameter Group Number of the packeted message (TP.CM_Conn_Abort)";
BA_ "CI_ParId" SG_ 2632777603 PGN_PktMsgTPCM_ConnAbort "ESMD_03862";
BA_ "SPN" SG_ 2632777603 PGN_PktMsgTPCM_ConnAbort 2571;
BA_ "GenSigAutoGenSnd" SG_ 2632777603 PGN_PktMsgTPCM_CTS 0;
BA_ "GenSigAutoGenDsp" SG_ 2632777603 PGN_PktMsgTPCM_CTS 0;
BA_ "CI_RepetitionComplemented" SG_ 2632777603 PGN_PktMsgTPCM_CTS 2;
BA_ "CI_FullName" SG_ 2632777603 PGN_PktMsgTPCM_CTS "Parameter Group Number of the packeted message (TP.CM_CTS)";
BA_ "CI_ParId" SG_ 2632777603 PGN_PktMsgTPCM_CTS "ESMD_03859";
BA_ "SPN" SG_ 2632777603 PGN_PktMsgTPCM_CTS 2563;
BA_ "GenSigAutoGenSnd" SG_ 2632777603 PGN_PktMsgTPCM_RTS 0;
BA_ "GenSigAutoGenDsp" SG_ 2632777603 PGN_PktMsgTPCM_RTS 0;
BA_ "CI_RepetitionComplemented" SG_ 2632777603 PGN_PktMsgTPCM_RTS 2;
BA_ "CI_FullName" SG_ 2632777603 PGN_PktMsgTPCM_RTS "Parameter Group Number of the packeted message (TP.CM_RTS)";
BA_ "CI_ParId" SG_ 2632777603 PGN_PktMsgTPCM_RTS "ESMD_02869";
BA_ "SPN" SG_ 2632777603 PGN_PktMsgTPCM_RTS 2560;
BA_ "CI_FullName" SG_ 2632777603 PGN_PktMsgTPCM_RTS2 "Parameter Group Number of the packeted message (TP.CM_RTS) 2";
BA_ "CI_ParId" SG_ 2632777603 PGN_PktMsgTPCM_RTS2 "ESMD_03860";
BA_ "SPN" SG_ 2632777603 PGN_PktMsgTPCM_RTS2 2566;
BA_ "GenSigAutoGenSnd" SG_ 2632777603 TotMsgSizeBAM 0;
BA_ "GenSigAutoGenDsp" SG_ 2632777603 TotMsgSizeBAM 0;
BA_ "CI_RepetitionComplemented" SG_ 2632777603 TotMsgSizeBAM 2;
BA_ "CI_FullName" SG_ 2632777603 TotMsgSizeBAM "_";
BA_ "CI_ParId" SG_ 2632777603 TotMsgSizeBAM "ESMD_03432";
BA_ "SPN" SG_ 2632777603 TotMsgSizeBAM 2567;
BA_ "GenSigAutoGenSnd" SG_ 2632777603 TotMsgSizeEoMA 0;
BA_ "GenSigAutoGenDsp" SG_ 2632777603 TotMsgSizeEoMA 0;
BA_ "CI_RepetitionComplemented" SG_ 2632777603 TotMsgSizeEoMA 2;
BA_ "CI_FullName" SG_ 2632777603 TotMsgSizeEoMA "_";
BA_ "CI_ParId" SG_ 2632777603 TotMsgSizeEoMA "ESMD_03433";
BA_ "SPN" SG_ 2632777603 TotMsgSizeEoMA 2564;
BA_ "GenSigAutoGenSnd" SG_ 2632777603 TotMsgSizeTPCM_RTS 0;
BA_ "GenSigAutoGenDsp" SG_ 2632777603 TotMsgSizeTPCM_RTS 0;
BA_ "CI_RepetitionComplemented" SG_ 2632777603 TotMsgSizeTPCM_RTS 2;
BA_ "CI_FullName" SG_ 2632777603 TotMsgSizeTPCM_RTS "Total Message Size (TP.CM_RTS)";
BA_ "CI_ParId" SG_ 2632777603 TotMsgSizeTPCM_RTS "ESMD_03431";
BA_ "SPN" SG_ 2632777603 TotMsgSizeTPCM_RTS 2557;
BA_ "GenSigAutoGenSnd" SG_ 2632777603 TotNumPktBAM 0;
BA_ "GenSigAutoGenDsp" SG_ 2632777603 TotNumPktBAM 0;
BA_ "CI_RepetitionComplemented" SG_ 2632777603 TotNumPktBAM 2;
BA_ "CI_FullName" SG_ 2632777603 TotNumPktBAM "_";
BA_ "CI_ParId" SG_ 2632777603 TotNumPktBAM "ESMD_03435";
BA_ "SPN" SG_ 2632777603 TotNumPktBAM 2568;
BA_ "GenSigAutoGenSnd" SG_ 2632777603 TotNumPktEoMA 0;
BA_ "GenSigAutoGenDsp" SG_ 2632777603 TotNumPktEoMA 0;
BA_ "CI_RepetitionComplemented" SG_ 2632777603 TotNumPktEoMA 2;
BA_ "CI_FullName" SG_ 2632777603 TotNumPktEoMA "_";
BA_ "CI_ParId" SG_ 2632777603 TotNumPktEoMA "ESMD_03436";
BA_ "SPN" SG_ 2632777603 TotNumPktEoMA 2565;
BA_ "GenSigAutoGenSnd" SG_ 2632777603 TotNumPktTPCM_RTS 0;
BA_ "GenSigAutoGenDsp" SG_ 2632777603 TotNumPktTPCM_RTS 0;
BA_ "CI_RepetitionComplemented" SG_ 2632777603 TotNumPktTPCM_RTS 2;
BA_ "CI_FullName" SG_ 2632777603 TotNumPktTPCM_RTS "Total Number of Packets (TP.CM_RTS)";
BA_ "CI_ParId" SG_ 2632777603 TotNumPktTPCM_RTS "ESMD_03434";
BA_ "SPN" SG_ 2632777603 TotNumPktTPCM_RTS 2558;
BA_ "GenSigAutoGenSnd" SG_ 2632777603 CByteTPCM 0;
BA_ "GenSigAutoGenDsp" SG_ 2632777603 CByteTPCM 0;
BA_ "CI_RepetitionComplemented" SG_ 2632777603 CByteTPCM 2;
BA_ "CI_FullName" SG_ 2632777603 CByteTPCM "Control Byte (TP.CM)";
BA_ "CI_ParId" SG_ 2632777603 CByteTPCM "ESMD_00941";
BA_ "SPN" SG_ 2632777603 CByteTPCM 2556;
BA_ "GenSigAutoGenSnd" SG_ 2565350016 AddrAccssDeny 0;
BA_ "GenSigAutoGenDsp" SG_ 2565350016 AddrAccssDeny 0;
BA_ "CI_FullName" SG_ 2565350016 AddrAccssDeny "Address Access Denied";
BA_ "CI_ParId" SG_ 2565350016 AddrAccssDeny "ESMD_00040";
BA_ "SPN" SG_ 2565350016 AddrAccssDeny 3292;
BA_ "GenSigAutoGenSnd" SG_ 2565350016 AddrAck 0;
BA_ "GenSigAutoGenDsp" SG_ 2565350016 AddrAck 0;
BA_ "CI_FullName" SG_ 2565350016 AddrAck "Address Acknowledged";
BA_ "CI_ParId" SG_ 2565350016 AddrAck "ESMD_00041";
BA_ "SPN" SG_ 2565350016 AddrAck 3290;
BA_ "GenSigAutoGenSnd" SG_ 2565350016 AddrBusy 0;
BA_ "GenSigAutoGenDsp" SG_ 2565350016 AddrBusy 0;
BA_ "CI_FullName" SG_ 2565350016 AddrBusy "Address Busy";
BA_ "CI_ParId" SG_ 2565350016 AddrBusy "ESMD_00043";
BA_ "SPN" SG_ 2565350016 AddrBusy 3293;
BA_ "GenSigAutoGenSnd" SG_ 2565350016 AddrNegAck 0;
BA_ "GenSigAutoGenDsp" SG_ 2565350016 AddrNegAck 0;
BA_ "CI_FullName" SG_ 2565350016 AddrNegAck "Address Negative Acknowledgement";
BA_ "CI_ParId" SG_ 2565350016 AddrNegAck "ESMD_00044";
BA_ "SPN" SG_ 2565350016 AddrNegAck 3291;
BA_ "GenSigAutoGenSnd" SG_ 2565350016 GrpFunctValAck 0;
BA_ "GenSigAutoGenDsp" SG_ 2565350016 GrpFunctValAck 0;
BA_ "CI_RepetitionComplemented" SG_ 2565350016 GrpFunctValAck 2;
BA_ "CI_FullName" SG_ 2565350016 GrpFunctValAck "Group Function Value (ACK)";
BA_ "CI_ParId" SG_ 2565350016 GrpFunctValAck "ESMD_02063";
BA_ "SPN" SG_ 2565350016 GrpFunctValAck 2542;
BA_ "SigType" SG_ 2565350016 GrpFunctValAck 1;
BA_ "CI_FullName" SG_ 2565350016 GrpFunctValNAck "Group Function Value (NACK)";
BA_ "CI_ParId" SG_ 2565350016 GrpFunctValNAck "ESMD_02063";
BA_ "SPN" SG_ 2565350016 GrpFunctValNAck 2542;
BA_ "SigType" SG_ 2565350016 GrpFunctValNAck 1;
BA_ "CI_FullName" SG_ 2565350016 GrpFunctValNAckAd "Group Function Value (Access Denied)";
BA_ "CI_ParId" SG_ 2565350016 GrpFunctValNAckAd "ESMD_02063";
BA_ "SPN" SG_ 2565350016 GrpFunctValNAckAd 2542;
BA_ "SigType" SG_ 2565350016 GrpFunctValNAckAd 1;
BA_ "CI_FullName" SG_ 2565350016 GrpFunctValNAckBusy "Group Function Value (Cannot Respond)";
BA_ "CI_ParId" SG_ 2565350016 GrpFunctValNAckBusy "ESMD_02063";
BA_ "SPN" SG_ 2565350016 GrpFunctValNAckBusy 2542;
BA_ "SigType" SG_ 2565350016 GrpFunctValNAckBusy 1;
BA_ "CI_FullName" SG_ 2565350016 PGN_Ack "Parameter Group Number (RQST2)";
BA_ "CI_ParId" SG_ 2565350016 PGN_Ack "ESMD_02835";
BA_ "SPN" SG_ 2565350016 PGN_Ack 2574;
BA_ "SigType" SG_ 2565350016 PGN_Ack 6;
BA_ "CI_FullName" SG_ 2565350016 PGN_NAck "Parameter Group Number (RQST2)";
BA_ "CI_ParId" SG_ 2565350016 PGN_NAck "ESMD_02835";
BA_ "SPN" SG_ 2565350016 PGN_NAck 2574;
BA_ "SigType" SG_ 2565350016 PGN_NAck 6;
BA_ "CI_FullName" SG_ 2565350016 PGN_NAckAd "Parameter Group Number (RQST2)";
BA_ "CI_ParId" SG_ 2565350016 PGN_NAckAd "ESMD_02835";
BA_ "SPN" SG_ 2565350016 PGN_NAckAd 2574;
BA_ "SigType" SG_ 2565350016 PGN_NAckAd 6;
BA_ "CI_FullName" SG_ 2565350016 PGN_NAckBusy "Parameter Group Number (RQST2)";
BA_ "CI_ParId" SG_ 2565350016 PGN_NAckBusy "ESMD_02835";
BA_ "SPN" SG_ 2565350016 PGN_NAckBusy 2574;
BA_ "SigType" SG_ 2565350016 PGN_NAckBusy 6;
BA_ "GenSigAutoGenSnd" SG_ 2565350016 CByteAckm 0;
BA_ "GenSigAutoGenDsp" SG_ 2565350016 CByteAckm 0;
BA_ "CI_FullName" SG_ 2565350016 CByteAckm "Control Byte (ACKM)";
BA_ "CI_ParId" SG_ 2565350016 CByteAckm "ESMD_00942";
BA_ "SPN" SG_ 2565350016 CByteAckm 2541;
BA_ "SigType" SG_ 2565350016 CByteAckm 1;
BA_ "GenSigAutoGenSnd" SG_ 2565350017 AddrAccssDeny 0;
BA_ "GenSigAutoGenDsp" SG_ 2565350017 AddrAccssDeny 0;
BA_ "CI_FullName" SG_ 2565350017 AddrAccssDeny "Address Access Denied";
BA_ "CI_ParId" SG_ 2565350017 AddrAccssDeny "ESMD_00040";
BA_ "SPN" SG_ 2565350017 AddrAccssDeny 3292;
BA_ "GenSigAutoGenSnd" SG_ 2565350017 AddrAck 0;
BA_ "GenSigAutoGenDsp" SG_ 2565350017 AddrAck 0;
BA_ "CI_FullName" SG_ 2565350017 AddrAck "Address Acknowledged";
BA_ "CI_ParId" SG_ 2565350017 AddrAck "ESMD_00041";
BA_ "SPN" SG_ 2565350017 AddrAck 3290;
BA_ "GenSigAutoGenSnd" SG_ 2565350017 AddrBusy 0;
BA_ "GenSigAutoGenDsp" SG_ 2565350017 AddrBusy 0;
BA_ "CI_FullName" SG_ 2565350017 AddrBusy "Address Busy";
BA_ "CI_ParId" SG_ 2565350017 AddrBusy "ESMD_00043";
BA_ "SPN" SG_ 2565350017 AddrBusy 3293;
BA_ "GenSigAutoGenSnd" SG_ 2565350017 AddrNegAck 0;
BA_ "GenSigAutoGenDsp" SG_ 2565350017 AddrNegAck 0;
BA_ "CI_FullName" SG_ 2565350017 AddrNegAck "Address Negative Acknowledgement";
BA_ "CI_ParId" SG_ 2565350017 AddrNegAck "ESMD_00044";
BA_ "SPN" SG_ 2565350017 AddrNegAck 3291;
BA_ "GenSigAutoGenSnd" SG_ 2565350017 GrpFunctValAck 0;
BA_ "GenSigAutoGenDsp" SG_ 2565350017 GrpFunctValAck 0;
BA_ "CI_RepetitionComplemented" SG_ 2565350017 GrpFunctValAck 2;
BA_ "CI_FullName" SG_ 2565350017 GrpFunctValAck "Group Function Value (ACK)";
BA_ "CI_ParId" SG_ 2565350017 GrpFunctValAck "ESMD_02063";
BA_ "SPN" SG_ 2565350017 GrpFunctValAck 2542;
BA_ "SigType" SG_ 2565350017 GrpFunctValAck 1;
BA_ "CI_FullName" SG_ 2565350017 GrpFunctValNAck "Group Function Value (NACK)";
BA_ "CI_ParId" SG_ 2565350017 GrpFunctValNAck "ESMD_02063";
BA_ "SPN" SG_ 2565350017 GrpFunctValNAck 2542;
BA_ "SigType" SG_ 2565350017 GrpFunctValNAck 1;
BA_ "CI_FullName" SG_ 2565350017 GrpFunctValNAckAd "Group Function Value (Access Denied)";
BA_ "CI_ParId" SG_ 2565350017 GrpFunctValNAckAd "ESMD_02063";
BA_ "SPN" SG_ 2565350017 GrpFunctValNAckAd 2542;
BA_ "SigType" SG_ 2565350017 GrpFunctValNAckAd 1;
BA_ "CI_FullName" SG_ 2565350017 GrpFunctValNAckBusy "Group Function Value (Cannot Respond)";
BA_ "CI_ParId" SG_ 2565350017 GrpFunctValNAckBusy "ESMD_02063";
BA_ "SPN" SG_ 2565350017 GrpFunctValNAckBusy 2542;
BA_ "SigType" SG_ 2565350017 GrpFunctValNAckBusy 1;
BA_ "CI_FullName" SG_ 2565350017 PGN_Ack "Parameter Group Number (RQST2)";
BA_ "CI_ParId" SG_ 2565350017 PGN_Ack "ESMD_02835";
BA_ "SPN" SG_ 2565350017 PGN_Ack 2574;
BA_ "SigType" SG_ 2565350017 PGN_Ack 6;
BA_ "CI_FullName" SG_ 2565350017 PGN_NAck "Parameter Group Number (RQST2)";
BA_ "CI_ParId" SG_ 2565350017 PGN_NAck "ESMD_02835";
BA_ "SPN" SG_ 2565350017 PGN_NAck 2574;
BA_ "SigType" SG_ 2565350017 PGN_NAck 6;
BA_ "CI_FullName" SG_ 2565350017 PGN_NAckAd "Parameter Group Number (RQST2)";
BA_ "CI_ParId" SG_ 2565350017 PGN_NAckAd "ESMD_02835";
BA_ "SPN" SG_ 2565350017 PGN_NAckAd 2574;
BA_ "SigType" SG_ 2565350017 PGN_NAckAd 6;
BA_ "CI_FullName" SG_ 2565350017 PGN_NAckBusy "Parameter Group Number (RQST2)";
BA_ "CI_ParId" SG_ 2565350017 PGN_NAckBusy "ESMD_02835";
BA_ "SPN" SG_ 2565350017 PGN_NAckBusy 2574;
BA_ "SigType" SG_ 2565350017 PGN_NAckBusy 6;
BA_ "GenSigAutoGenSnd" SG_ 2565350017 CByteAckm 0;
BA_ "GenSigAutoGenDsp" SG_ 2565350017 CByteAckm 0;
BA_ "CI_FullName" SG_ 2565350017 CByteAckm "Control Byte (ACKM)";
BA_ "CI_ParId" SG_ 2565350017 CByteAckm "ESMD_00942";
BA_ "SPN" SG_ 2565350017 CByteAckm 2541;
BA_ "SigType" SG_ 2565350017 CByteAckm 1;
BA_ "GenSigAutoGenSnd" SG_ 2565350018 AddrAccssDeny 0;
BA_ "GenSigAutoGenDsp" SG_ 2565350018 AddrAccssDeny 0;
BA_ "CI_FullName" SG_ 2565350018 AddrAccssDeny "Address Access Denied";
BA_ "CI_ParId" SG_ 2565350018 AddrAccssDeny "ESMD_00040";
BA_ "SPN" SG_ 2565350018 AddrAccssDeny 3292;
BA_ "GenSigAutoGenSnd" SG_ 2565350018 AddrAck 0;
BA_ "GenSigAutoGenDsp" SG_ 2565350018 AddrAck 0;
BA_ "CI_FullName" SG_ 2565350018 AddrAck "Address Acknowledged";
BA_ "CI_ParId" SG_ 2565350018 AddrAck "ESMD_00041";
BA_ "SPN" SG_ 2565350018 AddrAck 3290;
BA_ "GenSigAutoGenSnd" SG_ 2565350018 AddrBusy 0;
BA_ "GenSigAutoGenDsp" SG_ 2565350018 AddrBusy 0;
BA_ "CI_FullName" SG_ 2565350018 AddrBusy "Address Busy";
BA_ "CI_ParId" SG_ 2565350018 AddrBusy "ESMD_00043";
BA_ "SPN" SG_ 2565350018 AddrBusy 3293;
BA_ "GenSigAutoGenSnd" SG_ 2565350018 AddrNegAck 0;
BA_ "GenSigAutoGenDsp" SG_ 2565350018 AddrNegAck 0;
BA_ "CI_FullName" SG_ 2565350018 AddrNegAck "Address Negative Acknowledgement";
BA_ "CI_ParId" SG_ 2565350018 AddrNegAck "ESMD_00044";
BA_ "SPN" SG_ 2565350018 AddrNegAck 3291;
BA_ "GenSigAutoGenSnd" SG_ 2565350018 GrpFunctValAck 0;
BA_ "GenSigAutoGenDsp" SG_ 2565350018 GrpFunctValAck 0;
BA_ "CI_RepetitionComplemented" SG_ 2565350018 GrpFunctValAck 2;
BA_ "CI_FullName" SG_ 2565350018 GrpFunctValAck "Group Function Value (ACK)";
BA_ "CI_ParId" SG_ 2565350018 GrpFunctValAck "ESMD_02063";
BA_ "SPN" SG_ 2565350018 GrpFunctValAck 2542;
BA_ "SigType" SG_ 2565350018 GrpFunctValAck 1;
BA_ "CI_FullName" SG_ 2565350018 GrpFunctValNAck "Group Function Value (NACK)";
BA_ "CI_ParId" SG_ 2565350018 GrpFunctValNAck "ESMD_02063";
BA_ "SPN" SG_ 2565350018 GrpFunctValNAck 2542;
BA_ "SigType" SG_ 2565350018 GrpFunctValNAck 1;
BA_ "CI_FullName" SG_ 2565350018 GrpFunctValNAckAd "Group Function Value (Access Denied)";
BA_ "CI_ParId" SG_ 2565350018 GrpFunctValNAckAd "ESMD_02063";
BA_ "SPN" SG_ 2565350018 GrpFunctValNAckAd 2542;
BA_ "SigType" SG_ 2565350018 GrpFunctValNAckAd 1;
BA_ "CI_FullName" SG_ 2565350018 GrpFunctValNAckBusy "Group Function Value (Cannot Respond)";
BA_ "CI_ParId" SG_ 2565350018 GrpFunctValNAckBusy "ESMD_02063";
BA_ "SPN" SG_ 2565350018 GrpFunctValNAckBusy 2542;
BA_ "SigType" SG_ 2565350018 GrpFunctValNAckBusy 1;
BA_ "CI_FullName" SG_ 2565350018 PGN_Ack "Parameter Group Number (RQST2)";
BA_ "CI_ParId" SG_ 2565350018 PGN_Ack "ESMD_02835";
BA_ "SPN" SG_ 2565350018 PGN_Ack 2574;
BA_ "SigType" SG_ 2565350018 PGN_Ack 6;
BA_ "CI_FullName" SG_ 2565350018 PGN_NAck "Parameter Group Number (RQST2)";
BA_ "CI_ParId" SG_ 2565350018 PGN_NAck "ESMD_02835";
BA_ "SPN" SG_ 2565350018 PGN_NAck 2574;
BA_ "SigType" SG_ 2565350018 PGN_NAck 6;
BA_ "CI_FullName" SG_ 2565350018 PGN_NAckAd "Parameter Group Number (RQST2)";
BA_ "CI_ParId" SG_ 2565350018 PGN_NAckAd "ESMD_02835";
BA_ "SPN" SG_ 2565350018 PGN_NAckAd 2574;
BA_ "SigType" SG_ 2565350018 PGN_NAckAd 6;
BA_ "CI_FullName" SG_ 2565350018 PGN_NAckBusy "Parameter Group Number (RQST2)";
BA_ "CI_ParId" SG_ 2565350018 PGN_NAckBusy "ESMD_02835";
BA_ "SPN" SG_ 2565350018 PGN_NAckBusy 2574;
BA_ "SigType" SG_ 2565350018 PGN_NAckBusy 6;
BA_ "GenSigAutoGenSnd" SG_ 2565350018 CByteAckm 0;
BA_ "GenSigAutoGenDsp" SG_ 2565350018 CByteAckm 0;
BA_ "CI_FullName" SG_ 2565350018 CByteAckm "Control Byte (ACKM)";
BA_ "CI_ParId" SG_ 2565350018 CByteAckm "ESMD_00942";
BA_ "SPN" SG_ 2565350018 CByteAckm 2541;
BA_ "SigType" SG_ 2565350018 CByteAckm 1;
BA_ "GenSigAutoGenSnd" SG_ 2565350019 AddrAccssDeny 0;
BA_ "GenSigAutoGenDsp" SG_ 2565350019 AddrAccssDeny 0;
BA_ "CI_FullName" SG_ 2565350019 AddrAccssDeny "Address Access Denied";
BA_ "CI_ParId" SG_ 2565350019 AddrAccssDeny "ESMD_00040";
BA_ "SPN" SG_ 2565350019 AddrAccssDeny 3292;
BA_ "GenSigAutoGenSnd" SG_ 2565350019 AddrAck 0;
BA_ "GenSigAutoGenDsp" SG_ 2565350019 AddrAck 0;
BA_ "CI_FullName" SG_ 2565350019 AddrAck "Address Acknowledged";
BA_ "CI_ParId" SG_ 2565350019 AddrAck "ESMD_00041";
BA_ "SPN" SG_ 2565350019 AddrAck 3290;
BA_ "GenSigAutoGenSnd" SG_ 2565350019 AddrBusy 0;
BA_ "GenSigAutoGenDsp" SG_ 2565350019 AddrBusy 0;
BA_ "CI_FullName" SG_ 2565350019 AddrBusy "Address Busy";
BA_ "CI_ParId" SG_ 2565350019 AddrBusy "ESMD_00043";
BA_ "SPN" SG_ 2565350019 AddrBusy 3293;
BA_ "GenSigAutoGenSnd" SG_ 2565350019 AddrNegAck 0;
BA_ "GenSigAutoGenDsp" SG_ 2565350019 AddrNegAck 0;
BA_ "CI_FullName" SG_ 2565350019 AddrNegAck "Address Negative Acknowledgement";
BA_ "CI_ParId" SG_ 2565350019 AddrNegAck "ESMD_00044";
BA_ "SPN" SG_ 2565350019 AddrNegAck 3291;
BA_ "GenSigAutoGenSnd" SG_ 2565350019 GrpFunctValAck 0;
BA_ "GenSigAutoGenDsp" SG_ 2565350019 GrpFunctValAck 0;
BA_ "CI_RepetitionComplemented" SG_ 2565350019 GrpFunctValAck 2;
BA_ "CI_FullName" SG_ 2565350019 GrpFunctValAck "Group Function Value (ACK)";
BA_ "CI_ParId" SG_ 2565350019 GrpFunctValAck "ESMD_02063";
BA_ "SPN" SG_ 2565350019 GrpFunctValAck 2542;
BA_ "SigType" SG_ 2565350019 GrpFunctValAck 1;
BA_ "CI_FullName" SG_ 2565350019 GrpFunctValNAck "Group Function Value (NACK)";
BA_ "CI_ParId" SG_ 2565350019 GrpFunctValNAck "ESMD_02063";
BA_ "SPN" SG_ 2565350019 GrpFunctValNAck 2542;
BA_ "SigType" SG_ 2565350019 GrpFunctValNAck 1;
BA_ "CI_FullName" SG_ 2565350019 GrpFunctValNAckAd "Group Function Value (Access Denied)";
BA_ "CI_ParId" SG_ 2565350019 GrpFunctValNAckAd "ESMD_02063";
BA_ "SPN" SG_ 2565350019 GrpFunctValNAckAd 2542;
BA_ "SigType" SG_ 2565350019 GrpFunctValNAckAd 1;
BA_ "CI_FullName" SG_ 2565350019 GrpFunctValNAckBusy "Group Function Value (Cannot Respond)";
BA_ "CI_ParId" SG_ 2565350019 GrpFunctValNAckBusy "ESMD_02063";
BA_ "SPN" SG_ 2565350019 GrpFunctValNAckBusy 2542;
BA_ "SigType" SG_ 2565350019 GrpFunctValNAckBusy 1;
BA_ "CI_FullName" SG_ 2565350019 PGN_Ack "Parameter Group Number (RQST2)";
BA_ "CI_ParId" SG_ 2565350019 PGN_Ack "ESMD_02835";
BA_ "SPN" SG_ 2565350019 PGN_Ack 2574;
BA_ "SigType" SG_ 2565350019 PGN_Ack 6;
BA_ "CI_FullName" SG_ 2565350019 PGN_NAck "Parameter Group Number (RQST2)";
BA_ "CI_ParId" SG_ 2565350019 PGN_NAck "ESMD_02835";
BA_ "SPN" SG_ 2565350019 PGN_NAck 2574;
BA_ "SigType" SG_ 2565350019 PGN_NAck 6;
BA_ "CI_FullName" SG_ 2565350019 PGN_NAckAd "Parameter Group Number (RQST2)";
BA_ "CI_ParId" SG_ 2565350019 PGN_NAckAd "ESMD_02835";
BA_ "SPN" SG_ 2565350019 PGN_NAckAd 2574;
BA_ "SigType" SG_ 2565350019 PGN_NAckAd 6;
BA_ "CI_FullName" SG_ 2565350019 PGN_NAckBusy "Parameter Group Number (RQST2)";
BA_ "CI_ParId" SG_ 2565350019 PGN_NAckBusy "ESMD_02835";
BA_ "SPN" SG_ 2565350019 PGN_NAckBusy 2574;
BA_ "SigType" SG_ 2565350019 PGN_NAckBusy 6;
BA_ "GenSigAutoGenSnd" SG_ 2565350019 CByteAckm 0;
BA_ "GenSigAutoGenDsp" SG_ 2565350019 CByteAckm 0;
BA_ "CI_FullName" SG_ 2565350019 CByteAckm "Control Byte (ACKM)";
BA_ "CI_ParId" SG_ 2565350019 CByteAckm "ESMD_00942";
BA_ "SPN" SG_ 2565350019 CByteAckm 2541;
BA_ "SigType" SG_ 2565350019 CByteAckm 1;
VAL_ 2566866052 EHR_ParamByte_1 127 "EHR Parameter Status" 59 "EHR Parameter Control" ;
VAL_ 2566866052 EHR_ParamStsByte_3 244 "Check status (PTO uses)" 103 "RoundingOfTheTimeRamp" 80 "ReadChecksumOfApplicationSw" ;
VAL_ 2566866057 EHR_ParamByte_1 127 "EHR Parameter Status" 59 "EHR Parameter Control" ;
VAL_ 2566866057 EHR_ParamStsByte_3 244 "Check status (PTO uses)" 103 "RoundingOfTheTimeRamp" 80 "ReadChecksumOfApplicationSw" ;
VAL_ 2565799817 ManufctCod 195 "General Engine Products" 196 "LEMKEN GmbH & Co. KG" 197 "Mechron Power Systems" 198 "Mystic Valley Communications" 199 "Actia Corp." 200 "MGM Brakes" 201 "Disenos y Tecnologia S.A." 202 "Curtis Instruments, Inc." 203 "MILtronik GmbH" 204 "The Morey Corporation" 205 "SmarTire Systems Inc" 206 "port GmbH" 207 "Otto Engineering" 208 "Drew Technologies, Inc." 209 "Bell Equip. Co. SA (PTY) LTD" 210 "Iteris, Inc." 211 "DNA Group" 212 "Sure Power Industries, Inc." 213 "CNH Belgium N.V." 214 "MC elettronica Srl" 215 "Aetna Engineering/Fireboy-Xintex" 216 "Paneltronics Inc." 217 "RM Michaelides Software & Elektronik GmbH" 218 "Gits Manufacturing Company" 219 "Cat OEM Solutions" 220 "Beede Electrical Instrument Company, Inc." 221 "SiE" 222 "Generac Power Systems, Inc." 1850 "Teleflex" 1851 "Raymarine" 1852 "Navionics" 1853 "Japan Radio Co." 1854 "Northstar Technologies" 1855 "Furuno USA" 1856 "Trimble" 1857 "Simrad" 1858 "Litton" 1859 "Kvasar AB" 1860 "MMP" 1861 "Vector CANtech" 1862 "Sanshin" 1863 "Thomas G. Faria Co." 232 "TSD Integrated Controls" 234 "Mondial electronic GmbH" 235 "SailorMade Marine Telemetry - Tetra Technology Ltd." 236 "Norac Systems International Inc" 237 "Agtron Enterprises Inc" 238 "ZF Friedrichshafen AG" 239 "May & Scofield Ltd" 240 "Vanair Mfg" 241 "Schneider Automation SAS " 242 "Kokusandenki Co. Ltd" 243 "eRide, Inc." 244 "Techno-Matic" 245 "Capstan Ag Systems, Inc." 246 "Class 1, Inc" 247 "ePULSE" 248 "Cooper Standard Automotive Active Systems Group" 264 "Autolync" 265 "MTS Sensor Technologie GmbH" 266 "International Thermal Research Ltd" 114 "EControls, Inc." 115 "NACCO Materials Handling Group, Inc." 116 "BEELINE Technologies" 117 "HUSCO International" 118 "Intron GmbH" 119 "IntegriNautics" 120 "RDS Technology Ltd." 121 "HED (Hydro Electronic Devices, Inc.)" 122 "FG Wilson (Engineering) Limited" 123 "Basler Electric" 124 "Hydac Electronic" 125 "Nevada Automotive Test Center" 126 "Driver Tech" 127 "Holland USA" 128 "Gerhard Duecker GmbH & Co. KG" 129 "OMNEX Control Systems, Inc." 130 "Nido - Universal Machines B.V." 131 "ITT Industries" 132 "Mulag-Fahrzeugwerk" 133 "Bucher Schoerling GmbH" 134 "Iris Technology Ltd." 135 "Airmar Technology Corporation" 136 "Komatsu Ltd." 137 "Maretron" 138 "Georg Fritzmeier GmbH & Co. KG" 139 "Caterpillar Trimble Control Technologies (CTCT), LLC" 140 "Lowrance Electronics, Inc." 141 "Thales Navigation Ltd." 142 "TRW Automotive (Commercial Steering Systems)" 143 "W. Gmeiner GmbH & Co." 144 "Mercury Marine" 145 "MurCal Controls" 146 "Maxima Technologies" 147 "Nautibus Electronic GmbH" 148 "Blue Water Data, Inc." 149 "Holset" 150 "Fleetguard" 151 "Raven Industries Inc. - Flow Controls Division" 152 "elobau GmbH & Co. KG" 153 "Woodward, Industrial Controls Division" 154 "Westerbeke Corporation" 155 "Vetronix Corporation" 156 "ITT Industries - Cannon" 157 "ISSPRO Inc." 158 "Firestone Industrial Products Company" 159 "NTech Industries Inc." 160 "Nido" 161 "Offshore Systems (UK) Limited" 162 "Axiomatic Technologies" 163 "BRP Inc." 164 "DaimlerChrysler Off-Highway" 165 "CPAC Systems AB" 166 "Phoenix International" 167 "JLG Industries Inc." 168 "Xantrex" 169 "Marlin Technologies Inc." 170 "Computronics Corporation Ltd." 171 "Wachendorff Elektronik GmbH & Co. KG" 172 "Yanmar Marine USA" 173 "Ryeso, Inc." 174 "AB Volvo Penta" 175 "Veris Technologies, Inc." 176 "Moritz Aerospace" 177 "Diagnostic System Associates" 178 "Siemens VDO Automotive AG" 179 "TeeJet Technologies Denmark" 180 "Smart Power Systems" 181 "Coretronics, Inc." 182 "Vehicle Systems Engineering B.V." 183 "KDS Controls, Inc." 184 "EIA Electronics" 185 "Beede Electrical Instrument Company" 186 "Altronic, Inc." 187 "Air-Weigh" 188 "EMP Corp." 189 "QUALCOMM" 190 "Hella KGaA Hueck & Co." 191 "XRS Corporation" 192 "Floscan" 193 "Nobletec" 194 "TriMark Corporation" 378 "Glendinning Marine Products" 379 "Yamabiko Corporation" 380 "Suntech International Ltd." 382 "National Agricultural and Food Research Organization" 383 "MCL Industries" 384 "Camano Light" 385 "Johnson Outdoor Marine Electronics" 386 "JLG Automation BVBA" 387 "Orscheln Products, LLC" 388 "Innomatix, LLC" 389 "Benchmark Electronics, Minnesota Division" 390 "Partech Inc." 391 "Electronic Design for Industry, Inc" 392 "Tianyuan Technology Co Ltd." 393 "Harvest Tec, Inc" 394 "Capi 2 Nederland BV" 395 "GENTEC S.R.L." 396 "Beyond Measure" 397 "Sanyo-kiki Co Ltd." 398 "Hilite International" 399 "ISEKI & Co., Ltd." 400 "Livorsi Marine" 401 "Torqeedo GmbH" 402 "Simma Software, Inc." 403 "Trackwell ADS, Inc." 404 "Com Nav Marine Ltd" 405 "Wema System AS" 406 "Vecima Networks Inc." 407 "Comtech Mobile Datacom" 408 "Corvus Energy Ltd." 409 "Transfluid S.r.L." 410 "COBO S.p.A. Divisione 3B6" 411 "Hy-Drive Technologies Ltd." 412 "WebTech Wireless Inc." 413 "Datapross Nijbroek bv" 414 "Cattron Group International" 415 "Valid Manufacturing Ltd." 416 "Kubota Corporation" 417 "KZValve" 418 "Intellistick Inc" 419 "Fusion Electronics Ltd" 420 "Vermeer Corporation, ACS Group" 421 "Vertex Standard Co., Ltd" 422 "True Heading AB" 423 "BSM Wireless, Inc." 424 "Odyne LLC" 425 "Methode Electronics Inc, MDI" 426 "Egersund Marine Electronics AS" 427 "em-trak Marine Electronics Ltd" 428 "Mfg_428" 429 "Rota Engineering Ltd." 455 "ADZ NAGANO GmbH" 456 "General Kinetics" 457 "RUSELPROM-ElectricDrive Ltd" 458 "Control Solutions, Inc." 459 "Alltek Marine Electronics Corp" 1098 "Preh GmbH" 593 "Sensata Technologies" 460 "San Giorgio S.E.I.N." 267 "Red Lion Controls, Inc" 268 "Accurate Technologies" 269 "Saft America Inc.,  Space & Defense Division" 270 "Tennant" 271 "Cole Hersee" 312 "Lectronix, Inc." 313 "Ilmor Engineering, Inc" 314 "CSM GmbH" 315 "Icom Incorporated" 316 "ITT Flow Control" 317 "Navtronics Bvba" 318 "SAT Plan" 319 "Cadec Global" 320 "Miedema Landbouwwerktuigenfabriek B.V." 321 "Ultra Electronics, Electrics" 322 "MICHENKA s.r.o." 323 "Mobileye Vision Technologies Ltd." 324 "Snap-on Diagnostics" 325 "ASM Automation Sensorik Messtechnik GmbH" 326 "Akron Brass Company" 327 "Sonceboz SA" 272 "Gross Mechanical Laboratories, Inc" 273 "Active Research Limited" 274 "LTW Technology Co., LTD" 275 "Navico Egersund AS" 276 "Aqua-Hot Heating Systems" 277 "LHP Telematics" 278 "Takata Electronics" 279 "Geometris LP" 280 "Leica Geosystems Pty Ltd" 299 "Rauch Landmaschinen GmbH" 300 "Systron Donner Automotive" 301 "Parker Hannifin (UK) Ltd FDE group" 302 "Nissin Kogyo Co., LTD" 303 "CTS Corporation" 304 "EmpirBus AB" 305 "NovAtel Inc" 306 "Sleipner Motor AB" 307 "MBW Technologies" 308 "Cyntrx" 309 "Krauss-Maffei Wegmann GmbH & Co. KG" 310 "TECNORD srl" 311 "Patrick Power Products" 281 "Precision Governors LLC" 282 "Medallion Instrumentation Systems" 283 "CWF Hamilton & Co Ltd" 284 "Mobile Tech Chile" 285 "Sea Recovery Corp" 286 "Coelmo srl" 287 "NTech Industries, Inc" 288 "Mitsubishi FUSO Truck & Bus Corp." 289 "Watlow" 290 "Kuebler GmbH" 291 "Groeneveld Transport Efficiency BV" 292 "IKUSI - Angel Iglesias S.A." 293 "Spyder Controls Corp." 294 "Grayhill Inc." 295 "BEP Marine" 296 "micro dynamics GmbH" 297 "Zonar Systems Inc" 298 "Holley Performance" 253 "Mobile Control Systems" 254 "GE Sensing" 255 "MEAS France" 256 "Tyco Electronics AMP" 257 "Honda Motor Co., Ltd" 258 "ARAG" 259 "Jetter AG" 260 "Reichhardt GmbH" 261 "Red Dot Corporation" 262 "HydraForce, Inc" 263 "IMMI" 223 "Vaueo Retarder Co., Ltd." 224 "EMMI Network, S.L." 225 "SKF" 226 "Monaco Coach Corporation" 227 "Lykketronic A/S" 228 "ZF Marine Electronics" 229 "Garmin International Inc." 230 "Saucon Technologies" 231 "Topcon Positioning Systems, Inc." 0 "Reserved" 1 "Allied Signal Inc." 2 "Allison Transmission, GMC" 3 "Ametek, US Gauge Division" 4 "Ametek-Dixson" 5 "AMP Inc." 6 "Berifors Electronics AB" 7 "Case Corp." 8 "Caterpillar Inc." 9 "Chrysler Corp." 10 "Cummins Engine Co." 11 "Dearborn Group Inc." 12 "Deere & Company, Precision Farming" 13 "Delco Electronics" 14 "Detroit Diesel Corporation" 15 "Dickey-John Corp." 16 "Eaton Corp." 17 "Eaton Corp. Res & Dev" 18 "Eaton Corp, Transmission Division" 19 "Eaton Corp. Trucking Info Services" 20 "Eaton Ltd" 21 "Echilin Inc., Midland Brake Inc." 22 "Ford Motor Co., Electronic Concepts $ Systems" 23 "Ford Motor Co., Heavy Truck" 24 "Ford Motor Co., Vehicle Controls" 25 "Daimler Trucks North America LLC" 26 "General Motors Corp., Service Technology Group" 27 "GMC" 28 "Grote Ind. Inc." 29 "Hino Motors Ltd." 30 "Isuzu Motors Ltd." 31 "J Pollak Corp." 32 "Jacobs Vehicle Systems" 33 "John Deere" 34 "Kelsey Hayes Co." 35 "Kenworth Truck Co." 36 "Lucas Ltd." 37 "Mack Trucks Inc." 38 "Micro Processor Systems Inc." 39 "Microfirm Inc." 40 "Motorola AIEG Inc." 41 "Motorola Inc." 42 "International Truck and Engine Corp. Engine Electronics" 43 "International Truck and Engine Corp. Vehicle Electronics" 233 "Yacht Monitoring Solutions Inc." 249 "Schaltbau GmbH" 250 "Kuhn Group" 251 "German Agricultural Society" 252 "Sensor-Technik Wiedemann GmbH" 328 "Qwerty Electronik AB" 329 "Deif A/S" 330 "Kidde Aerospace and Defense" 331 "Horton, Inc." 332 "HWH Corporation" 333 "Hadley Products Corporation" 334 "Takata-Petri AG" 335 "Evo Electric Ltd" 336 "APE s.r.o." 337 "Carraro S.p.A." 338 "GRAF-SYTECO" 339 "Competence Center ISOBUS e.V." 340 "Continental AG" 341 "Boning GmbH & Co" 342 "THOMAS MAGNETE GmbH" 343 "Baumer Group" 344 "Parvus Corporation" 345 "Korean Maritime University" 346 "Control Solutions" 347 "Honeywell" 348 "Amazonen Werke H. Dreyer" 349 "Suonentiet" 350 "Noris Marine Systems GmbH & Co KG" 351 "Thrane & Thrane" 352 "SAME DEUTZ-FAHR" 353 "Hegemon Electronics, Inc." 354 "Junkkari OY" 355 "Mastervolt International B.V." 356 "Fischer Panda Generators, Inc" 357 "Hardi International A/S" 358 "Victron Energy BV" 359 "Ludwig Bergmann GmbH" 360 "HJS Emission Technology GmbH & Co KG" 361 "InMach" 362 "Alois Poettinger Maschinenfabrik GmbH" 363 "BEI Duncan" 364 "OEM Controls Inc." 365 "Digi-Star, LLC" 366 "Viewnyx Corp." 367 "Fliegl Agrartechnik" 368 "HANSENHOF_electronic" 369 "Power Torque Engineering Ltd" 370 "Rolls-Royce Marine AS" 371 "Heinzmann GmbH & Co. KG" 373 "Electronic Design Inc." 374 "Northern Lights, Inc." 381 "B&G" 372 "Delphi" 375 "Williams Controls Inc." 376 "Quake Global" 454 "NGK Spark Plug Co. Ltd" 480 "EnerDel, Inc." 481 "Chetco Digital Instruments" 482 "Tricon Electronics" 483 "Valeo" 484 "Headsight Inc." 485 "MATT automotive" 377 "ifm electronic gmbh" 44 "Nippondenso Co. Ltd." 45 "PACCAR" 46 "Noregon Systems, Inc" 47 "Phillips Semiconductor" 48 "Pollak Alphabet" 49 "RE America Inc." 50 "Robert Bosch Corp" 51 "Robert Bosch GmbH" 52 "Meritor Automotive, Inc." 53 "Continental Automotive Systems US, Inc." 54 "Meritor Wabco" 55 "Ryder System Inc." 56 "SAIC" 57 "Sauer-Danfoss Co." 58 "SPX Corporation, OTC Division" 59 "VES Inc." 60 "Volvo Trucks North America Inc." 61 "Volvo Truck Corp." 62 "Wabco" 63 "ZF Industries Inc." 64 "unused" 65 "MAN Nutzfahrzeuge AG" 66 "John Deere Construction Equipment Division" 67 "Funk Manufacturing Company" 68 "Scania" 69 "Trimble Navigation" 70 "Flex-Coil Limited" 71 "Vansco Electronics Ltd." 72 "Sisu Corporation" 73 "LeTourneau, Inc." 74 "Eaton Axle-Brake Division" 75 "Deere & Co. Agricultural Division" 76 "unused" 77 "Deere Power Systems Group" 78 "Frank W. Murphy Manufacturing, Inc." 79 "Daimler Benz AG - Engine Division (PBM)" 80 "Twin Disc, Inc." 81 "Fire Research Corp" 82 "Bobcat/Ingersoll-Rand" 83 "Bendix VORAD Technologies" 84 "New Holland UK Limited" 85 "Kohler Co." 86 "C.E. Niehoff & Company" 87 "J.C. Bamford Excavators Ltd (JCB)" 88 "Satloc Precision GPS" 89 "Kverneland Group, Electronics Division" 90 "Knorr-Bremse SfN GmbH" 91 "BSG Bodensee Steuergeraete GmbH" 92 "Ag-Chem Equipment Co., Inc." 93 "Perkins Engines Company Ltd." 94 "CNH Global N.V." 95 "Pacific Insight Electronics Corp." 96 "Mech@tronic IT GmbH" 97 "Ag Leader Technology, Inc." 98 "Mueller-Elektronik GmbH & Co." 99 "International Transmissions Ltd (ITL)" 100 "VDO Technik AG" 101 "Sensoria" 102 "AGCO GmbH & Co." 103 "CLAAS Agrosystems GmbH & Co. KG" 104 "Claas Selbstfahrende Erntemaschinen GmbH" 105 "Kiepe Elektrik GmbH & Co. KG" 106 "BAE Systems Controls, Inc." 107 "Grimme Landmaschinen GmbH & Co. KG" 108 "WTK-Elecktronik GmbH" 109 "TeeJet Technologies Denmark" 110 "EPIQ Sensor-Nite" 111 "Maschinenfabrik Bernard Krone GmbH" 112 "MECALAC" 113 "Stress-Tek, Inc." 461 "HAWE Hydraulik SE" 462 "IHI Shibaura Machinery Corporation" 463 "PROBOTIQ" 464 "Leach International Corporation" 465 "Ashcroft Inc" 466 "Veethree Electronics and Marine LLC" 467 "Lely Industries N.V." 468 "Tyco Fire Protection Products" 469 "RA Consulting GmbH" 470 "SI-TEX Marine Electronics" 471 "Sea Cross Marine AB" 472 "Tenneco Inc." 473 "Boss Industries, Inc." 474 "Persen Technologies Inc." 475 "GME" 476 "Hummingbird Marine Electronics" 477 "OilQuick AB" 478 "OceanSat BV" 479 "Vapor Bus International" 430 "Auteq Telematica S.A." 431 "Tohatsu Corporation" 432 "S&A Systems, Inc." 433 "Rowe Electronics" 434 "Stored Energy Systems" 435 "Zunhammer GmbH" 436 "Kinze Manufacturing" 437 "Digital Yacht Limited" 438 "Comar Systems Ltd" 439 "Hyundai Heavy Industries" 440 "Cummins Power Generation" 441 "PTG Reifendruckregelsysteme GmbH" 442 "Horsch Maschinen GmbH" 443 "SignalQuest, Inc." 444 "ITT Power Solutions" 445 "KAT MECHATRONIC, Electronic Product Division" 446 "CertTech, L.L.C." 447 "Great Plains Mfg." 448 "Stanadyne Corporation, Electronics Systems" 449 "Polaris Industries Inc" 450 "Dycor Technologies Ltd." 451 "Parker Hannifin Corp" 452 "WIKA Alexander Wiegand SE & Co. KG" 453 "Cooper Bussmann" 486 "Westport Innovations Inc." 487 "DSE Test Solutions A/S" 488 "The Charles Machine Works, Inc." 489 "Appareo Systems" 490 "QuikQ" 491 "Penny and Giles Ltd" 492 "Inergy Automotive Systems" 493 "Watcheye" 494 "Synerject" 495 "HOLMER Maschinenbau GmbH" 496 "W. Gessmann GmbH" 497 "SENTRON Sistemas Embarcados" 498 "Innovative Design Solutions, Inc." 499 "LCJ Capteurs" 500 "Oxbo International Corporation" 501 "Agrotronix S.A." 502 "Attwood Corporation" 503 "Naviop S.R.L." 504 "Vesper Marine" 505 "Yetter Farm Equipment" 506 "IHI STAR Machinery Corporation" 507 "Test Center ISOBUS" 508 "Transtech Innovations" 509 "MOTORTECH GmbH" 510 "Marinesoft Co. Ltd" 511 "Sulky" 512 "Inpower LLC" 513 "FarmscanAg" 514 "DISTek Integration, Inc." 515 "GINAF Trucks Nederland B.V." 516 "AVAT Automation GmbH" 517 "Noland Engineering" 518 "Transas USA Inc." 519 "Peeters Landbouwmachines b.v." 520 "Trapeze" ;
VAL_ 2565799817 Funct 57 "Steering Column Unit" 58 "Fan Drive Control" 59 "Starter" 60 "Cab Display" 61 "File Server/Printer" 62 "On-Board Diagnostic Unit" 63 "Engine Valve Controller" 64 "Endurance Braking" 65 "Gas Flow Measurement" 66 "I/O Controller" 67 "Electrical System Controller" 68 "Aftertreatment system gas measurement" 69 "Engine Emission Aftertreatement System" 30 "Management Computer" 31 "Propulsion Battery Charger" 104 "Reserved" 105 "Reserved" 106 "Reserved" 70 "Auxiliary Regeneration Device" 71 "Transfer Case Control" 72 "Coolant Valve Controller" 73 "Rollover Detection Control" 74 "Lubrication System" 75 "Supplemental Fan" 76 "Temperature Sensor" 77 "Fuel Properties Sensor" 78 "Fire Suppression System" 79 "Reserved" 80 "Reserved" 81 "Reserved" 82 "Reserved" 83 "Reserved" 84 "Reserved" 85 "Reserved" 86 "Reserved" 87 "Reserved" 88 "Reserved" 89 "Reserved" 90 "Reserved" 91 "Reserved" 92 "Reserved" 93 "Reserved" 94 "Reserved" 95 "Reserved" 96 "Reserved" 97 "Reserved" 98 "Reserved" 99 "Reserved" 100 "Reserved" 0 "Engine" 1 "Auxiliary Power Unit (APU)" 2 "Electric Propulsion Control" 3 "Transmission" 4 "Battery Pack Monitor" 5 "Shift Control/Console" 6 "Power TakeOff - (Main or Rear)" 7 "Axle - Steering" 8 "Axle - Drive" 9 "Brakes - System Controller" 10 "Brakes - Steer Axle" 11 "Brakes - Drive Axle" 12 "Retarder - Engine" 13 "Retarder - Driveline" 14 "Cruise Control" 15 "Fuel System" 16 "Steering Controller" 17 "Suspension - Steer Axle" 18 "Suspension - Drive Axle" 19 "Instrument Cluster" 20 "Trip Recorder" 21 "Cab Climate Control" 22 "Aerodynamic Control" 23 "Vehicle Navigation" 24 "Vehicle Security" 107 "Reserved" 108 "Reserved" 109 "Reserved" 110 "Reserved" 111 "Reserved" 112 "Reserved" 113 "Reserved" 114 "Reserved" 115 "Reserved" 116 "Reserved" 117 "Reserved" 118 "Reserved" 119 "Reserved" 120 "Reserved" 121 "Reserved" 122 "Reserved" 123 "Reserved" 124 "Reserved" 125 "Reserved" 126 "Reserved" 127 "Reserved" 25 "Network Interconnect ECU" 26 "Body Controller" 27 "Power TakeOff (Secondary or Front)" 28 "Off Vehicle Gateway" 29 "Virtual Terminal (in cab)" 43 "Transmission Display" 44 "Exhaust Emission Control" 45 "Vehicle Dynamic Stability Control" 46 "Oil Sensor Unit" 47 "Information System Controller" 48 "Ramp Control" 49 "Clutch/Converter Control" 50 "Auxiliary Heater" 51 "Forward-Looking Collision Warning System" 52 "Chassis Controller" 53 "Alternator/Charging System" 54 "Communications Unit, Cellular" 55 "Communications Unit, Satellite" 56 "Communications Unit, Radio" 32 "Headway Controller" 33 "System Monitor" 34 "Hydraulic Pump Controller" 35 "Suspension - System Controller" 36 "Pneumatic - System Controller" 37 "Cab Controller" 38 "Tire Pressure Control" 39 "Ignition Control Module" 40 "Seat Control" 41 "Lighting - Operator Controls" 42 "Water Pump Control" 101 "Reserved" 102 "Reserved" 103 "Reserved" ;
VAL_ 2565799817 IndstryGrp 7 "NotAvailable" 5 "Reserved" 4 "Marine" 3 "Construction" 2 "AgriculturalAndForestry" 1 "OnHighway" 0 "Global" ;
VAL_ 2565799817 ArbAddrCap 0 "No" 1 "Yes" ;
VAL_ 2565799812 Funct 57 "Steering Column Unit" 58 "Fan Drive Control" 59 "Starter" 60 "Cab Display" 61 "File Server/Printer" 62 "On-Board Diagnostic Unit" 63 "Engine Valve Controller" 64 "Endurance Braking" 65 "Gas Flow Measurement" 66 "I/O Controller" 67 "Electrical System Controller" 68 "Aftertreatment system gas measurement" 69 "Engine Emission Aftertreatement System" 30 "Management Computer" 31 "Propulsion Battery Charger" 104 "Reserved" 105 "Reserved" 106 "Reserved" 70 "Auxiliary Regeneration Device" 71 "Transfer Case Control" 72 "Coolant Valve Controller" 73 "Rollover Detection Control" 74 "Lubrication System" 75 "Supplemental Fan" 76 "Temperature Sensor" 77 "Fuel Properties Sensor" 78 "Fire Suppression System" 79 "Reserved" 80 "Reserved" 81 "Reserved" 82 "Reserved" 83 "Reserved" 84 "Reserved" 85 "Reserved" 86 "Reserved" 87 "Reserved" 88 "Reserved" 89 "Reserved" 90 "Reserved" 91 "Reserved" 92 "Reserved" 93 "Reserved" 94 "Reserved" 95 "Reserved" 96 "Reserved" 97 "Reserved" 98 "Reserved" 99 "Reserved" 100 "Reserved" 0 "Engine" 1 "Auxiliary Power Unit (APU)" 2 "Electric Propulsion Control" 3 "Transmission" 4 "Battery Pack Monitor" 5 "Shift Control/Console" 6 "Power TakeOff - (Main or Rear)" 7 "Axle - Steering" 8 "Axle - Drive" 9 "Brakes - System Controller" 10 "Brakes - Steer Axle" 11 "Brakes - Drive Axle" 12 "Retarder - Engine" 13 "Retarder - Driveline" 14 "Cruise Control" 15 "Fuel System" 16 "Steering Controller" 17 "Suspension - Steer Axle" 18 "Suspension - Drive Axle" 19 "Instrument Cluster" 20 "Trip Recorder" 21 "Cab Climate Control" 22 "Aerodynamic Control" 23 "Vehicle Navigation" 24 "Vehicle Security" 107 "Reserved" 108 "Reserved" 109 "Reserved" 110 "Reserved" 111 "Reserved" 112 "Reserved" 113 "Reserved" 114 "Reserved" 115 "Reserved" 116 "Reserved" 117 "Reserved" 118 "Reserved" 119 "Reserved" 120 "Reserved" 121 "Reserved" 122 "Reserved" 123 "Reserved" 124 "Reserved" 125 "Reserved" 126 "Reserved" 127 "Reserved" 25 "Network Interconnect ECU" 26 "Body Controller" 27 "Power TakeOff (Secondary or Front)" 28 "Off Vehicle Gateway" 29 "Virtual Terminal (in cab)" 43 "Transmission Display" 44 "Exhaust Emission Control" 45 "Vehicle Dynamic Stability Control" 46 "Oil Sensor Unit" 47 "Information System Controller" 48 "Ramp Control" 49 "Clutch/Converter Control" 50 "Auxiliary Heater" 51 "Forward-Looking Collision Warning System" 52 "Chassis Controller" 53 "Alternator/Charging System" 54 "Communications Unit, Cellular" 55 "Communications Unit, Satellite" 56 "Communications Unit, Radio" 32 "Headway Controller" 33 "System Monitor" 34 "Hydraulic Pump Controller" 35 "Suspension - System Controller" 36 "Pneumatic - System Controller" 37 "Cab Controller" 38 "Tire Pressure Control" 39 "Ignition Control Module" 40 "Seat Control" 41 "Lighting - Operator Controls" 42 "Water Pump Control" 101 "Reserved" 102 "Reserved" 103 "Reserved" ;
VAL_ 2565799812 ManufctCod 195 "General Engine Products" 196 "LEMKEN GmbH & Co. KG" 197 "Mechron Power Systems" 198 "Mystic Valley Communications" 199 "Actia Corp." 200 "MGM Brakes" 201 "Disenos y Tecnologia S.A." 202 "Curtis Instruments, Inc." 203 "MILtronik GmbH" 204 "The Morey Corporation" 205 "SmarTire Systems Inc" 206 "port GmbH" 207 "Otto Engineering" 208 "Drew Technologies, Inc." 209 "Bell Equip. Co. SA (PTY) LTD" 210 "Iteris, Inc." 211 "DNA Group" 212 "Sure Power Industries, Inc." 213 "CNH Belgium N.V." 214 "MC elettronica Srl" 215 "Aetna Engineering/Fireboy-Xintex" 216 "Paneltronics Inc." 217 "RM Michaelides Software & Elektronik GmbH" 218 "Gits Manufacturing Company" 219 "Cat OEM Solutions" 220 "Beede Electrical Instrument Company, Inc." 221 "SiE" 222 "Generac Power Systems, Inc." 1850 "Teleflex" 1851 "Raymarine" 1852 "Navionics" 1853 "Japan Radio Co." 1854 "Northstar Technologies" 1855 "Furuno USA" 1856 "Trimble" 1857 "Simrad" 1858 "Litton" 1859 "Kvasar AB" 1860 "MMP" 1861 "Vector CANtech" 1862 "Sanshin" 1863 "Thomas G. Faria Co." 232 "TSD Integrated Controls" 234 "Mondial electronic GmbH" 235 "SailorMade Marine Telemetry - Tetra Technology Ltd." 236 "Norac Systems International Inc" 237 "Agtron Enterprises Inc" 238 "ZF Friedrichshafen AG" 239 "May & Scofield Ltd" 240 "Vanair Mfg" 241 "Schneider Automation SAS " 242 "Kokusandenki Co. Ltd" 243 "eRide, Inc." 244 "Techno-Matic" 245 "Capstan Ag Systems, Inc." 246 "Class 1, Inc" 247 "ePULSE" 248 "Cooper Standard Automotive Active Systems Group" 264 "Autolync" 265 "MTS Sensor Technologie GmbH" 266 "International Thermal Research Ltd" 114 "EControls, Inc." 115 "NACCO Materials Handling Group, Inc." 116 "BEELINE Technologies" 117 "HUSCO International" 118 "Intron GmbH" 119 "IntegriNautics" 120 "RDS Technology Ltd." 121 "HED (Hydro Electronic Devices, Inc.)" 122 "FG Wilson (Engineering) Limited" 123 "Basler Electric" 124 "Hydac Electronic" 125 "Nevada Automotive Test Center" 126 "Driver Tech" 127 "Holland USA" 128 "Gerhard Duecker GmbH & Co. KG" 129 "OMNEX Control Systems, Inc." 130 "Nido - Universal Machines B.V." 131 "ITT Industries" 132 "Mulag-Fahrzeugwerk" 133 "Bucher Schoerling GmbH" 134 "Iris Technology Ltd." 135 "Airmar Technology Corporation" 136 "Komatsu Ltd." 137 "Maretron" 138 "Georg Fritzmeier GmbH & Co. KG" 139 "Caterpillar Trimble Control Technologies (CTCT), LLC" 140 "Lowrance Electronics, Inc." 141 "Thales Navigation Ltd." 142 "TRW Automotive (Commercial Steering Systems)" 143 "W. Gmeiner GmbH & Co." 144 "Mercury Marine" 145 "MurCal Controls" 146 "Maxima Technologies" 147 "Nautibus Electronic GmbH" 148 "Blue Water Data, Inc." 149 "Holset" 150 "Fleetguard" 151 "Raven Industries Inc. - Flow Controls Division" 152 "elobau GmbH & Co. KG" 153 "Woodward, Industrial Controls Division" 154 "Westerbeke Corporation" 155 "Vetronix Corporation" 156 "ITT Industries - Cannon" 157 "ISSPRO Inc." 158 "Firestone Industrial Products Company" 159 "NTech Industries Inc." 160 "Nido" 161 "Offshore Systems (UK) Limited" 162 "Axiomatic Technologies" 163 "BRP Inc." 164 "DaimlerChrysler Off-Highway" 165 "CPAC Systems AB" 166 "Phoenix International" 167 "JLG Industries Inc." 168 "Xantrex" 169 "Marlin Technologies Inc." 170 "Computronics Corporation Ltd." 171 "Wachendorff Elektronik GmbH & Co. KG" 172 "Yanmar Marine USA" 173 "Ryeso, Inc." 174 "AB Volvo Penta" 175 "Veris Technologies, Inc." 176 "Moritz Aerospace" 177 "Diagnostic System Associates" 178 "Siemens VDO Automotive AG" 179 "TeeJet Technologies Denmark" 180 "Smart Power Systems" 181 "Coretronics, Inc." 182 "Vehicle Systems Engineering B.V." 183 "KDS Controls, Inc." 184 "EIA Electronics" 185 "Beede Electrical Instrument Company" 186 "Altronic, Inc." 187 "Air-Weigh" 188 "EMP Corp." 189 "QUALCOMM" 190 "Hella KGaA Hueck & Co." 191 "XRS Corporation" 192 "Floscan" 193 "Nobletec" 194 "TriMark Corporation" 378 "Glendinning Marine Products" 379 "Yamabiko Corporation" 380 "Suntech International Ltd." 382 "National Agricultural and Food Research Organization" 383 "MCL Industries" 384 "Camano Light" 385 "Johnson Outdoor Marine Electronics" 386 "JLG Automation BVBA" 387 "Orscheln Products, LLC" 388 "Innomatix, LLC" 389 "Benchmark Electronics, Minnesota Division" 390 "Partech Inc." 391 "Electronic Design for Industry, Inc" 392 "Tianyuan Technology Co Ltd." 393 "Harvest Tec, Inc" 394 "Capi 2 Nederland BV" 395 "GENTEC S.R.L." 396 "Beyond Measure" 397 "Sanyo-kiki Co Ltd." 398 "Hilite International" 399 "ISEKI & Co., Ltd." 400 "Livorsi Marine" 401 "Torqeedo GmbH" 402 "Simma Software, Inc." 403 "Trackwell ADS, Inc." 404 "Com Nav Marine Ltd" 405 "Wema System AS" 406 "Vecima Networks Inc." 407 "Comtech Mobile Datacom" 408 "Corvus Energy Ltd." 409 "Transfluid S.r.L." 410 "COBO S.p.A. Divisione 3B6" 411 "Hy-Drive Technologies Ltd." 412 "WebTech Wireless Inc." 413 "Datapross Nijbroek bv" 414 "Cattron Group International" 415 "Valid Manufacturing Ltd." 416 "Kubota Corporation" 417 "KZValve" 418 "Intellistick Inc" 419 "Fusion Electronics Ltd" 420 "Vermeer Corporation, ACS Group" 421 "Vertex Standard Co., Ltd" 422 "True Heading AB" 423 "BSM Wireless, Inc." 424 "Odyne LLC" 425 "Methode Electronics Inc, MDI" 426 "Egersund Marine Electronics AS" 427 "em-trak Marine Electronics Ltd" 428 "Mfg_428" 429 "Rota Engineering Ltd." 455 "ADZ NAGANO GmbH" 456 "General Kinetics" 457 "RUSELPROM-ElectricDrive Ltd" 458 "Control Solutions, Inc." 459 "Alltek Marine Electronics Corp" 1098 "Preh GmbH" 593 "Sensata Technologies" 460 "San Giorgio S.E.I.N." 267 "Red Lion Controls, Inc" 268 "Accurate Technologies" 269 "Saft America Inc.,  Space & Defense Division" 270 "Tennant" 271 "Cole Hersee" 312 "Lectronix, Inc." 313 "Ilmor Engineering, Inc" 314 "CSM GmbH" 315 "Icom Incorporated" 316 "ITT Flow Control" 317 "Navtronics Bvba" 318 "SAT Plan" 319 "Cadec Global" 320 "Miedema Landbouwwerktuigenfabriek B.V." 321 "Ultra Electronics, Electrics" 322 "MICHENKA s.r.o." 323 "Mobileye Vision Technologies Ltd." 324 "Snap-on Diagnostics" 325 "ASM Automation Sensorik Messtechnik GmbH" 326 "Akron Brass Company" 327 "Sonceboz SA" 272 "Gross Mechanical Laboratories, Inc" 273 "Active Research Limited" 274 "LTW Technology Co., LTD" 275 "Navico Egersund AS" 276 "Aqua-Hot Heating Systems" 277 "LHP Telematics" 278 "Takata Electronics" 279 "Geometris LP" 280 "Leica Geosystems Pty Ltd" 299 "Rauch Landmaschinen GmbH" 300 "Systron Donner Automotive" 301 "Parker Hannifin (UK) Ltd FDE group" 302 "Nissin Kogyo Co., LTD" 303 "CTS Corporation" 304 "EmpirBus AB" 305 "NovAtel Inc" 306 "Sleipner Motor AB" 307 "MBW Technologies" 308 "Cyntrx" 309 "Krauss-Maffei Wegmann GmbH & Co. KG" 310 "TECNORD srl" 311 "Patrick Power Products" 281 "Precision Governors LLC" 282 "Medallion Instrumentation Systems" 283 "CWF Hamilton & Co Ltd" 284 "Mobile Tech Chile" 285 "Sea Recovery Corp" 286 "Coelmo srl" 287 "NTech Industries, Inc" 288 "Mitsubishi FUSO Truck & Bus Corp." 289 "Watlow" 290 "Kuebler GmbH" 291 "Groeneveld Transport Efficiency BV" 292 "IKUSI - Angel Iglesias S.A." 293 "Spyder Controls Corp." 294 "Grayhill Inc." 295 "BEP Marine" 296 "micro dynamics GmbH" 297 "Zonar Systems Inc" 298 "Holley Performance" 253 "Mobile Control Systems" 254 "GE Sensing" 255 "MEAS France" 256 "Tyco Electronics AMP" 257 "Honda Motor Co., Ltd" 258 "ARAG" 259 "Jetter AG" 260 "Reichhardt GmbH" 261 "Red Dot Corporation" 262 "HydraForce, Inc" 263 "IMMI" 223 "Vaueo Retarder Co., Ltd." 224 "EMMI Network, S.L." 225 "SKF" 226 "Monaco Coach Corporation" 227 "Lykketronic A/S" 228 "ZF Marine Electronics" 229 "Garmin International Inc." 230 "Saucon Technologies" 231 "Topcon Positioning Systems, Inc." 0 "Reserved" 1 "Allied Signal Inc." 2 "Allison Transmission, GMC" 3 "Ametek, US Gauge Division" 4 "Ametek-Dixson" 5 "AMP Inc." 6 "Berifors Electronics AB" 7 "Case Corp." 8 "Caterpillar Inc." 9 "Chrysler Corp." 10 "Cummins Engine Co." 11 "Dearborn Group Inc." 12 "Deere & Company, Precision Farming" 13 "Delco Electronics" 14 "Detroit Diesel Corporation" 15 "Dickey-John Corp." 16 "Eaton Corp." 17 "Eaton Corp. Res & Dev" 18 "Eaton Corp, Transmission Division" 19 "Eaton Corp. Trucking Info Services" 20 "Eaton Ltd" 21 "Echilin Inc., Midland Brake Inc." 22 "Ford Motor Co., Electronic Concepts $ Systems" 23 "Ford Motor Co., Heavy Truck" 24 "Ford Motor Co., Vehicle Controls" 25 "Daimler Trucks North America LLC" 26 "General Motors Corp., Service Technology Group" 27 "GMC" 28 "Grote Ind. Inc." 29 "Hino Motors Ltd." 30 "Isuzu Motors Ltd." 31 "J Pollak Corp." 32 "Jacobs Vehicle Systems" 33 "John Deere" 34 "Kelsey Hayes Co." 35 "Kenworth Truck Co." 36 "Lucas Ltd." 37 "Mack Trucks Inc." 38 "Micro Processor Systems Inc." 39 "Microfirm Inc." 40 "Motorola AIEG Inc." 41 "Motorola Inc." 42 "International Truck and Engine Corp. Engine Electronics" 43 "International Truck and Engine Corp. Vehicle Electronics" 233 "Yacht Monitoring Solutions Inc." 249 "Schaltbau GmbH" 250 "Kuhn Group" 251 "German Agricultural Society" 252 "Sensor-Technik Wiedemann GmbH" 328 "Qwerty Electronik AB" 329 "Deif A/S" 330 "Kidde Aerospace and Defense" 331 "Horton, Inc." 332 "HWH Corporation" 333 "Hadley Products Corporation" 334 "Takata-Petri AG" 335 "Evo Electric Ltd" 336 "APE s.r.o." 337 "Carraro S.p.A." 338 "GRAF-SYTECO" 339 "Competence Center ISOBUS e.V." 340 "Continental AG" 341 "Boning GmbH & Co" 342 "THOMAS MAGNETE GmbH" 343 "Baumer Group" 344 "Parvus Corporation" 345 "Korean Maritime University" 346 "Control Solutions" 347 "Honeywell" 348 "Amazonen Werke H. Dreyer" 349 "Suonentiet" 350 "Noris Marine Systems GmbH & Co KG" 351 "Thrane & Thrane" 352 "SAME DEUTZ-FAHR" 353 "Hegemon Electronics, Inc." 354 "Junkkari OY" 355 "Mastervolt International B.V." 356 "Fischer Panda Generators, Inc" 357 "Hardi International A/S" 358 "Victron Energy BV" 359 "Ludwig Bergmann GmbH" 360 "HJS Emission Technology GmbH & Co KG" 361 "InMach" 362 "Alois Poettinger Maschinenfabrik GmbH" 363 "BEI Duncan" 364 "OEM Controls Inc." 365 "Digi-Star, LLC" 366 "Viewnyx Corp." 367 "Fliegl Agrartechnik" 368 "HANSENHOF_electronic" 369 "Power Torque Engineering Ltd" 370 "Rolls-Royce Marine AS" 371 "Heinzmann GmbH & Co. KG" 373 "Electronic Design Inc." 374 "Northern Lights, Inc." 381 "B&G" 372 "Delphi" 375 "Williams Controls Inc." 376 "Quake Global" 454 "NGK Spark Plug Co. Ltd" 480 "EnerDel, Inc." 481 "Chetco Digital Instruments" 482 "Tricon Electronics" 483 "Valeo" 484 "Headsight Inc." 485 "MATT automotive" 377 "ifm electronic gmbh" 44 "Nippondenso Co. Ltd." 45 "PACCAR" 46 "Noregon Systems, Inc" 47 "Phillips Semiconductor" 48 "Pollak Alphabet" 49 "RE America Inc." 50 "Robert Bosch Corp" 51 "Robert Bosch GmbH" 52 "Meritor Automotive, Inc." 53 "Continental Automotive Systems US, Inc." 54 "Meritor Wabco" 55 "Ryder System Inc." 56 "SAIC" 57 "Sauer-Danfoss Co." 58 "SPX Corporation, OTC Division" 59 "VES Inc." 60 "Volvo Trucks North America Inc." 61 "Volvo Truck Corp." 62 "Wabco" 63 "ZF Industries Inc." 64 "unused" 65 "MAN Nutzfahrzeuge AG" 66 "John Deere Construction Equipment Division" 67 "Funk Manufacturing Company" 68 "Scania" 69 "Trimble Navigation" 70 "Flex-Coil Limited" 71 "Vansco Electronics Ltd." 72 "Sisu Corporation" 73 "LeTourneau, Inc." 74 "Eaton Axle-Brake Division" 75 "Deere & Co. Agricultural Division" 76 "unused" 77 "Deere Power Systems Group" 78 "Frank W. Murphy Manufacturing, Inc." 79 "Daimler Benz AG - Engine Division (PBM)" 80 "Twin Disc, Inc." 81 "Fire Research Corp" 82 "Bobcat/Ingersoll-Rand" 83 "Bendix VORAD Technologies" 84 "New Holland UK Limited" 85 "Kohler Co." 86 "C.E. Niehoff & Company" 87 "J.C. Bamford Excavators Ltd (JCB)" 88 "Satloc Precision GPS" 89 "Kverneland Group, Electronics Division" 90 "Knorr-Bremse SfN GmbH" 91 "BSG Bodensee Steuergeraete GmbH" 92 "Ag-Chem Equipment Co., Inc." 93 "Perkins Engines Company Ltd." 94 "CNH Global N.V." 95 "Pacific Insight Electronics Corp." 96 "Mech@tronic IT GmbH" 97 "Ag Leader Technology, Inc." 98 "Mueller-Elektronik GmbH & Co." 99 "International Transmissions Ltd (ITL)" 100 "VDO Technik AG" 101 "Sensoria" 102 "AGCO GmbH & Co." 103 "CLAAS Agrosystems GmbH & Co. KG" 104 "Claas Selbstfahrende Erntemaschinen GmbH" 105 "Kiepe Elektrik GmbH & Co. KG" 106 "BAE Systems Controls, Inc." 107 "Grimme Landmaschinen GmbH & Co. KG" 108 "WTK-Elecktronik GmbH" 109 "TeeJet Technologies Denmark" 110 "EPIQ Sensor-Nite" 111 "Maschinenfabrik Bernard Krone GmbH" 112 "MECALAC" 113 "Stress-Tek, Inc." 461 "HAWE Hydraulik SE" 462 "IHI Shibaura Machinery Corporation" 463 "PROBOTIQ" 464 "Leach International Corporation" 465 "Ashcroft Inc" 466 "Veethree Electronics and Marine LLC" 467 "Lely Industries N.V." 468 "Tyco Fire Protection Products" 469 "RA Consulting GmbH" 470 "SI-TEX Marine Electronics" 471 "Sea Cross Marine AB" 472 "Tenneco Inc." 473 "Boss Industries, Inc." 474 "Persen Technologies Inc." 475 "GME" 476 "Hummingbird Marine Electronics" 477 "OilQuick AB" 478 "OceanSat BV" 479 "Vapor Bus International" 430 "Auteq Telematica S.A." 431 "Tohatsu Corporation" 432 "S&A Systems, Inc." 433 "Rowe Electronics" 434 "Stored Energy Systems" 435 "Zunhammer GmbH" 436 "Kinze Manufacturing" 437 "Digital Yacht Limited" 438 "Comar Systems Ltd" 439 "Hyundai Heavy Industries" 440 "Cummins Power Generation" 441 "PTG Reifendruckregelsysteme GmbH" 442 "Horsch Maschinen GmbH" 443 "SignalQuest, Inc." 444 "ITT Power Solutions" 445 "KAT MECHATRONIC, Electronic Product Division" 446 "CertTech, L.L.C." 447 "Great Plains Mfg." 448 "Stanadyne Corporation, Electronics Systems" 449 "Polaris Industries Inc" 450 "Dycor Technologies Ltd." 451 "Parker Hannifin Corp" 452 "WIKA Alexander Wiegand SE & Co. KG" 453 "Cooper Bussmann" 486 "Westport Innovations Inc." 487 "DSE Test Solutions A/S" 488 "The Charles Machine Works, Inc." 489 "Appareo Systems" 490 "QuikQ" 491 "Penny and Giles Ltd" 492 "Inergy Automotive Systems" 493 "Watcheye" 494 "Synerject" 495 "HOLMER Maschinenbau GmbH" 496 "W. Gessmann GmbH" 497 "SENTRON Sistemas Embarcados" 498 "Innovative Design Solutions, Inc." 499 "LCJ Capteurs" 500 "Oxbo International Corporation" 501 "Agrotronix S.A." 502 "Attwood Corporation" 503 "Naviop S.R.L." 504 "Vesper Marine" 505 "Yetter Farm Equipment" 506 "IHI STAR Machinery Corporation" 507 "Test Center ISOBUS" 508 "Transtech Innovations" 509 "MOTORTECH GmbH" 510 "Marinesoft Co. Ltd" 511 "Sulky" 512 "Inpower LLC" 513 "FarmscanAg" 514 "DISTek Integration, Inc." 515 "GINAF Trucks Nederland B.V." 516 "AVAT Automation GmbH" 517 "Noland Engineering" 518 "Transas USA Inc." 519 "Peeters Landbouwmachines b.v." 520 "Trapeze" ;
VAL_ 2565799812 IndstryGrp 7 "NotAvailable" 5 "Reserved" 4 "Marine" 3 "Construction" 2 "AgriculturalAndForestry" 1 "OnHighway" 0 "Global" ;
VAL_ 2565799812 ArbAddrCap 0 "No" 1 "Yes" ;
VAL_ 2565799811 ManufctCod 195 "General Engine Products" 196 "LEMKEN GmbH & Co. KG" 197 "Mechron Power Systems" 198 "Mystic Valley Communications" 199 "Actia Corp." 200 "MGM Brakes" 201 "Disenos y Tecnologia S.A." 202 "Curtis Instruments, Inc." 203 "MILtronik GmbH" 204 "The Morey Corporation" 205 "SmarTire Systems Inc" 206 "port GmbH" 207 "Otto Engineering" 208 "Drew Technologies, Inc." 209 "Bell Equip. Co. SA (PTY) LTD" 210 "Iteris, Inc." 211 "DNA Group" 212 "Sure Power Industries, Inc." 213 "CNH Belgium N.V." 214 "MC elettronica Srl" 215 "Aetna Engineering/Fireboy-Xintex" 216 "Paneltronics Inc." 217 "RM Michaelides Software & Elektronik GmbH" 218 "Gits Manufacturing Company" 219 "Cat OEM Solutions" 220 "Beede Electrical Instrument Company, Inc." 221 "SiE" 222 "Generac Power Systems, Inc." 1850 "Teleflex" 1851 "Raymarine" 1852 "Navionics" 1853 "Japan Radio Co." 1854 "Northstar Technologies" 1855 "Furuno USA" 1856 "Trimble" 1857 "Simrad" 1858 "Litton" 1859 "Kvasar AB" 1860 "MMP" 1861 "Vector CANtech" 1862 "Sanshin" 1863 "Thomas G. Faria Co." 232 "TSD Integrated Controls" 234 "Mondial electronic GmbH" 235 "SailorMade Marine Telemetry - Tetra Technology Ltd." 236 "Norac Systems International Inc" 237 "Agtron Enterprises Inc" 238 "ZF Friedrichshafen AG" 239 "May & Scofield Ltd" 240 "Vanair Mfg" 241 "Schneider Automation SAS " 242 "Kokusandenki Co. Ltd" 243 "eRide, Inc." 244 "Techno-Matic" 245 "Capstan Ag Systems, Inc." 246 "Class 1, Inc" 247 "ePULSE" 248 "Cooper Standard Automotive Active Systems Group" 264 "Autolync" 265 "MTS Sensor Technologie GmbH" 266 "International Thermal Research Ltd" 114 "EControls, Inc." 115 "NACCO Materials Handling Group, Inc." 116 "BEELINE Technologies" 117 "HUSCO International" 118 "Intron GmbH" 119 "IntegriNautics" 120 "RDS Technology Ltd." 121 "HED (Hydro Electronic Devices, Inc.)" 122 "FG Wilson (Engineering) Limited" 123 "Basler Electric" 124 "Hydac Electronic" 125 "Nevada Automotive Test Center" 126 "Driver Tech" 127 "Holland USA" 128 "Gerhard Duecker GmbH & Co. KG" 129 "OMNEX Control Systems, Inc." 130 "Nido - Universal Machines B.V." 131 "ITT Industries" 132 "Mulag-Fahrzeugwerk" 133 "Bucher Schoerling GmbH" 134 "Iris Technology Ltd." 135 "Airmar Technology Corporation" 136 "Komatsu Ltd." 137 "Maretron" 138 "Georg Fritzmeier GmbH & Co. KG" 139 "Caterpillar Trimble Control Technologies (CTCT), LLC" 140 "Lowrance Electronics, Inc." 141 "Thales Navigation Ltd." 142 "TRW Automotive (Commercial Steering Systems)" 143 "W. Gmeiner GmbH & Co." 144 "Mercury Marine" 145 "MurCal Controls" 146 "Maxima Technologies" 147 "Nautibus Electronic GmbH" 148 "Blue Water Data, Inc." 149 "Holset" 150 "Fleetguard" 151 "Raven Industries Inc. - Flow Controls Division" 152 "elobau GmbH & Co. KG" 153 "Woodward, Industrial Controls Division" 154 "Westerbeke Corporation" 155 "Vetronix Corporation" 156 "ITT Industries - Cannon" 157 "ISSPRO Inc." 158 "Firestone Industrial Products Company" 159 "NTech Industries Inc." 160 "Nido" 161 "Offshore Systems (UK) Limited" 162 "Axiomatic Technologies" 163 "BRP Inc." 164 "DaimlerChrysler Off-Highway" 165 "CPAC Systems AB" 166 "Phoenix International" 167 "JLG Industries Inc." 168 "Xantrex" 169 "Marlin Technologies Inc." 170 "Computronics Corporation Ltd." 171 "Wachendorff Elektronik GmbH & Co. KG" 172 "Yanmar Marine USA" 173 "Ryeso, Inc." 174 "AB Volvo Penta" 175 "Veris Technologies, Inc." 176 "Moritz Aerospace" 177 "Diagnostic System Associates" 178 "Siemens VDO Automotive AG" 179 "TeeJet Technologies Denmark" 180 "Smart Power Systems" 181 "Coretronics, Inc." 182 "Vehicle Systems Engineering B.V." 183 "KDS Controls, Inc." 184 "EIA Electronics" 185 "Beede Electrical Instrument Company" 186 "Altronic, Inc." 187 "Air-Weigh" 188 "EMP Corp." 189 "QUALCOMM" 190 "Hella KGaA Hueck & Co." 191 "XRS Corporation" 192 "Floscan" 193 "Nobletec" 194 "TriMark Corporation" 378 "Glendinning Marine Products" 379 "Yamabiko Corporation" 380 "Suntech International Ltd." 382 "National Agricultural and Food Research Organization" 383 "MCL Industries" 384 "Camano Light" 385 "Johnson Outdoor Marine Electronics" 386 "JLG Automation BVBA" 387 "Orscheln Products, LLC" 388 "Innomatix, LLC" 389 "Benchmark Electronics, Minnesota Division" 390 "Partech Inc." 391 "Electronic Design for Industry, Inc" 392 "Tianyuan Technology Co Ltd." 393 "Harvest Tec, Inc" 394 "Capi 2 Nederland BV" 395 "GENTEC S.R.L." 396 "Beyond Measure" 397 "Sanyo-kiki Co Ltd." 398 "Hilite International" 399 "ISEKI & Co., Ltd." 400 "Livorsi Marine" 401 "Torqeedo GmbH" 402 "Simma Software, Inc." 403 "Trackwell ADS, Inc." 404 "Com Nav Marine Ltd" 405 "Wema System AS" 406 "Vecima Networks Inc." 407 "Comtech Mobile Datacom" 408 "Corvus Energy Ltd." 409 "Transfluid S.r.L." 410 "COBO S.p.A. Divisione 3B6" 411 "Hy-Drive Technologies Ltd." 412 "WebTech Wireless Inc." 413 "Datapross Nijbroek bv" 414 "Cattron Group International" 415 "Valid Manufacturing Ltd." 416 "Kubota Corporation" 417 "KZValve" 418 "Intellistick Inc" 419 "Fusion Electronics Ltd" 420 "Vermeer Corporation, ACS Group" 421 "Vertex Standard Co., Ltd" 422 "True Heading AB" 423 "BSM Wireless, Inc." 424 "Odyne LLC" 425 "Methode Electronics Inc, MDI" 426 "Egersund Marine Electronics AS" 427 "em-trak Marine Electronics Ltd" 428 "Mfg_428" 429 "Rota Engineering Ltd." 455 "ADZ NAGANO GmbH" 456 "General Kinetics" 457 "RUSELPROM-ElectricDrive Ltd" 458 "Control Solutions, Inc." 459 "Alltek Marine Electronics Corp" 1098 "Preh GmbH" 593 "Sensata Technologies" 460 "San Giorgio S.E.I.N." 267 "Red Lion Controls, Inc" 268 "Accurate Technologies" 269 "Saft America Inc.,  Space & Defense Division" 270 "Tennant" 271 "Cole Hersee" 312 "Lectronix, Inc." 313 "Ilmor Engineering, Inc" 314 "CSM GmbH" 315 "Icom Incorporated" 316 "ITT Flow Control" 317 "Navtronics Bvba" 318 "SAT Plan" 319 "Cadec Global" 320 "Miedema Landbouwwerktuigenfabriek B.V." 321 "Ultra Electronics, Electrics" 322 "MICHENKA s.r.o." 323 "Mobileye Vision Technologies Ltd." 324 "Snap-on Diagnostics" 325 "ASM Automation Sensorik Messtechnik GmbH" 326 "Akron Brass Company" 327 "Sonceboz SA" 272 "Gross Mechanical Laboratories, Inc" 273 "Active Research Limited" 274 "LTW Technology Co., LTD" 275 "Navico Egersund AS" 276 "Aqua-Hot Heating Systems" 277 "LHP Telematics" 278 "Takata Electronics" 279 "Geometris LP" 280 "Leica Geosystems Pty Ltd" 299 "Rauch Landmaschinen GmbH" 300 "Systron Donner Automotive" 301 "Parker Hannifin (UK) Ltd FDE group" 302 "Nissin Kogyo Co., LTD" 303 "CTS Corporation" 304 "EmpirBus AB" 305 "NovAtel Inc" 306 "Sleipner Motor AB" 307 "MBW Technologies" 308 "Cyntrx" 309 "Krauss-Maffei Wegmann GmbH & Co. KG" 310 "TECNORD srl" 311 "Patrick Power Products" 281 "Precision Governors LLC" 282 "Medallion Instrumentation Systems" 283 "CWF Hamilton & Co Ltd" 284 "Mobile Tech Chile" 285 "Sea Recovery Corp" 286 "Coelmo srl" 287 "NTech Industries, Inc" 288 "Mitsubishi FUSO Truck & Bus Corp." 289 "Watlow" 290 "Kuebler GmbH" 291 "Groeneveld Transport Efficiency BV" 292 "IKUSI - Angel Iglesias S.A." 293 "Spyder Controls Corp." 294 "Grayhill Inc." 295 "BEP Marine" 296 "micro dynamics GmbH" 297 "Zonar Systems Inc" 298 "Holley Performance" 253 "Mobile Control Systems" 254 "GE Sensing" 255 "MEAS France" 256 "Tyco Electronics AMP" 257 "Honda Motor Co., Ltd" 258 "ARAG" 259 "Jetter AG" 260 "Reichhardt GmbH" 261 "Red Dot Corporation" 262 "HydraForce, Inc" 263 "IMMI" 223 "Vaueo Retarder Co., Ltd." 224 "EMMI Network, S.L." 225 "SKF" 226 "Monaco Coach Corporation" 227 "Lykketronic A/S" 228 "ZF Marine Electronics" 229 "Garmin International Inc." 230 "Saucon Technologies" 231 "Topcon Positioning Systems, Inc." 0 "Reserved" 1 "Allied Signal Inc." 2 "Allison Transmission, GMC" 3 "Ametek, US Gauge Division" 4 "Ametek-Dixson" 5 "AMP Inc." 6 "Berifors Electronics AB" 7 "Case Corp." 8 "Caterpillar Inc." 9 "Chrysler Corp." 10 "Cummins Engine Co." 11 "Dearborn Group Inc." 12 "Deere & Company, Precision Farming" 13 "Delco Electronics" 14 "Detroit Diesel Corporation" 15 "Dickey-John Corp." 16 "Eaton Corp." 17 "Eaton Corp. Res & Dev" 18 "Eaton Corp, Transmission Division" 19 "Eaton Corp. Trucking Info Services" 20 "Eaton Ltd" 21 "Echilin Inc., Midland Brake Inc." 22 "Ford Motor Co., Electronic Concepts $ Systems" 23 "Ford Motor Co., Heavy Truck" 24 "Ford Motor Co., Vehicle Controls" 25 "Daimler Trucks North America LLC" 26 "General Motors Corp., Service Technology Group" 27 "GMC" 28 "Grote Ind. Inc." 29 "Hino Motors Ltd." 30 "Isuzu Motors Ltd." 31 "J Pollak Corp." 32 "Jacobs Vehicle Systems" 33 "John Deere" 34 "Kelsey Hayes Co." 35 "Kenworth Truck Co." 36 "Lucas Ltd." 37 "Mack Trucks Inc." 38 "Micro Processor Systems Inc." 39 "Microfirm Inc." 40 "Motorola AIEG Inc." 41 "Motorola Inc." 42 "International Truck and Engine Corp. Engine Electronics" 43 "International Truck and Engine Corp. Vehicle Electronics" 233 "Yacht Monitoring Solutions Inc." 249 "Schaltbau GmbH" 250 "Kuhn Group" 251 "German Agricultural Society" 252 "Sensor-Technik Wiedemann GmbH" 328 "Qwerty Electronik AB" 329 "Deif A/S" 330 "Kidde Aerospace and Defense" 331 "Horton, Inc." 332 "HWH Corporation" 333 "Hadley Products Corporation" 334 "Takata-Petri AG" 335 "Evo Electric Ltd" 336 "APE s.r.o." 337 "Carraro S.p.A." 338 "GRAF-SYTECO" 339 "Competence Center ISOBUS e.V." 340 "Continental AG" 341 "Boning GmbH & Co" 342 "THOMAS MAGNETE GmbH" 343 "Baumer Group" 344 "Parvus Corporation" 345 "Korean Maritime University" 346 "Control Solutions" 347 "Honeywell" 348 "Amazonen Werke H. Dreyer" 349 "Suonentiet" 350 "Noris Marine Systems GmbH & Co KG" 351 "Thrane & Thrane" 352 "SAME DEUTZ-FAHR" 353 "Hegemon Electronics, Inc." 354 "Junkkari OY" 355 "Mastervolt International B.V." 356 "Fischer Panda Generators, Inc" 357 "Hardi International A/S" 358 "Victron Energy BV" 359 "Ludwig Bergmann GmbH" 360 "HJS Emission Technology GmbH & Co KG" 361 "InMach" 362 "Alois Poettinger Maschinenfabrik GmbH" 363 "BEI Duncan" 364 "OEM Controls Inc." 365 "Digi-Star, LLC" 366 "Viewnyx Corp." 367 "Fliegl Agrartechnik" 368 "HANSENHOF_electronic" 369 "Power Torque Engineering Ltd" 370 "Rolls-Royce Marine AS" 371 "Heinzmann GmbH & Co. KG" 373 "Electronic Design Inc." 374 "Northern Lights, Inc." 381 "B&G" 372 "Delphi" 375 "Williams Controls Inc." 376 "Quake Global" 454 "NGK Spark Plug Co. Ltd" 480 "EnerDel, Inc." 481 "Chetco Digital Instruments" 482 "Tricon Electronics" 483 "Valeo" 484 "Headsight Inc." 485 "MATT automotive" 377 "ifm electronic gmbh" 44 "Nippondenso Co. Ltd." 45 "PACCAR" 46 "Noregon Systems, Inc" 47 "Phillips Semiconductor" 48 "Pollak Alphabet" 49 "RE America Inc." 50 "Robert Bosch Corp" 51 "Robert Bosch GmbH" 52 "Meritor Automotive, Inc." 53 "Continental Automotive Systems US, Inc." 54 "Meritor Wabco" 55 "Ryder System Inc." 56 "SAIC" 57 "Sauer-Danfoss Co." 58 "SPX Corporation, OTC Division" 59 "VES Inc." 60 "Volvo Trucks North America Inc." 61 "Volvo Truck Corp." 62 "Wabco" 63 "ZF Industries Inc." 64 "unused" 65 "MAN Nutzfahrzeuge AG" 66 "John Deere Construction Equipment Division" 67 "Funk Manufacturing Company" 68 "Scania" 69 "Trimble Navigation" 70 "Flex-Coil Limited" 71 "Vansco Electronics Ltd." 72 "Sisu Corporation" 73 "LeTourneau, Inc." 74 "Eaton Axle-Brake Division" 75 "Deere & Co. Agricultural Division" 76 "unused" 77 "Deere Power Systems Group" 78 "Frank W. Murphy Manufacturing, Inc." 79 "Daimler Benz AG - Engine Division (PBM)" 80 "Twin Disc, Inc." 81 "Fire Research Corp" 82 "Bobcat/Ingersoll-Rand" 83 "Bendix VORAD Technologies" 84 "New Holland UK Limited" 85 "Kohler Co." 86 "C.E. Niehoff & Company" 87 "J.C. Bamford Excavators Ltd (JCB)" 88 "Satloc Precision GPS" 89 "Kverneland Group, Electronics Division" 90 "Knorr-Bremse SfN GmbH" 91 "BSG Bodensee Steuergeraete GmbH" 92 "Ag-Chem Equipment Co., Inc." 93 "Perkins Engines Company Ltd." 94 "CNH Global N.V." 95 "Pacific Insight Electronics Corp." 96 "Mech@tronic IT GmbH" 97 "Ag Leader Technology, Inc." 98 "Mueller-Elektronik GmbH & Co." 99 "International Transmissions Ltd (ITL)" 100 "VDO Technik AG" 101 "Sensoria" 102 "AGCO GmbH & Co." 103 "CLAAS Agrosystems GmbH & Co. KG" 104 "Claas Selbstfahrende Erntemaschinen GmbH" 105 "Kiepe Elektrik GmbH & Co. KG" 106 "BAE Systems Controls, Inc." 107 "Grimme Landmaschinen GmbH & Co. KG" 108 "WTK-Elecktronik GmbH" 109 "TeeJet Technologies Denmark" 110 "EPIQ Sensor-Nite" 111 "Maschinenfabrik Bernard Krone GmbH" 112 "MECALAC" 113 "Stress-Tek, Inc." 461 "HAWE Hydraulik SE" 462 "IHI Shibaura Machinery Corporation" 463 "PROBOTIQ" 464 "Leach International Corporation" 465 "Ashcroft Inc" 466 "Veethree Electronics and Marine LLC" 467 "Lely Industries N.V." 468 "Tyco Fire Protection Products" 469 "RA Consulting GmbH" 470 "SI-TEX Marine Electronics" 471 "Sea Cross Marine AB" 472 "Tenneco Inc." 473 "Boss Industries, Inc." 474 "Persen Technologies Inc." 475 "GME" 476 "Hummingbird Marine Electronics" 477 "OilQuick AB" 478 "OceanSat BV" 479 "Vapor Bus International" 430 "Auteq Telematica S.A." 431 "Tohatsu Corporation" 432 "S&A Systems, Inc." 433 "Rowe Electronics" 434 "Stored Energy Systems" 435 "Zunhammer GmbH" 436 "Kinze Manufacturing" 437 "Digital Yacht Limited" 438 "Comar Systems Ltd" 439 "Hyundai Heavy Industries" 440 "Cummins Power Generation" 441 "PTG Reifendruckregelsysteme GmbH" 442 "Horsch Maschinen GmbH" 443 "SignalQuest, Inc." 444 "ITT Power Solutions" 445 "KAT MECHATRONIC, Electronic Product Division" 446 "CertTech, L.L.C." 447 "Great Plains Mfg." 448 "Stanadyne Corporation, Electronics Systems" 449 "Polaris Industries Inc" 450 "Dycor Technologies Ltd." 451 "Parker Hannifin Corp" 452 "WIKA Alexander Wiegand SE & Co. KG" 453 "Cooper Bussmann" 486 "Westport Innovations Inc." 487 "DSE Test Solutions A/S" 488 "The Charles Machine Works, Inc." 489 "Appareo Systems" 490 "QuikQ" 491 "Penny and Giles Ltd" 492 "Inergy Automotive Systems" 493 "Watcheye" 494 "Synerject" 495 "HOLMER Maschinenbau GmbH" 496 "W. Gessmann GmbH" 497 "SENTRON Sistemas Embarcados" 498 "Innovative Design Solutions, Inc." 499 "LCJ Capteurs" 500 "Oxbo International Corporation" 501 "Agrotronix S.A." 502 "Attwood Corporation" 503 "Naviop S.R.L." 504 "Vesper Marine" 505 "Yetter Farm Equipment" 506 "IHI STAR Machinery Corporation" 507 "Test Center ISOBUS" 508 "Transtech Innovations" 509 "MOTORTECH GmbH" 510 "Marinesoft Co. Ltd" 511 "Sulky" 512 "Inpower LLC" 513 "FarmscanAg" 514 "DISTek Integration, Inc." 515 "GINAF Trucks Nederland B.V." 516 "AVAT Automation GmbH" 517 "Noland Engineering" 518 "Transas USA Inc." 519 "Peeters Landbouwmachines b.v." 520 "Trapeze" ;
VAL_ 2565799811 Funct 57 "Steering Column Unit" 58 "Fan Drive Control" 59 "Starter" 60 "Cab Display" 61 "File Server/Printer" 62 "On-Board Diagnostic Unit" 63 "Engine Valve Controller" 64 "Endurance Braking" 65 "Gas Flow Measurement" 66 "I/O Controller" 67 "Electrical System Controller" 68 "Aftertreatment system gas measurement" 69 "Engine Emission Aftertreatement System" 30 "Management Computer" 31 "Propulsion Battery Charger" 104 "Reserved" 105 "Reserved" 106 "Reserved" 70 "Auxiliary Regeneration Device" 71 "Transfer Case Control" 72 "Coolant Valve Controller" 73 "Rollover Detection Control" 74 "Lubrication System" 75 "Supplemental Fan" 76 "Temperature Sensor" 77 "Fuel Properties Sensor" 78 "Fire Suppression System" 79 "Reserved" 80 "Reserved" 81 "Reserved" 82 "Reserved" 83 "Reserved" 84 "Reserved" 85 "Reserved" 86 "Reserved" 87 "Reserved" 88 "Reserved" 89 "Reserved" 90 "Reserved" 91 "Reserved" 92 "Reserved" 93 "Reserved" 94 "Reserved" 95 "Reserved" 96 "Reserved" 97 "Reserved" 98 "Reserved" 99 "Reserved" 100 "Reserved" 0 "Engine" 1 "Auxiliary Power Unit (APU)" 2 "Electric Propulsion Control" 3 "Transmission" 4 "Battery Pack Monitor" 5 "Shift Control/Console" 6 "Power TakeOff - (Main or Rear)" 7 "Axle - Steering" 8 "Axle - Drive" 9 "Brakes - System Controller" 10 "Brakes - Steer Axle" 11 "Brakes - Drive Axle" 12 "Retarder - Engine" 13 "Retarder - Driveline" 14 "Cruise Control" 15 "Fuel System" 16 "Steering Controller" 17 "Suspension - Steer Axle" 18 "Suspension - Drive Axle" 19 "Instrument Cluster" 20 "Trip Recorder" 21 "Cab Climate Control" 22 "Aerodynamic Control" 23 "Vehicle Navigation" 24 "Vehicle Security" 107 "Reserved" 108 "Reserved" 109 "Reserved" 110 "Reserved" 111 "Reserved" 112 "Reserved" 113 "Reserved" 114 "Reserved" 115 "Reserved" 116 "Reserved" 117 "Reserved" 118 "Reserved" 119 "Reserved" 120 "Reserved" 121 "Reserved" 122 "Reserved" 123 "Reserved" 124 "Reserved" 125 "Reserved" 126 "Reserved" 127 "Reserved" 25 "Network Interconnect ECU" 26 "Body Controller" 27 "Power TakeOff (Secondary or Front)" 28 "Off Vehicle Gateway" 29 "Virtual Terminal (in cab)" 43 "Transmission Display" 44 "Exhaust Emission Control" 45 "Vehicle Dynamic Stability Control" 46 "Oil Sensor Unit" 47 "Information System Controller" 48 "Ramp Control" 49 "Clutch/Converter Control" 50 "Auxiliary Heater" 51 "Forward-Looking Collision Warning System" 52 "Chassis Controller" 53 "Alternator/Charging System" 54 "Communications Unit, Cellular" 55 "Communications Unit, Satellite" 56 "Communications Unit, Radio" 32 "Headway Controller" 33 "System Monitor" 34 "Hydraulic Pump Controller" 35 "Suspension - System Controller" 36 "Pneumatic - System Controller" 37 "Cab Controller" 38 "Tire Pressure Control" 39 "Ignition Control Module" 40 "Seat Control" 41 "Lighting - Operator Controls" 42 "Water Pump Control" 101 "Reserved" 102 "Reserved" 103 "Reserved" ;
VAL_ 2565799811 IndstryGrp 7 "NotAvailable" 5 "Reserved" 4 "Marine" 3 "Construction" 2 "AgriculturalAndForestry" 1 "OnHighway" 0 "Global" ;
VAL_ 2565799811 ArbAddrCap 0 "No" 1 "Yes" ;
VAL_ 2566854786 FailSvng 3 "Do Not Care" 2 "Error Indication" 1 "Float" 0 "Neutral" ;
VAL_ 2566854786 OpMode 15 "Do Not Care" 14 "Error Indication" 3 "Float/Open Centre" 2 "Retract" 1 "Extend" 0 "Blocked/Neutral" ;
VAL_ 2566854787 FailSvng 3 "Do Not Care" 2 "Error Indication" 1 "Float" 0 "Neutral" ;
VAL_ 2566854787 OpMode 15 "Do Not Care" 14 "Error Indication" 3 "Float/Open Centre" 2 "Retract" 1 "Extend" 0 "Blocked/Neutral" ;
VAL_ 2566865536 EHR_Err 0 "Normal Operation" 1 "Fault State" 2 "Error" 3 "Not Available" ;
VAL_ 2566865536 EHR_ErrCod 69 "InternalComponentFailureSevere" 68 "InternalComponentFailureCritical" 61 "Open center position not reached" 59 "Invalid command message" 58 "Command message timeout" 54 "Address claim conflict" 48 "Spool not in neutral at power on" 47 "Open center position not reached" 46 "Spool stuck out of neutral" 44 "Actuator temp above upper limit" 5 "Supply voltage below limit" 4 "Supply voltage above limit" 0 "Initialization failure" 131 "Checksum failure" 23 "No neutral command at power on" 20 "Valve spool not calibrated" 130 "Spool not in neutral at power on" 129 "Spool not responding to commands" 67 "InternalComponentFailureWarning" 66 "D:No neutral cmd, T:intrnl fail" 65 "Supply voltage above limit" 50 "Supply voltage above limit" 49 "Low volts, D: Position error" 38 "Manual operation" 37 "Open center position not reached" 36 "Spool deflection excessive" 35 "Spool deflection too short" 34 "Supply voltage above limit" 33 "D:Init failure, B:Low volt input" 19 "Implausible CAN control message" 17 "No CAN control message received" 22 "EEPROM failure" ;
VAL_ 2566865536 EHR_EvTemp 255 "Error" ;
VAL_ 2566865536 EHR_InitDiag 0 "Normal Operation" 1 "Initialisation State" 2 "Error" 3 "Not Available" ;
VAL_ 2566865537 EHR_Err 0 "Normal Operation" 1 "Fault State" 2 "Error" 3 "Not Available" ;
VAL_ 2566865537 EHR_ErrCod 69 "InternalComponentFailureSevere" 68 "InternalComponentFailureCritical" 61 "Open center position not reached" 59 "Invalid command message" 58 "Command message timeout" 54 "Address claim conflict" 48 "Spool not in neutral at power on" 47 "Open center position not reached" 46 "Spool stuck out of neutral" 44 "Actuator temp above upper limit" 5 "Supply voltage below limit" 4 "Supply voltage above limit" 0 "Initialization failure" 131 "Checksum failure" 23 "No neutral command at power on" 20 "Valve spool not calibrated" 130 "Spool not in neutral at power on" 129 "Spool not responding to commands" 67 "InternalComponentFailureWarning" 66 "D:No neutral cmd, T:intrnl fail" 65 "Supply voltage above limit" 50 "Supply voltage above limit" 49 "Low volts, D: Position error" 38 "Manual operation" 37 "Open center position not reached" 36 "Spool deflection excessive" 35 "Spool deflection too short" 34 "Supply voltage above limit" 33 "D:Init failure, B:Low volt input" 19 "Implausible CAN control message" 17 "No CAN control message received" 22 "EEPROM failure" ;
VAL_ 2566865537 EHR_EvTemp 255 "Error" ;
VAL_ 2566865537 EHR_InitDiag 0 "Normal Operation" 1 "Initialisation State" 2 "Error" 3 "Not Available" ;
VAL_ 2566865538 EHR_Err 0 "Normal Operation" 1 "Fault State" 2 "Error" 3 "Not Available" ;
VAL_ 2566865538 EHR_ErrCod 69 "InternalComponentFailureSevere" 68 "InternalComponentFailureCritical" 61 "Open center position not reached" 59 "Invalid command message" 58 "Command message timeout" 54 "Address claim conflict" 48 "Spool not in neutral at power on" 47 "Open center position not reached" 46 "Spool stuck out of neutral" 44 "Actuator temp above upper limit" 5 "Supply voltage below limit" 4 "Supply voltage above limit" 0 "Initialization failure" 131 "Checksum failure" 23 "No neutral command at power on" 20 "Valve spool not calibrated" 130 "Spool not in neutral at power on" 129 "Spool not responding to commands" 67 "InternalComponentFailureWarning" 66 "D:No neutral cmd, T:intrnl fail" 65 "Supply voltage above limit" 50 "Supply voltage above limit" 49 "Low volts, D: Position error" 38 "Manual operation" 37 "Open center position not reached" 36 "Spool deflection excessive" 35 "Spool deflection too short" 34 "Supply voltage above limit" 33 "D:Init failure, B:Low volt input" 19 "Implausible CAN control message" 17 "No CAN control message received" 22 "EEPROM failure" ;
VAL_ 2566865538 EHR_EvTemp 255 "Error" ;
VAL_ 2566865538 EHR_InitDiag 0 "Normal Operation" 1 "Initialisation State" 2 "Error" 3 "Not Available" ;
VAL_ 2566865539 EHR_Err 0 "Normal Operation" 1 "Fault State" 2 "Error" 3 "Not Available" ;
VAL_ 2566865539 EHR_ErrCod 69 "InternalComponentFailureSevere" 68 "InternalComponentFailureCritical" 61 "Open center position not reached" 59 "Invalid command message" 58 "Command message timeout" 54 "Address claim conflict" 48 "Spool not in neutral at power on" 47 "Open center position not reached" 46 "Spool stuck out of neutral" 44 "Actuator temp above upper limit" 5 "Supply voltage below limit" 4 "Supply voltage above limit" 0 "Initialization failure" 131 "Checksum failure" 23 "No neutral command at power on" 20 "Valve spool not calibrated" 130 "Spool not in neutral at power on" 129 "Spool not responding to commands" 67 "InternalComponentFailureWarning" 66 "D:No neutral cmd, T:intrnl fail" 65 "Supply voltage above limit" 50 "Supply voltage above limit" 49 "Low volts, D: Position error" 38 "Manual operation" 37 "Open center position not reached" 36 "Spool deflection excessive" 35 "Spool deflection too short" 34 "Supply voltage above limit" 33 "D:Init failure, B:Low volt input" 19 "Implausible CAN control message" 17 "No CAN control message received" 22 "EEPROM failure" ;
VAL_ 2566865539 EHR_EvTemp 255 "Error" ;
VAL_ 2566865539 EHR_InitDiag 0 "Normal Operation" 1 "Initialisation State" 2 "Error" 3 "Not Available" ;
VAL_ 2566834816 AmbrWarnLmp 2 "flashing" 0 "Lamp off" 1 "Lamp on" 3 "Not available" ;
VAL_ 2566834816 FlashAmbrWarnLmpAWL 0 "Slow Flash" 1 "Fast Flash" 2 "Reserved" 3 "Unavailable / Do Not Flash" ;
VAL_ 2566834816 FlashMIL 0 "Slow Flash" 1 "Fast Flash" 2 "Reserved" 3 "Unavailable / Do Not Flash" ;
VAL_ 2566834816 FlashProtLmp 0 "Slow Flash" 1 "Fast Flash" 2 "Reserved" 3 "Unavailable / Do Not Flash" ;
VAL_ 2566834816 FlashRedStopLmpRSL 0 "Slow Flash" 1 "Fast Flash" 2 "Reserved" 3 "Unavailable / Do Not Flash" ;
VAL_ 2566834816 MIL 0 "Lamp off" 1 "Lamp on" 2 "Reserved" 3 "Not available" ;
VAL_ 2566834816 ProtLmp 0 "Lamp off" 1 "Lamp on" 2 "Reserved" 3 "Not available" ;
VAL_ 2566834816 RedStopLmp 0 "Lamp off" 1 "Lamp on" 3 "Not available" ;
VAL_ 2566834817 AmbrWarnLmp 2 "flashing" 0 "Lamp off" 1 "Lamp on" 3 "Not available" ;
VAL_ 2566834817 FlashAmbrWarnLmpAWL 0 "Slow Flash" 1 "Fast Flash" 2 "Reserved" 3 "Unavailable / Do Not Flash" ;
VAL_ 2566834817 FlashMIL 0 "Slow Flash" 1 "Fast Flash" 2 "Reserved" 3 "Unavailable / Do Not Flash" ;
VAL_ 2566834817 FlashProtLmp 0 "Slow Flash" 1 "Fast Flash" 2 "Reserved" 3 "Unavailable / Do Not Flash" ;
VAL_ 2566834817 FlashRedStopLmpRSL 0 "Slow Flash" 1 "Fast Flash" 2 "Reserved" 3 "Unavailable / Do Not Flash" ;
VAL_ 2566834817 MIL 0 "Lamp off" 1 "Lamp on" 2 "Reserved" 3 "Not available" ;
VAL_ 2566834817 ProtLmp 0 "Lamp off" 1 "Lamp on" 2 "Reserved" 3 "Not available" ;
VAL_ 2566834817 RedStopLmp 0 "Lamp off" 1 "Lamp on" 3 "Not available" ;
VAL_ 2566834818 RedStopLmp 0 "Lamp off" 1 "Lamp on" 3 "Not available" ;
VAL_ 2566834818 AmbrWarnLmp 2 "flashing" 0 "Lamp off" 1 "Lamp on" 3 "Not available" ;
VAL_ 2566834818 FlashAmbrWarnLmpAWL 0 "Slow Flash" 1 "Fast Flash" 2 "Reserved" 3 "Unavailable / Do Not Flash" ;
VAL_ 2566834818 FlashMIL 0 "Slow Flash" 1 "Fast Flash" 2 "Reserved" 3 "Unavailable / Do Not Flash" ;
VAL_ 2566834818 FlashProtLmp 0 "Slow Flash" 1 "Fast Flash" 2 "Reserved" 3 "Unavailable / Do Not Flash" ;
VAL_ 2566834818 FlashRedStopLmpRSL 0 "Slow Flash" 1 "Fast Flash" 2 "Reserved" 3 "Unavailable / Do Not Flash" ;
VAL_ 2566834818 MIL 0 "Lamp off" 1 "Lamp on" 2 "Reserved" 3 "Not available" ;
VAL_ 2566834818 ProtLmp 0 "Lamp off" 1 "Lamp on" 2 "Reserved" 3 "Not available" ;
VAL_ 2566834819 AmbrWarnLmp 2 "flashing" 0 "Lamp off" 1 "Lamp on" 3 "Not available" ;
VAL_ 2566834819 FlashAmbrWarnLmpAWL 0 "Slow Flash" 1 "Fast Flash" 2 "Reserved" 3 "Unavailable / Do Not Flash" ;
VAL_ 2566834819 FlashMIL 0 "Slow Flash" 1 "Fast Flash" 2 "Reserved" 3 "Unavailable / Do Not Flash" ;
VAL_ 2566834819 FlashProtLmp 0 "Slow Flash" 1 "Fast Flash" 2 "Reserved" 3 "Unavailable / Do Not Flash" ;
VAL_ 2566834819 FlashRedStopLmpRSL 0 "Slow Flash" 1 "Fast Flash" 2 "Reserved" 3 "Unavailable / Do Not Flash" ;
VAL_ 2566834819 MIL 0 "Lamp off" 1 "Lamp on" 2 "Reserved" 3 "Not available" ;
VAL_ 2566834819 ProtLmp 0 "Lamp off" 1 "Lamp on" 2 "Reserved" 3 "Not available" ;
VAL_ 2566834819 RedStopLmp 0 "Lamp off" 1 "Lamp on" 3 "Not available" ;
VAL_ 2632712064 SN_TPDT 255 "NoSequenceAvailable" ;
VAL_ 2632712065 SN_TPDT 255 "NoSequenceAvailable" ;
VAL_ 2632712067 SN_TPDT 255 "NoSequenceAvailable" ;
VAL_ 2632712066 SN_TPDT 255 "NoSequenceAvailable" ;
VAL_ 2632777600 ConnAbrtReason 1 "AlreadyInConnManagedSession" 2 "NoFreeSystemResources" 3 "Timeout_CloseSession" 4 "UnexpectedDataTransferPacket" 5 "BadSequenceNumber" 6 "DuplicateSequenceNumber" 7 "AnyOtherError" ;
VAL_ 2632777600 PGN_PktMsgTPCM_BAM 255 "NotAvailable" ;
VAL_ 2632777600 PGN_PktMsgTPCM_ConnAbort 255 "NotAvailable" ;
VAL_ 2632777600 PGN_PktMsgTPCM_CTS 255 "NotAvailable" ;
VAL_ 2632777600 PGN_PktMsgTPCM_RTS 255 "NotAvailable" ;
VAL_ 2632777600 PGN_PktMsgTPCM_RTS2 255 "NotAvailable" ;
VAL_ 2632777600 CByteTPCM 16 "RTS" 17 "CTS" 19 "EoMA" 32 "BAM" 255 "Abort" ;
VAL_ 2632777601 ConnAbrtReason 1 "AlreadyInConnManagedSession" 2 "NoFreeSystemResources" 3 "Timeout_CloseSession" 4 "UnexpectedDataTransferPacket" 5 "BadSequenceNumber" 6 "DuplicateSequenceNumber" 7 "AnyOtherError" ;
VAL_ 2632777601 PGN_PktMsgTPCM_BAM 255 "NotAvailable" ;
VAL_ 2632777601 PGN_PktMsgTPCM_ConnAbort 255 "NotAvailable" ;
VAL_ 2632777601 PGN_PktMsgTPCM_CTS 255 "NotAvailable" ;
VAL_ 2632777601 PGN_PktMsgTPCM_RTS 255 "NotAvailable" ;
VAL_ 2632777601 PGN_PktMsgTPCM_RTS2 255 "NotAvailable" ;
VAL_ 2632777601 CByteTPCM 16 "RTS" 17 "CTS" 19 "EoMA" 32 "BAM" 255 "Abort" ;
VAL_ 2632777602 ConnAbrtReason 1 "AlreadyInConnManagedSession" 2 "NoFreeSystemResources" 3 "Timeout_CloseSession" 4 "UnexpectedDataTransferPacket" 5 "BadSequenceNumber" 6 "DuplicateSequenceNumber" 7 "AnyOtherError" ;
VAL_ 2632777602 PGN_PktMsgTPCM_BAM 255 "NotAvailable" ;
VAL_ 2632777602 PGN_PktMsgTPCM_ConnAbort 255 "NotAvailable" ;
VAL_ 2632777602 PGN_PktMsgTPCM_CTS 255 "NotAvailable" ;
VAL_ 2632777602 PGN_PktMsgTPCM_RTS 255 "NotAvailable" ;
VAL_ 2632777602 PGN_PktMsgTPCM_RTS2 255 "NotAvailable" ;
VAL_ 2632777602 CByteTPCM 16 "RTS" 17 "CTS" 19 "EoMA" 32 "BAM" 255 "Abort" ;
VAL_ 2632777603 ConnAbrtReason 1 "AlreadyInConnManagedSession" 2 "NoFreeSystemResources" 3 "Timeout_CloseSession" 4 "UnexpectedDataTransferPacket" 5 "BadSequenceNumber" 6 "DuplicateSequenceNumber" 7 "AnyOtherError" ;
VAL_ 2632777603 PGN_PktMsgTPCM_BAM 255 "NotAvailable" ;
VAL_ 2632777603 PGN_PktMsgTPCM_ConnAbort 255 "NotAvailable" ;
VAL_ 2632777603 PGN_PktMsgTPCM_CTS 255 "NotAvailable" ;
VAL_ 2632777603 PGN_PktMsgTPCM_RTS 255 "NotAvailable" ;
VAL_ 2632777603 PGN_PktMsgTPCM_RTS2 255 "NotAvailable" ;
VAL_ 2632777603 CByteTPCM 16 "RTS" 17 "CTS" 19 "EoMA" 32 "BAM" 255 "Abort" ;
VAL_ 2565350016 PGN_Ack 65521 "Dataset Identific-DIS" 65228 "DM3Req" 65257 "FuelConsumption" 65242 "SOFT" 61184 "STOD" 65235 "DM11Req" 65520 "SecurityCheck" 65253 "EngHoursRevolutio" 65227 "DM2Req" ;
VAL_ 2565350016 PGN_NAck 65521 "Dataset Identific-DIS" 65228 "DM3Req" 65257 "FuelConsumption" 65242 "SOFT" 61184 "STOD" 65235 "DM11Req" 65520 "SecurityCheck" 65253 "EngHoursRevolutio" 65227 "DM2Req" ;
VAL_ 2565350016 PGN_NAckAd 65521 "Dataset Identific-DIS" 65228 "DM3Req" 65257 "FuelConsumption" 65242 "SOFT" 61184 "STOD" 65235 "DM11Req" 65520 "SecurityCheck" 65253 "EngHoursRevolutio" 65227 "DM2Req" ;
VAL_ 2565350016 PGN_NAckBusy 65521 "Dataset Identific-DIS" 65228 "DM3Req" 65257 "FuelConsumption" 65242 "SOFT" 61184 "STOD" 65235 "DM11Req" 65520 "SecurityCheck" 65253 "EngHoursRevolutio" 65227 "DM2Req" ;
VAL_ 2565350016 CByteAckm 3 "CannotRespond" 2 "AccessDenied" 1 "NACK" 0 "ACK" ;
VAL_ 2565350017 PGN_Ack 65521 "Dataset Identific-DIS" 65228 "DM3Req" 65257 "FuelConsumption" 65242 "SOFT" 61184 "STOD" 65235 "DM11Req" 65520 "SecurityCheck" 65253 "EngHoursRevolutio" 65227 "DM2Req" ;
VAL_ 2565350017 PGN_NAck 65521 "Dataset Identific-DIS" 65228 "DM3Req" 65257 "FuelConsumption" 65242 "SOFT" 61184 "STOD" 65235 "DM11Req" 65520 "SecurityCheck" 65253 "EngHoursRevolutio" 65227 "DM2Req" ;
VAL_ 2565350017 PGN_NAckAd 65521 "Dataset Identific-DIS" 65228 "DM3Req" 65257 "FuelConsumption" 65242 "SOFT" 61184 "STOD" 65235 "DM11Req" 65520 "SecurityCheck" 65253 "EngHoursRevolutio" 65227 "DM2Req" ;
VAL_ 2565350017 PGN_NAckBusy 65521 "Dataset Identific-DIS" 65228 "DM3Req" 65257 "FuelConsumption" 65242 "SOFT" 61184 "STOD" 65235 "DM11Req" 65520 "SecurityCheck" 65253 "EngHoursRevolutio" 65227 "DM2Req" ;
VAL_ 2565350017 CByteAckm 3 "CannotRespond" 2 "AccessDenied" 1 "NACK" 0 "ACK" ;
VAL_ 2565350018 PGN_Ack 65521 "Dataset Identific-DIS" 65228 "DM3Req" 65257 "FuelConsumption" 65242 "SOFT" 61184 "STOD" 65235 "DM11Req" 65520 "SecurityCheck" 65253 "EngHoursRevolutio" 65227 "DM2Req" ;
VAL_ 2565350018 PGN_NAck 65521 "Dataset Identific-DIS" 65228 "DM3Req" 65257 "FuelConsumption" 65242 "SOFT" 61184 "STOD" 65235 "DM11Req" 65520 "SecurityCheck" 65253 "EngHoursRevolutio" 65227 "DM2Req" ;
VAL_ 2565350018 PGN_NAckAd 65521 "Dataset Identific-DIS" 65228 "DM3Req" 65257 "FuelConsumption" 65242 "SOFT" 61184 "STOD" 65235 "DM11Req" 65520 "SecurityCheck" 65253 "EngHoursRevolutio" 65227 "DM2Req" ;
VAL_ 2565350018 PGN_NAckBusy 65521 "Dataset Identific-DIS" 65228 "DM3Req" 65257 "FuelConsumption" 65242 "SOFT" 61184 "STOD" 65235 "DM11Req" 65520 "SecurityCheck" 65253 "EngHoursRevolutio" 65227 "DM2Req" ;
VAL_ 2565350018 CByteAckm 3 "CannotRespond" 2 "AccessDenied" 1 "NACK" 0 "ACK" ;
VAL_ 2565350019 PGN_Ack 65521 "Dataset Identific-DIS" 65228 "DM3Req" 65257 "FuelConsumption" 65242 "SOFT" 61184 "STOD" 65235 "DM11Req" 65520 "SecurityCheck" 65253 "EngHoursRevolutio" 65227 "DM2Req" ;
VAL_ 2565350019 PGN_NAck 65521 "Dataset Identific-DIS" 65228 "DM3Req" 65257 "FuelConsumption" 65242 "SOFT" 61184 "STOD" 65235 "DM11Req" 65520 "SecurityCheck" 65253 "EngHoursRevolutio" 65227 "DM2Req" ;
VAL_ 2565350019 PGN_NAckAd 65521 "Dataset Identific-DIS" 65228 "DM3Req" 65257 "FuelConsumption" 65242 "SOFT" 61184 "STOD" 65235 "DM11Req" 65520 "SecurityCheck" 65253 "EngHoursRevolutio" 65227 "DM2Req" ;
VAL_ 2565350019 PGN_NAckBusy 65521 "Dataset Identific-DIS" 65228 "DM3Req" 65257 "FuelConsumption" 65242 "SOFT" 61184 "STOD" 65235 "DM11Req" 65520 "SecurityCheck" 65253 "EngHoursRevolutio" 65227 "DM2Req" ;
VAL_ 2565350019 CByteAckm 3 "CannotRespond" 2 "AccessDenied" 1 "NACK" 0 "ACK" ;
